[part 3 of 10: package /E40_Platform_System_SystemPackage/Components]
AUTOSAR XML (schema 4-2-1)
package /E40_Platform_System_SystemPackage/Components  (continued)
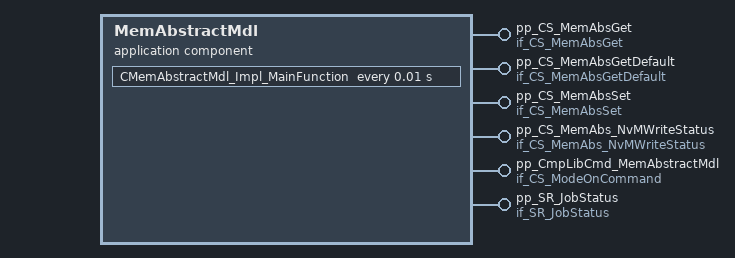
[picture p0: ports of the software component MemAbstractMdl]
  application sw component type MemAbstractMdl
    6 x provide port:
      pp_CS_MemAbsGet: provided-interface=if_CS_MemAbsGet
        provided-com-specs:
          operation=Get_BsConst_Audio_Element, queue-length=1
          operation=Get_BsConst_BsConst_Illumination_ReservedByte, queue-length=1
          operation=Get_BsConst_BsConst_Illumination_ReservedByte_SafeCopy1, queue-length=1
          operation=Get_BsConst_BsConst_Illumination_ReservedByte_SafeCopy2, queue-length=1
          operation=Get_BsConst_Communication_Element, queue-length=1
          operation=Get_BsConst_Compensation_Line_Shift_b, queue-length=1
          operation=Get_BsConst_Compensation_Line_Shift_b_SafeCopy1, queue-length=1
          operation=Get_BsConst_Compensation_Line_Shift_b_SafeCopy2, queue-length=1
          operation=Get_BsConst_Compensation_Line_Slope_m, queue-length=1
          operation=Get_BsConst_Compensation_Line_Slope_m_SafeCopy1, queue-length=1
          operation=Get_BsConst_Compensation_Line_Slope_m_SafeCopy2, queue-length=1
          operation=Get_BsConst_Derating_Backlight_Disable, queue-length=1
          operation=Get_BsConst_Derating_Backlight_Disable_SafeCopy1, queue-length=1
          operation=Get_BsConst_Derating_Backlight_Disable_SafeCopy2, queue-length=1
          operation=Get_BsConst_Display_Illum_Max_Level, queue-length=1
          operation=Get_BsConst_Display_Illum_Max_Level_SafeCopy1, queue-length=1
          operation=Get_BsConst_Display_Illum_Max_Level_SafeCopy2, queue-length=1
          operation=Get_BsConst_EngOffTimer_Element, queue-length=1
          operation=Get_BsConst_FuelGauge_Element, queue-length=1
          operation=Get_BsConst_Lookup_Curve_HotSpot_Coef_X, queue-length=1
          operation=Get_BsConst_Lookup_Curve_HotSpot_Coef_X_SafeCopy1, queue-length=1
          operation=Get_BsConst_Lookup_Curve_HotSpot_Coef_X_SafeCopy2, queue-length=1
          operation=Get_BsConst_Lookup_Curve_HotSpot_Coef_Y, queue-length=1
          operation=Get_BsConst_Lookup_Curve_HotSpot_Coef_Y_SafeCopy1, queue-length=1
          operation=Get_BsConst_Lookup_Curve_HotSpot_Coef_Y_SafeCopy2, queue-length=1
          operation=Get_BsConst_OilGauge_Element, queue-length=1
          operation=Get_BsConst_PCB_Temperature_Sensor_Conv, queue-length=1
          operation=Get_BsConst_PCB_Temperature_Sensor_Conv_SafeCopy1, queue-length=1
          operation=Get_BsConst_PCB_Temperature_Sensor_Conv_SafeCopy2, queue-length=1
          operation=Get_BsConst_PWM_boost_bypass_duty, queue-length=1
          operation=Get_BsConst_PWM_boost_bypass_duty_SafeCopy1, queue-length=1
          operation=Get_BsConst_PWM_boost_bypass_duty_SafeCopy2, queue-length=1
          operation=Get_BsConst_PowerGauge_Element, queue-length=1
          operation=Get_BsConst_Power_Element, queue-length=1
          operation=Get_BsConst_RealTimeClock_Element, queue-length=1
          operation=Get_BsConst_ServiceReminder_Element, queue-length=1
          operation=Get_BsConst_SpeedoGauge_Element, queue-length=1
          operation=Get_BsConst_TachoGauge_Element, queue-length=1
          operation=Get_BsConst_TempGauge_Element, queue-length=1
          operation=Get_BsConst_Temp_Threshold_Hysteresis_Derating, queue-length=1
          operation=Get_BsConst_Temp_Threshold_Hysteresis_Derating_SafeCopy1, queue-length=1
          operation=Get_BsConst_Temp_Threshold_Hysteresis_Derating_SafeCopy2, queue-length=1
          operation=Get_BsConst_Temperature_Sensor_Conv, queue-length=1
          operation=Get_BsConst_Temperature_Sensor_Conv_SafeCopy1, queue-length=1
          operation=Get_BsConst_Temperature_Sensor_Conv_SafeCopy2, queue-length=1
          operation=Get_BsConst_TripComputer_Element, queue-length=1
          operation=Get_BsConst_Warning_Element, queue-length=1
          operation=Get_BsCys_Certicificate_Element, queue-length=1
          operation=Get_BsDiag_Dtc_Element, queue-length=1
          operation=Get_BsDiag_ErrorRecord_Element, queue-length=1
          operation=Get_BsReten_Audio_Element, queue-length=1
          operation=Get_BsReten_Communication_Element, queue-length=1
          operation=Get_BsReten_Display_Element, queue-length=1
          operation=Get_BsReten_Gauges_Element, queue-length=1
          operation=Get_BsReten_Illumination_Element, queue-length=1
          operation=Get_BsReten_Odometer_Element, queue-length=1
          operation=Get_BsReten_Personalization_Element, queue-length=1
          operation=Get_BsReten_Power_Element, queue-length=1
          operation=Get_BsReten_RealTimeClock_Element, queue-length=1
          operation=Get_BsReten_Tripcomputer_Element, queue-length=1
          operation=Get_BsReten_VisDlt_Element, queue-length=1
          operation=Get_BsReten_Warning_Element, queue-length=1
          operation=Get_BsRt_CusDlt_Element, queue-length=1
          operation=Get_BsRt_FuelGauge_Element, queue-length=1
          operation=Get_BsRt_Illumination_Element, queue-length=1
          operation=Get_BsRt_Odometer_Element, queue-length=1
          operation=Get_BsRt_OilGauge_Element, queue-length=1
          operation=Get_BsRt_Personalization_Element, queue-length=1
          operation=Get_BsRt_PowerGauge_Element, queue-length=1
          operation=Get_BsRt_RealTimeClock_Element, queue-length=1
          operation=Get_BsRt_SpeedoGauge_Element, queue-length=1
          operation=Get_BsRt_TachoGauge_Element, queue-length=1
          operation=Get_BsRt_TempGauge_Element, queue-length=1
          operation=Get_BsRt_TripComputer_Element, queue-length=1
          operation=Get_BsRt_Warning_Element, queue-length=1
          operation=Get_BsShare_AssemblyManufacturingDate, queue-length=1
          operation=Get_BsShare_AssemblyPlantNumber, queue-length=1
          operation=Get_BsShare_EcuPartNumber_Element, queue-length=1
          operation=Get_BsShare_HWModification, queue-length=1
          operation=Get_BsShare_PCBSerialNumber, queue-length=1
          operation=Get_BsShare_ProductSerialNumber, queue-length=1
          operation=Get_BsShare_SMTManufacturingDate, queue-length=1
          operation=Get_BsShare_SMTPlantNumber, queue-length=1
          operation=Get_BsShare_SwUpdFotaFinPrint_Element, queue-length=1
          operation=Get_BsShare_SwUpdFotaMode_Element, queue-length=1
          operation=Get_BsShare_SwUpdFotaStatus_Element, queue-length=1
          operation=Get_BsShare_SwUpdFotadecrypt_Element, queue-length=1
          operation=Get_BsShare_SwUpdReflash_Element, queue-length=1
          operation=Get_BsShare_VehicleConfig_Element, queue-length=1
          operation=Get_BsShare_VisMeet_EOLEntry_Element, queue-length=1
          operation=Get_BsShare_VisMeet_Element, queue-length=1
          operation=Get_BsShare_VisteonPCBPartNumber, queue-length=1
          operation=Get_BsShare_VisteonPartNumber, queue-length=1
          operation=Get_RefCys_Certicificate1_Element, queue-length=1
          operation=Get_RefCys_Certicificate_Element, queue-length=1
      pp_CS_MemAbsGetDefault: provided-interface=if_CS_MemAbsGetDefault
        provided-com-specs:
          operation=Get_Default_BsConst_Audio_Element, queue-length=1
          operation=Get_Default_BsConst_BsConst_Illumination_ReservedByte, queue-length=1
          operation=Get_Default_BsConst_BsConst_Illumination_ReservedByte_SafeCopy1, queue-length=1
          operation=Get_Default_BsConst_BsConst_Illumination_ReservedByte_SafeCopy2, queue-length=1
          operation=Get_Default_BsConst_Communication_Element, queue-length=1
          operation=Get_Default_BsConst_Compensation_Line_Shift_b, queue-length=1
          operation=Get_Default_BsConst_Compensation_Line_Shift_b_SafeCopy1, queue-length=1
          operation=Get_Default_BsConst_Compensation_Line_Shift_b_SafeCopy2, queue-length=1
          operation=Get_Default_BsConst_Compensation_Line_Slope_m, queue-length=1
          operation=Get_Default_BsConst_Compensation_Line_Slope_m_SafeCopy1, queue-length=1
          operation=Get_Default_BsConst_Compensation_Line_Slope_m_SafeCopy2, queue-length=1
          operation=Get_Default_BsConst_Derating_Backlight_Disable, queue-length=1
          operation=Get_Default_BsConst_Derating_Backlight_Disable_SafeCopy1, queue-length=1
          operation=Get_Default_BsConst_Derating_Backlight_Disable_SafeCopy2, queue-length=1
          operation=Get_Default_BsConst_Display_Illum_Max_Level, queue-length=1
          operation=Get_Default_BsConst_Display_Illum_Max_Level_SafeCopy1, queue-length=1
          operation=Get_Default_BsConst_Display_Illum_Max_Level_SafeCopy2, queue-length=1
          operation=Get_Default_BsConst_EngOffTimer_Element, queue-length=1
          operation=Get_Default_BsConst_FuelGauge_Element, queue-length=1
          operation=Get_Default_BsConst_Lookup_Curve_HotSpot_Coef_X, queue-length=1
          operation=Get_Default_BsConst_Lookup_Curve_HotSpot_Coef_X_SafeCopy1, queue-length=1
          operation=Get_Default_BsConst_Lookup_Curve_HotSpot_Coef_X_SafeCopy2, queue-length=1
          operation=Get_Default_BsConst_Lookup_Curve_HotSpot_Coef_Y, queue-length=1
          operation=Get_Default_BsConst_Lookup_Curve_HotSpot_Coef_Y_SafeCopy1, queue-length=1
          operation=Get_Default_BsConst_Lookup_Curve_HotSpot_Coef_Y_SafeCopy2, queue-length=1
          operation=Get_Default_BsConst_OilGauge_Element, queue-length=1
          operation=Get_Default_BsConst_PCB_Temperature_Sensor_Conv, queue-length=1
          operation=Get_Default_BsConst_PCB_Temperature_Sensor_Conv_SafeCopy1, queue-length=1
          operation=Get_Default_BsConst_PCB_Temperature_Sensor_Conv_SafeCopy2, queue-length=1
          operation=Get_Default_BsConst_PWM_boost_bypass_duty, queue-length=1
          operation=Get_Default_BsConst_PWM_boost_bypass_duty_SafeCopy1, queue-length=1
          operation=Get_Default_BsConst_PWM_boost_bypass_duty_SafeCopy2, queue-length=1
          operation=Get_Default_BsConst_PowerGauge_Element, queue-length=1
          operation=Get_Default_BsConst_Power_Element, queue-length=1
          operation=Get_Default_BsConst_RealTimeClock_Element, queue-length=1
          operation=Get_Default_BsConst_ServiceReminder_Element, queue-length=1
          operation=Get_Default_BsConst_SpeedoGauge_Element, queue-length=1
          operation=Get_Default_BsConst_TachoGauge_Element, queue-length=1
          operation=Get_Default_BsConst_TempGauge_Element, queue-length=1
          operation=Get_Default_BsConst_Temp_Threshold_Hysteresis_Derating, queue-length=1
          operation=Get_Default_BsConst_Temp_Threshold_Hysteresis_Derating_SafeCopy1, queue-length=1
          operation=Get_Default_BsConst_Temp_Threshold_Hysteresis_Derating_SafeCopy2, queue-length=1
          operation=Get_Default_BsConst_Temperature_Sensor_Conv, queue-length=1
          operation=Get_Default_BsConst_Temperature_Sensor_Conv_SafeCopy1, queue-length=1
          operation=Get_Default_BsConst_Temperature_Sensor_Conv_SafeCopy2, queue-length=1
          operation=Get_Default_BsConst_TripComputer_Element, queue-length=1
          operation=Get_Default_BsConst_Warning_Element, queue-length=1
          operation=Get_Default_BsCys_Certicificate_Element, queue-length=1
          operation=Get_Default_BsDiag_Dtc_Element, queue-length=1
          operation=Get_Default_BsDiag_ErrorRecord_Element, queue-length=1
          operation=Get_Default_BsReten_Audio_Element, queue-length=1
          operation=Get_Default_BsReten_Communication_Element, queue-length=1
          operation=Get_Default_BsReten_Display_Element, queue-length=1
          operation=Get_Default_BsReten_Gauges_Element, queue-length=1
          operation=Get_Default_BsReten_Illumination_Element, queue-length=1
          operation=Get_Default_BsReten_Odometer_Element, queue-length=1
          operation=Get_Default_BsReten_Personalization_Element, queue-length=1
          operation=Get_Default_BsReten_Power_Element, queue-length=1
          operation=Get_Default_BsReten_RealTimeClock_Element, queue-length=1
          operation=Get_Default_BsReten_Tripcomputer_Element, queue-length=1
          operation=Get_Default_BsReten_VisDlt_Element, queue-length=1
          operation=Get_Default_BsReten_Warning_Element, queue-length=1
          operation=Get_Default_BsRt_CusDlt_Element, queue-length=1
          operation=Get_Default_BsRt_FuelGauge_Element, queue-length=1
          operation=Get_Default_BsRt_Illumination_Element, queue-length=1
          operation=Get_Default_BsRt_Odometer_Element, queue-length=1
          operation=Get_Default_BsRt_OilGauge_Element, queue-length=1
          operation=Get_Default_BsRt_Personalization_Element, queue-length=1
          operation=Get_Default_BsRt_PowerGauge_Element, queue-length=1
          operation=Get_Default_BsRt_RealTimeClock_Element, queue-length=1
          operation=Get_Default_BsRt_SpeedoGauge_Element, queue-length=1
          operation=Get_Default_BsRt_TachoGauge_Element, queue-length=1
          operation=Get_Default_BsRt_TempGauge_Element, queue-length=1
          operation=Get_Default_BsRt_TripComputer_Element, queue-length=1
          operation=Get_Default_BsRt_Warning_Element, queue-length=1
          operation=Get_Default_BsShare_AssemblyManufacturingDate, queue-length=1
          operation=Get_Default_BsShare_AssemblyPlantNumber, queue-length=1
          operation=Get_Default_BsShare_EcuPartNumber_Element, queue-length=1
          operation=Get_Default_BsShare_HWModification, queue-length=1
          operation=Get_Default_BsShare_PCBSerialNumber, queue-length=1
          operation=Get_Default_BsShare_ProductSerialNumber, queue-length=1
          operation=Get_Default_BsShare_SMTManufacturingDate, queue-length=1
          operation=Get_Default_BsShare_SMTPlantNumber, queue-length=1
          operation=Get_Default_BsShare_SwUpdFotaFinPrint_Element, queue-length=1
          operation=Get_Default_BsShare_SwUpdFotaMode_Element, queue-length=1
          operation=Get_Default_BsShare_SwUpdFotaStatus_Element, queue-length=1
          operation=Get_Default_BsShare_SwUpdFotadecrypt_Element, queue-length=1
          operation=Get_Default_BsShare_SwUpdReflash_Element, queue-length=1
          operation=Get_Default_BsShare_VehicleConfig_Element, queue-length=1
          operation=Get_Default_BsShare_VisMeet_EOLEntry_Element, queue-length=1
          operation=Get_Default_BsShare_VisMeet_Element, queue-length=1
          operation=Get_Default_BsShare_VisteonPCBPartNumber, queue-length=1
          operation=Get_Default_BsShare_VisteonPartNumber, queue-length=1
          operation=Get_Default_RefCys_Certicificate1_Element, queue-length=1
          operation=Get_Default_RefCys_Certicificate_Element, queue-length=1
      pp_CS_MemAbsSet: provided-interface=if_CS_MemAbsSet
        provided-com-specs:
          operation=Set_BsConst_Audio_Element, queue-length=1
          operation=Set_BsConst_BsConst_Illumination_ReservedByte, queue-length=1
          operation=Set_BsConst_BsConst_Illumination_ReservedByte_SafeCopy1, queue-length=1
          operation=Set_BsConst_BsConst_Illumination_ReservedByte_SafeCopy2, queue-length=1
          operation=Set_BsConst_Communication_Element, queue-length=1
          operation=Set_BsConst_Compensation_Line_Shift_b, queue-length=1
          operation=Set_BsConst_Compensation_Line_Shift_b_SafeCopy1, queue-length=1
          operation=Set_BsConst_Compensation_Line_Shift_b_SafeCopy2, queue-length=1
          operation=Set_BsConst_Compensation_Line_Slope_m, queue-length=1
          operation=Set_BsConst_Compensation_Line_Slope_m_SafeCopy1, queue-length=1
          operation=Set_BsConst_Compensation_Line_Slope_m_SafeCopy2, queue-length=1
          operation=Set_BsConst_Derating_Backlight_Disable, queue-length=1
          operation=Set_BsConst_Derating_Backlight_Disable_SafeCopy1, queue-length=1
          operation=Set_BsConst_Derating_Backlight_Disable_SafeCopy2, queue-length=1
          operation=Set_BsConst_Display_Illum_Max_Level, queue-length=1
          operation=Set_BsConst_Display_Illum_Max_Level_SafeCopy1, queue-length=1
          operation=Set_BsConst_Display_Illum_Max_Level_SafeCopy2, queue-length=1
          operation=Set_BsConst_EngOffTimer_Element, queue-length=1
          operation=Set_BsConst_FuelGauge_Element, queue-length=1
          operation=Set_BsConst_Lookup_Curve_HotSpot_Coef_X, queue-length=1
          operation=Set_BsConst_Lookup_Curve_HotSpot_Coef_X_SafeCopy1, queue-length=1
          operation=Set_BsConst_Lookup_Curve_HotSpot_Coef_X_SafeCopy2, queue-length=1
          operation=Set_BsConst_Lookup_Curve_HotSpot_Coef_Y, queue-length=1
          operation=Set_BsConst_Lookup_Curve_HotSpot_Coef_Y_SafeCopy1, queue-length=1
          operation=Set_BsConst_Lookup_Curve_HotSpot_Coef_Y_SafeCopy2, queue-length=1
          operation=Set_BsConst_OilGauge_Element, queue-length=1
          operation=Set_BsConst_PCB_Temperature_Sensor_Conv, queue-length=1
          operation=Set_BsConst_PCB_Temperature_Sensor_Conv_SafeCopy1, queue-length=1
          operation=Set_BsConst_PCB_Temperature_Sensor_Conv_SafeCopy2, queue-length=1
          operation=Set_BsConst_PWM_boost_bypass_duty, queue-length=1
          operation=Set_BsConst_PWM_boost_bypass_duty_SafeCopy1, queue-length=1
          operation=Set_BsConst_PWM_boost_bypass_duty_SafeCopy2, queue-length=1
          operation=Set_BsConst_PowerGauge_Element, queue-length=1
          operation=Set_BsConst_Power_Element, queue-length=1
          operation=Set_BsConst_RealTimeClock_Element, queue-length=1
          operation=Set_BsConst_ServiceReminder_Element, queue-length=1
          operation=Set_BsConst_SpeedoGauge_Element, queue-length=1
          operation=Set_BsConst_TachoGauge_Element, queue-length=1
          operation=Set_BsConst_TempGauge_Element, queue-length=1
          operation=Set_BsConst_Temp_Threshold_Hysteresis_Derating, queue-length=1
          operation=Set_BsConst_Temp_Threshold_Hysteresis_Derating_SafeCopy1, queue-length=1
          operation=Set_BsConst_Temp_Threshold_Hysteresis_Derating_SafeCopy2, queue-length=1
          operation=Set_BsConst_Temperature_Sensor_Conv, queue-length=1
          operation=Set_BsConst_Temperature_Sensor_Conv_SafeCopy1, queue-length=1
          operation=Set_BsConst_Temperature_Sensor_Conv_SafeCopy2, queue-length=1
          operation=Set_BsConst_TripComputer_Element, queue-length=1
          operation=Set_BsConst_Warning_Element, queue-length=1
          operation=Set_BsCys_Certicificate_Element, queue-length=1
          operation=Set_BsDiag_Dtc_Element, queue-length=1
          operation=Set_BsDiag_ErrorRecord_Element, queue-length=1
          operation=Set_BsReten_Audio_Element, queue-length=1
          operation=Set_BsReten_Communication_Element, queue-length=1
          operation=Set_BsReten_Display_Element, queue-length=1
          operation=Set_BsReten_Gauges_Element, queue-length=1
          operation=Set_BsReten_Illumination_Element, queue-length=1
          operation=Set_BsReten_Odometer_Element, queue-length=1
          operation=Set_BsReten_Personalization_Element, queue-length=1
          operation=Set_BsReten_Power_Element, queue-length=1
          operation=Set_BsReten_RealTimeClock_Element, queue-length=1
          operation=Set_BsReten_Tripcomputer_Element, queue-length=1
          operation=Set_BsReten_VisDlt_Element, queue-length=1
          operation=Set_BsReten_Warning_Element, queue-length=1
          operation=Set_BsRt_CusDlt_Element, queue-length=1
          operation=Set_BsRt_FuelGauge_Element, queue-length=1
          operation=Set_BsRt_Illumination_Element, queue-length=1
          operation=Set_BsRt_Odometer_Element, queue-length=1
          operation=Set_BsRt_OilGauge_Element, queue-length=1
          operation=Set_BsRt_Personalization_Element, queue-length=1
          operation=Set_BsRt_PowerGauge_Element, queue-length=1
          operation=Set_BsRt_RealTimeClock_Element, queue-length=1
          operation=Set_BsRt_SpeedoGauge_Element, queue-length=1
          operation=Set_BsRt_TachoGauge_Element, queue-length=1
          operation=Set_BsRt_TempGauge_Element, queue-length=1
          operation=Set_BsRt_TripComputer_Element, queue-length=1
          operation=Set_BsRt_Warning_Element, queue-length=1
          operation=Set_BsShare_AssemblyManufacturingDate, queue-length=1
          operation=Set_BsShare_AssemblyPlantNumber, queue-length=1
          operation=Set_BsShare_EcuPartNumber_Element, queue-length=1
          operation=Set_BsShare_HWModification, queue-length=1
          operation=Set_BsShare_PCBSerialNumber, queue-length=1
          operation=Set_BsShare_ProductSerialNumber, queue-length=1
          operation=Set_BsShare_SMTManufacturingDate, queue-length=1
          operation=Set_BsShare_SMTPlantNumber, queue-length=1
          operation=Set_BsShare_SwUpdFotaFinPrint_Element, queue-length=1
          operation=Set_BsShare_SwUpdFotaMode_Element, queue-length=1
          operation=Set_BsShare_SwUpdFotaStatus_Element, queue-length=1
          operation=Set_BsShare_SwUpdFotadecrypt_Element, queue-length=1
          operation=Set_BsShare_SwUpdReflash_Element, queue-length=1
          operation=Set_BsShare_VehicleConfig_Element, queue-length=1
          operation=Set_BsShare_VisMeet_EOLEntry_Element, queue-length=1
          operation=Set_BsShare_VisMeet_Element, queue-length=1
          operation=Set_BsShare_VisteonPCBPartNumber, queue-length=1
          operation=Set_BsShare_VisteonPartNumber, queue-length=1
          operation=Set_RefCys_Certicificate1_Element, queue-length=1
          operation=Set_RefCys_Certicificate_Element, queue-length=1
      pp_CS_MemAbs_NvMWriteStatus: server-com-spec{operation=NvmWriteStatus, queue-length=1}, provided-interface=if_CS_MemAbs_NvMWriteStatus
      pp_CmpLibCmd_MemAbstractMdl: server-com-spec{operation=Impl_OnCommand, queue-length=1}, provided-interface=if_CS_ModeOnCommand
      pp_SR_JobStatus: provided-interface=if_SR_JobStatus
        provided-com-specs:
          data-element=JobStatus_BsConst_Audio_Element, init-value=constant-reference=MemAbstractMdlJobStatus_BsConst_Audio_ElementValue0
          data-element=JobStatus_BsConst_BsConst_Illumination_ReservedByte, init-value=constant-reference=MemAbstractMdlJobStatus_BsConst_BsConst_Illumination_ReservedByteValue0
          data-element=JobStatus_BsConst_BsConst_Illumination_ReservedByte_SafeCopy1, init-value=constant-reference=MemAbstractMdlJobStatus_BsConst_BsConst_Illumination_ReservedByte_SafeCopy1Value0
          data-element=JobStatus_BsConst_BsConst_Illumination_ReservedByte_SafeCopy2, init-value=constant-reference=MemAbstractMdlJobStatus_BsConst_BsConst_Illumination_ReservedByte_SafeCopy2Value0
          data-element=JobStatus_BsConst_Communication_Element, init-value=constant-reference=MemAbstractMdlJobStatus_BsConst_Communication_ElementValue0
          data-element=JobStatus_BsConst_Compensation_Line_Shift_b, init-value=constant-reference=MemAbstractMdlJobStatus_BsConst_Compensation_Line_Shift_bValue0
          data-element=JobStatus_BsConst_Compensation_Line_Shift_b_SafeCopy1, init-value=constant-reference=MemAbstractMdlJobStatus_BsConst_Compensation_Line_Shift_b_SafeCopy1Value0
          data-element=JobStatus_BsConst_Compensation_Line_Shift_b_SafeCopy2, init-value=constant-reference=MemAbstractMdlJobStatus_BsConst_Compensation_Line_Shift_b_SafeCopy2Value0
          data-element=JobStatus_BsConst_Compensation_Line_Slope_m, init-value=constant-reference=MemAbstractMdlJobStatus_BsConst_Compensation_Line_Slope_mValue0
          data-element=JobStatus_BsConst_Compensation_Line_Slope_m_SafeCopy1, init-value=constant-reference=MemAbstractMdlJobStatus_BsConst_Compensation_Line_Slope_m_SafeCopy1Value0
          data-element=JobStatus_BsConst_Compensation_Line_Slope_m_SafeCopy2, init-value=constant-reference=MemAbstractMdlJobStatus_BsConst_Compensation_Line_Slope_m_SafeCopy2Value0
          data-element=JobStatus_BsConst_Derating_Backlight_Disable, init-value=constant-reference=MemAbstractMdlJobStatus_BsConst_Derating_Backlight_DisableValue0
          data-element=JobStatus_BsConst_Derating_Backlight_Disable_SafeCopy1, init-value=constant-reference=MemAbstractMdlJobStatus_BsConst_Derating_Backlight_Disable_SafeCopy1Value0
          data-element=JobStatus_BsConst_Derating_Backlight_Disable_SafeCopy2, init-value=constant-reference=MemAbstractMdlJobStatus_BsConst_Derating_Backlight_Disable_SafeCopy2Value0
          data-element=JobStatus_BsConst_Display_Illum_Max_Level, init-value=constant-reference=MemAbstractMdlJobStatus_BsConst_Display_Illum_Max_LevelValue0
          data-element=JobStatus_BsConst_Display_Illum_Max_Level_SafeCopy1, init-value=constant-reference=MemAbstractMdlJobStatus_BsConst_Display_Illum_Max_Level_SafeCopy1Value0
          data-element=JobStatus_BsConst_Display_Illum_Max_Level_SafeCopy2, init-value=constant-reference=MemAbstractMdlJobStatus_BsConst_Display_Illum_Max_Level_SafeCopy2Value0
          data-element=JobStatus_BsConst_EngOffTimer_Element, init-value=constant-reference=MemAbstractMdlJobStatus_BsConst_EngOffTimer_ElementValue0
          data-element=JobStatus_BsConst_FuelGauge_Element, init-value=constant-reference=MemAbstractMdlJobStatus_BsConst_FuelGauge_ElementValue0
          data-element=JobStatus_BsConst_Lookup_Curve_HotSpot_Coef_X, init-value=constant-reference=MemAbstractMdlJobStatus_BsConst_Lookup_Curve_HotSpot_Coef_XValue0
          data-element=JobStatus_BsConst_Lookup_Curve_HotSpot_Coef_X_SafeCopy1, init-value=constant-reference=MemAbstractMdlJobStatus_BsConst_Lookup_Curve_HotSpot_Coef_X_SafeCopy1Value0
          data-element=JobStatus_BsConst_Lookup_Curve_HotSpot_Coef_X_SafeCopy2, init-value=constant-reference=MemAbstractMdlJobStatus_BsConst_Lookup_Curve_HotSpot_Coef_X_SafeCopy2Value0
          data-element=JobStatus_BsConst_Lookup_Curve_HotSpot_Coef_Y, init-value=constant-reference=MemAbstractMdlJobStatus_BsConst_Lookup_Curve_HotSpot_Coef_YValue0
          data-element=JobStatus_BsConst_Lookup_Curve_HotSpot_Coef_Y_SafeCopy1, init-value=constant-reference=MemAbstractMdlJobStatus_BsConst_Lookup_Curve_HotSpot_Coef_Y_SafeCopy1Value0
          data-element=JobStatus_BsConst_Lookup_Curve_HotSpot_Coef_Y_SafeCopy2, init-value=constant-reference=MemAbstractMdlJobStatus_BsConst_Lookup_Curve_HotSpot_Coef_Y_SafeCopy2Value0
          data-element=JobStatus_BsConst_OilGauge_Element, init-value=constant-reference=MemAbstractMdlJobStatus_BsConst_OilGauge_ElementValue0
          data-element=JobStatus_BsConst_PCB_Temperature_Sensor_Conv, init-value=constant-reference=MemAbstractMdlJobStatus_BsConst_PCB_Temperature_Sensor_ConvValue0
          data-element=JobStatus_BsConst_PCB_Temperature_Sensor_Conv_SafeCopy1, init-value=constant-reference=MemAbstractMdlJobStatus_BsConst_PCB_Temperature_Sensor_Conv_SafeCopy1Value0
          data-element=JobStatus_BsConst_PCB_Temperature_Sensor_Conv_SafeCopy2, init-value=constant-reference=MemAbstractMdlJobStatus_BsConst_PCB_Temperature_Sensor_Conv_SafeCopy2Value0
          data-element=JobStatus_BsConst_PWM_boost_bypass_duty, init-value=constant-reference=MemAbstractMdlJobStatus_BsConst_PWM_boost_bypass_dutyValue0
          data-element=JobStatus_BsConst_PWM_boost_bypass_duty_SafeCopy1, init-value=constant-reference=MemAbstractMdlJobStatus_BsConst_PWM_boost_bypass_duty_SafeCopy1Value0
          data-element=JobStatus_BsConst_PWM_boost_bypass_duty_SafeCopy2, init-value=constant-reference=MemAbstractMdlJobStatus_BsConst_PWM_boost_bypass_duty_SafeCopy2Value0
          data-element=JobStatus_BsConst_PowerGauge_Element, init-value=constant-reference=MemAbstractMdlJobStatus_BsConst_PowerGauge_ElementValue0
          data-element=JobStatus_BsConst_Power_Element, init-value=constant-reference=MemAbstractMdlJobStatus_BsConst_Power_ElementValue0
          data-element=JobStatus_BsConst_RealTimeClock_Element, init-value=constant-reference=MemAbstractMdlJobStatus_BsConst_RealTimeClock_ElementValue0
          data-element=JobStatus_BsConst_ServiceReminder_Element, init-value=constant-reference=MemAbstractMdlJobStatus_BsConst_ServiceReminder_ElementValue0
          data-element=JobStatus_BsConst_SpeedoGauge_Element, init-value=constant-reference=MemAbstractMdlJobStatus_BsConst_SpeedoGauge_ElementValue0
          data-element=JobStatus_BsConst_TachoGauge_Element, init-value=constant-reference=MemAbstractMdlJobStatus_BsConst_TachoGauge_ElementValue0
          data-element=JobStatus_BsConst_TempGauge_Element, init-value=constant-reference=MemAbstractMdlJobStatus_BsConst_TempGauge_ElementValue0
          data-element=JobStatus_BsConst_Temp_Threshold_Hysteresis_Derating, init-value=constant-reference=MemAbstractMdlJobStatus_BsConst_Temp_Threshold_Hysteresis_DeratingValue0
          data-element=JobStatus_BsConst_Temp_Threshold_Hysteresis_Derating_SafeCopy1, init-value=constant-reference=MemAbstractMdlJobStatus_BsConst_Temp_Threshold_Hysteresis_Derating_SafeCopy1Value0
          data-element=JobStatus_BsConst_Temp_Threshold_Hysteresis_Derating_SafeCopy2, init-value=constant-reference=MemAbstractMdlJobStatus_BsConst_Temp_Threshold_Hysteresis_Derating_SafeCopy2Value0
          data-element=JobStatus_BsConst_Temperature_Sensor_Conv, init-value=constant-reference=MemAbstractMdlJobStatus_BsConst_Temperature_Sensor_ConvValue0
          data-element=JobStatus_BsConst_Temperature_Sensor_Conv_SafeCopy1, init-value=constant-reference=MemAbstractMdlJobStatus_BsConst_Temperature_Sensor_Conv_SafeCopy1Value0
          data-element=JobStatus_BsConst_Temperature_Sensor_Conv_SafeCopy2, init-value=constant-reference=MemAbstractMdlJobStatus_BsConst_Temperature_Sensor_Conv_SafeCopy2Value0
          data-element=JobStatus_BsConst_TripComputer_Element, init-value=constant-reference=MemAbstractMdlJobStatus_BsConst_TripComputer_ElementValue0
          data-element=JobStatus_BsConst_Warning_Element, init-value=constant-reference=MemAbstractMdlJobStatus_BsConst_Warning_ElementValue0
          data-element=JobStatus_BsCys_Certicificate_Element, init-value=constant-reference=MemAbstractMdlJobStatus_BsCys_Certicificate_ElementValue0
          data-element=JobStatus_BsDiag_Dtc_Element, init-value=constant-reference=MemAbstractMdlJobStatus_BsDiag_Dtc_ElementValue0
          data-element=JobStatus_BsDiag_ErrorRecord_Element, init-value=constant-reference=MemAbstractMdlJobStatus_BsDiag_ErrorRecord_ElementValue0
          data-element=JobStatus_BsReten_Audio_Element, init-value=constant-reference=MemAbstractMdlJobStatus_BsReten_Audio_ElementValue0
          data-element=JobStatus_BsReten_Communication_Element, init-value=constant-reference=MemAbstractMdlJobStatus_BsReten_Communication_ElementValue0
          data-element=JobStatus_BsReten_Display_Element, init-value=constant-reference=MemAbstractMdlJobStatus_BsReten_Display_ElementValue0
          data-element=JobStatus_BsReten_Gauges_Element, init-value=constant-reference=MemAbstractMdlJobStatus_BsReten_Gauges_ElementValue0
          data-element=JobStatus_BsReten_Illumination_Element, init-value=constant-reference=MemAbstractMdlJobStatus_BsReten_Illumination_ElementValue0
          data-element=JobStatus_BsReten_Odometer_Element, init-value=constant-reference=MemAbstractMdlJobStatus_BsReten_Odometer_ElementValue0
          data-element=JobStatus_BsReten_Personalization_Element, init-value=constant-reference=MemAbstractMdlJobStatus_BsReten_Personalization_ElementValue0
          data-element=JobStatus_BsReten_Power_Element, init-value=constant-reference=MemAbstractMdlJobStatus_BsReten_Power_ElementValue0
          data-element=JobStatus_BsReten_RealTimeClock_Element, init-value=constant-reference=MemAbstractMdlJobStatus_BsReten_RealTimeClock_ElementValue0
          data-element=JobStatus_BsReten_Tripcomputer_Element, init-value=constant-reference=MemAbstractMdlJobStatus_BsReten_Tripcomputer_ElementValue0
          data-element=JobStatus_BsReten_VisDlt_Element, init-value=constant-reference=MemAbstractMdlJobStatus_BsReten_VisDlt_ElementValue0
          data-element=JobStatus_BsReten_Warning_Element, init-value=constant-reference=MemAbstractMdlJobStatus_BsReten_Warning_ElementValue0
          data-element=JobStatus_BsRt_CusDlt_Element, init-value=constant-reference=MemAbstractMdlJobStatus_BsRt_CusDlt_ElementValue0
          data-element=JobStatus_BsRt_FuelGauge_Element, init-value=constant-reference=MemAbstractMdlJobStatus_BsRt_FuelGauge_ElementValue0
          data-element=JobStatus_BsRt_Illumination_Element, init-value=constant-reference=MemAbstractMdlJobStatus_BsRt_Illumination_ElementValue0
          data-element=JobStatus_BsRt_Odometer_Element, init-value=constant-reference=MemAbstractMdlJobStatus_BsRt_Odometer_ElementValue0
          data-element=JobStatus_BsRt_OilGauge_Element, init-value=constant-reference=MemAbstractMdlJobStatus_BsRt_OilGauge_ElementValue0
          data-element=JobStatus_BsRt_Personalization_Element, init-value=constant-reference=MemAbstractMdlJobStatus_BsRt_Personalization_ElementValue0
          data-element=JobStatus_BsRt_PowerGauge_Element, init-value=constant-reference=MemAbstractMdlJobStatus_BsRt_PowerGauge_ElementValue0
          data-element=JobStatus_BsRt_RealTimeClock_Element, init-value=constant-reference=MemAbstractMdlJobStatus_BsRt_RealTimeClock_ElementValue0
          data-element=JobStatus_BsRt_SpeedoGauge_Element, init-value=constant-reference=MemAbstractMdlJobStatus_BsRt_SpeedoGauge_ElementValue0
          data-element=JobStatus_BsRt_TachoGauge_Element, init-value=constant-reference=MemAbstractMdlJobStatus_BsRt_TachoGauge_ElementValue0
          data-element=JobStatus_BsRt_TempGauge_Element, init-value=constant-reference=MemAbstractMdlJobStatus_BsRt_TempGauge_ElementValue0
          data-element=JobStatus_BsRt_TripComputer_Element, init-value=constant-reference=MemAbstractMdlJobStatus_BsRt_TripComputer_ElementValue0
          data-element=JobStatus_BsRt_Warning_Element, init-value=constant-reference=MemAbstractMdlJobStatus_BsRt_Warning_ElementValue0
          data-element=JobStatus_BsShare_AssemblyManufacturingDate, init-value=constant-reference=MemAbstractMdlJobStatus_BsShare_AssemblyManufacturingDateValue0
          data-element=JobStatus_BsShare_AssemblyPlantNumber, init-value=constant-reference=MemAbstractMdlJobStatus_BsShare_AssemblyPlantNumberValue0
          data-element=JobStatus_BsShare_EcuPartNumber_Element, init-value=constant-reference=MemAbstractMdlJobStatus_BsShare_EcuPartNumber_ElementValue0
          data-element=JobStatus_BsShare_HWModification, init-value=constant-reference=MemAbstractMdlJobStatus_BsShare_HWModificationValue0
          data-element=JobStatus_BsShare_PCBSerialNumber, init-value=constant-reference=MemAbstractMdlJobStatus_BsShare_PCBSerialNumberValue0
          data-element=JobStatus_BsShare_ProductSerialNumber, init-value=constant-reference=MemAbstractMdlJobStatus_BsShare_ProductSerialNumberValue0
          data-element=JobStatus_BsShare_SMTManufacturingDate, init-value=constant-reference=MemAbstractMdlJobStatus_BsShare_SMTManufacturingDateValue0
          data-element=JobStatus_BsShare_SMTPlantNumber, init-value=constant-reference=MemAbstractMdlJobStatus_BsShare_SMTPlantNumberValue0
          data-element=JobStatus_BsShare_SwUpdFotaFinPrint_Element, init-value=constant-reference=MemAbstractMdlJobStatus_BsShare_SwUpdFotaFinPrint_ElementValue0
          data-element=JobStatus_BsShare_SwUpdFotaMode_Element, init-value=constant-reference=MemAbstractMdlJobStatus_BsShare_SwUpdFotaMode_ElementValue0
          data-element=JobStatus_BsShare_SwUpdFotaStatus_Element, init-value=constant-reference=MemAbstractMdlJobStatus_BsShare_SwUpdFotaStatus_ElementValue0
          data-element=JobStatus_BsShare_SwUpdFotadecrypt_Element, init-value=constant-reference=MemAbstractMdlJobStatus_BsShare_SwUpdFotadecrypt_ElementValue0
          data-element=JobStatus_BsShare_SwUpdReflash_Element, init-value=constant-reference=MemAbstractMdlJobStatus_BsShare_SwUpdReflash_ElementValue0
          data-element=JobStatus_BsShare_VehicleConfig_Element, init-value=constant-reference=MemAbstractMdlJobStatus_BsShare_VehicleConfig_ElementValue0
          data-element=JobStatus_BsShare_VisMeet_EOLEntry_Element, init-value=constant-reference=MemAbstractMdlJobStatus_BsShare_VisMeet_EOLEntry_ElementValue0
          data-element=JobStatus_BsShare_VisMeet_Element, init-value=constant-reference=MemAbstractMdlJobStatus_BsShare_VisMeet_ElementValue0
          data-element=JobStatus_BsShare_VisteonPCBPartNumber, init-value=constant-reference=MemAbstractMdlJobStatus_BsShare_VisteonPCBPartNumberValue0
          data-element=JobStatus_BsShare_VisteonPartNumber, init-value=constant-reference=MemAbstractMdlJobStatus_BsShare_VisteonPartNumberValue0
          data-element=JobStatus_RefCys_Certicificate1_Element, init-value=constant-reference=MemAbstractMdlJobStatus_RefCys_Certicificate1_ElementValue0
          data-element=JobStatus_RefCys_Certicificate_Element, init-value=constant-reference=MemAbstractMdlJobStatus_RefCys_Certicificate_ElementValue0
    behavior IB_MemAbstractMdl
      timing event TECMemAbstractMdl_Impl_MainFunction: start-on-event=CMemAbstractMdl_Impl_MainFunction, period=0.01
      287 x operation invoked event:
        OIE_pp_CmpLibCmd_MemAbstractMdl_CMemAbstractMdl_Impl_OnCommandTrigByImpl_OnCommand: start-on-event=CMemAbstractMdl_Impl_OnCommand, operation=pp_CmpLibCmd_MemAbstractMdl.Impl_OnCommand
        OIE_pp_CS_MemAbsGet_MemAbstractMdl_Get_BsConst_Audio_ElementTrigByGet_BsConst_Audio_Element: start-on-event=MemAbstractMdl_Get_BsConst_Audio_Element, operation=pp_CS_MemAbsGet.Get_BsConst_Audio_Element
        OperationInvokeEvent_1: start-on-event=MemAbstractMdl_Get_BsConst_BsConst_Illumination_ReservedByte, operation=pp_CS_MemAbsGet.Get_BsConst_BsConst_Illumination_ReservedByte
        OperationInvokeEvent_2: start-on-event=MemAbstractMdl_Get_BsConst_BsConst_Illumination_ReservedByte_SafeCopy1, operation=pp_CS_MemAbsGet.Get_BsConst_BsConst_Illumination_ReservedByte_SafeCopy1
        OperationInvokeEvent_3: start-on-event=MemAbstractMdl_Get_BsConst_BsConst_Illumination_ReservedByte_SafeCopy2, operation=pp_CS_MemAbsGet.Get_BsConst_BsConst_Illumination_ReservedByte_SafeCopy2
        OIE_pp_CS_MemAbsGet_MemAbstractMdl_Get_BsConst_Communication_ElementTrigByGet_BsConst_Communication_Element: start-on-event=MemAbstractMdl_Get_BsConst_Communication_Element, operation=pp_CS_MemAbsGet.Get_BsConst_Communication_Element
        OIE_pp_CS_MemAbsGet_MemAbstractMdl_Get_BsConst_Compensation_Line_Shift_bTrigByGet_BsConst_Compensation_Line_Shift_b: start-on-event=MemAbstractMdl_Get_BsConst_Compensation_Line_Shift_b, operation=pp_CS_MemAbsGet.Get_BsConst_Compensation_Line_Shift_b
        OperationInvokeEvent_4: start-on-event=MemAbstractMdl_Get_BsConst_Compensation_Line_Shift_b_SafeCopy1, operation=pp_CS_MemAbsGet.Get_BsConst_Compensation_Line_Shift_b_SafeCopy1
        OperationInvokeEvent_5: start-on-event=MemAbstractMdl_Get_BsConst_Compensation_Line_Shift_b_SafeCopy2, operation=pp_CS_MemAbsGet.Get_BsConst_Compensation_Line_Shift_b_SafeCopy2
        OIE_pp_CS_MemAbsGet_MemAbstractMdl_Get_BsConst_Compensation_Line_Slope_mTrigByGet_BsConst_Compensation_Line_Slope_m: start-on-event=MemAbstractMdl_Get_BsConst_Compensation_Line_Slope_m, operation=pp_CS_MemAbsGet.Get_BsConst_Compensation_Line_Slope_m
        OperationInvokeEvent_6: start-on-event=MemAbstractMdl_Get_BsConst_Compensation_Line_Slope_m_SafeCopy1, operation=pp_CS_MemAbsGet.Get_BsConst_Compensation_Line_Slope_m_SafeCopy1
        OperationInvokeEvent_7: start-on-event=MemAbstractMdl_Get_BsConst_Compensation_Line_Slope_m_SafeCopy2, operation=pp_CS_MemAbsGet.Get_BsConst_Compensation_Line_Slope_m_SafeCopy2
        OIE_pp_CS_MemAbsGet_MemAbstractMdl_Get_BsConst_Derating_Backlight_DisableTrigByGet_BsConst_Derating_Backlight_Disable: start-on-event=MemAbstractMdl_Get_BsConst_Derating_Backlight_Disable, operation=pp_CS_MemAbsGet.Get_BsConst_Derating_Backlight_Disable
        OperationInvokeEvent_8: start-on-event=MemAbstractMdl_Get_BsConst_Derating_Backlight_Disable_SafeCopy1, operation=pp_CS_MemAbsGet.Get_BsConst_Derating_Backlight_Disable_SafeCopy1
        OperationInvokeEvent_9: start-on-event=MemAbstractMdl_Get_BsConst_Derating_Backlight_Disable_SafeCopy2, operation=pp_CS_MemAbsGet.Get_BsConst_Derating_Backlight_Disable_SafeCopy2
        OIE_pp_CS_MemAbsGet_MemAbstractMdl_Get_BsConst_Display_Illum_Max_LevelTrigByGet_BsConst_Display_Illum_Max_Level: start-on-event=MemAbstractMdl_Get_BsConst_Display_Illum_Max_Level, operation=pp_CS_MemAbsGet.Get_BsConst_Display_Illum_Max_Level
        OperationInvokeEvent_10: start-on-event=MemAbstractMdl_Get_BsConst_Display_Illum_Max_Level_SafeCopy1, operation=pp_CS_MemAbsGet.Get_BsConst_Display_Illum_Max_Level_SafeCopy1
        OperationInvokeEvent_11: start-on-event=MemAbstractMdl_Get_BsConst_Display_Illum_Max_Level_SafeCopy2, operation=pp_CS_MemAbsGet.Get_BsConst_Display_Illum_Max_Level_SafeCopy2
        OIE_pp_CS_MemAbsGet_MemAbstractMdl_Get_BsConst_EngOffTimer_ElementTrigByGet_BsConst_EngOffTimer_Element: start-on-event=MemAbstractMdl_Get_BsConst_EngOffTimer_Element, operation=pp_CS_MemAbsGet.Get_BsConst_EngOffTimer_Element
        OIE_pp_CS_MemAbsGet_MemAbstractMdl_Get_BsConst_FuelGauge_ElementTrigByGet_BsConst_FuelGauge_Element: start-on-event=MemAbstractMdl_Get_BsConst_FuelGauge_Element, operation=pp_CS_MemAbsGet.Get_BsConst_FuelGauge_Element
        OIE_pp_CS_MemAbsGet_MemAbstractMdl_Get_BsConst_Lookup_Curve_HotSpot_Coef_XTrigByGet_BsConst_Lookup_Curve_HotSpot_Coef_X: start-on-event=MemAbstractMdl_Get_BsConst_Lookup_Curve_HotSpot_Coef_X, operation=pp_CS_MemAbsGet.Get_BsConst_Lookup_Curve_HotSpot_Coef_X
        OperationInvokeEvent_12: start-on-event=MemAbstractMdl_Get_BsConst_Lookup_Curve_HotSpot_Coef_X_SafeCopy1, operation=pp_CS_MemAbsGet.Get_BsConst_Lookup_Curve_HotSpot_Coef_X_SafeCopy1
        OperationInvokeEvent_13: start-on-event=MemAbstractMdl_Get_BsConst_Lookup_Curve_HotSpot_Coef_X_SafeCopy2, operation=pp_CS_MemAbsGet.Get_BsConst_Lookup_Curve_HotSpot_Coef_X_SafeCopy2
        OIE_pp_CS_MemAbsGet_MemAbstractMdl_Get_BsConst_Lookup_Curve_HotSpot_Coef_YTrigByGet_BsConst_Lookup_Curve_HotSpot_Coef_Y: start-on-event=MemAbstractMdl_Get_BsConst_Lookup_Curve_HotSpot_Coef_Y, operation=pp_CS_MemAbsGet.Get_BsConst_Lookup_Curve_HotSpot_Coef_Y
        OperationInvokeEvent_14: start-on-event=MemAbstractMdl_Get_BsConst_Lookup_Curve_HotSpot_Coef_Y_SafeCopy1, operation=pp_CS_MemAbsGet.Get_BsConst_Lookup_Curve_HotSpot_Coef_Y_SafeCopy1
        OperationInvokeEvent_15: start-on-event=MemAbstractMdl_Get_BsConst_Lookup_Curve_HotSpot_Coef_Y_SafeCopy2, operation=pp_CS_MemAbsGet.Get_BsConst_Lookup_Curve_HotSpot_Coef_Y_SafeCopy2
        OIE_pp_CS_MemAbsGet_MemAbstractMdl_Get_BsConst_OilGauge_ElementTrigByGet_BsConst_OilGauge_Element: start-on-event=MemAbstractMdl_Get_BsConst_OilGauge_Element, operation=pp_CS_MemAbsGet.Get_BsConst_OilGauge_Element
        OIE_pp_CS_MemAbsGet_MemAbstractMdl_Get_BsConst_PCB_Temperature_Sensor_ConvTrigByGet_BsConst_PCB_Temperature_Sensor_Conv: start-on-event=MemAbstractMdl_Get_BsConst_PCB_Temperature_Sensor_Conv, operation=pp_CS_MemAbsGet.Get_BsConst_PCB_Temperature_Sensor_Conv
        OperationInvokeEvent_16: start-on-event=MemAbstractMdl_Get_BsConst_PCB_Temperature_Sensor_Conv_SafeCopy1, operation=pp_CS_MemAbsGet.Get_BsConst_PCB_Temperature_Sensor_Conv_SafeCopy1
        OperationInvokeEvent_17: start-on-event=MemAbstractMdl_Get_BsConst_PCB_Temperature_Sensor_Conv_SafeCopy2, operation=pp_CS_MemAbsGet.Get_BsConst_PCB_Temperature_Sensor_Conv_SafeCopy2
        OIE_pp_CS_MemAbsGet_MemAbstractMdl_Get_BsConst_PWM_boost_bypass_dutyTrigByGet_BsConst_PWM_boost_bypass_duty: start-on-event=MemAbstractMdl_Get_BsConst_PWM_boost_bypass_duty, operation=pp_CS_MemAbsGet.Get_BsConst_PWM_boost_bypass_duty
        OperationInvokeEvent_18: start-on-event=MemAbstractMdl_Get_BsConst_PWM_boost_bypass_duty_SafeCopy1, operation=pp_CS_MemAbsGet.Get_BsConst_PWM_boost_bypass_duty_SafeCopy1
        OperationInvokeEvent_19: start-on-event=MemAbstractMdl_Get_BsConst_PWM_boost_bypass_duty_SafeCopy2, operation=pp_CS_MemAbsGet.Get_BsConst_PWM_boost_bypass_duty_SafeCopy2
        OIE_pp_CS_MemAbsGet_MemAbstractMdl_Get_BsConst_PowerGauge_ElementTrigByGet_BsConst_PowerGauge_Element: start-on-event=MemAbstractMdl_Get_BsConst_PowerGauge_Element, operation=pp_CS_MemAbsGet.Get_BsConst_PowerGauge_Element
        OIE_pp_CS_MemAbsGet_MemAbstractMdl_Get_BsConst_Power_ElementTrigByGet_BsConst_Power_Element: start-on-event=MemAbstractMdl_Get_BsConst_Power_Element, operation=pp_CS_MemAbsGet.Get_BsConst_Power_Element
        OIE_pp_CS_MemAbsGet_MemAbstractMdl_Get_BsConst_RealTimeClock_ElementTrigByGet_BsConst_RealTimeClock_Element: start-on-event=MemAbstractMdl_Get_BsConst_RealTimeClock_Element, operation=pp_CS_MemAbsGet.Get_BsConst_RealTimeClock_Element
        OIE_pp_CS_MemAbsGet_MemAbstractMdl_Get_BsConst_ServiceReminder_ElementTrigByGet_BsConst_ServiceReminder_Element: start-on-event=MemAbstractMdl_Get_BsConst_ServiceReminder_Element, operation=pp_CS_MemAbsGet.Get_BsConst_ServiceReminder_Element
        OIE_pp_CS_MemAbsGet_MemAbstractMdl_Get_BsConst_SpeedoGauge_ElementTrigByGet_BsConst_SpeedoGauge_Element: start-on-event=MemAbstractMdl_Get_BsConst_SpeedoGauge_Element, operation=pp_CS_MemAbsGet.Get_BsConst_SpeedoGauge_Element
        OIE_pp_CS_MemAbsGet_MemAbstractMdl_Get_BsConst_TachoGauge_ElementTrigByGet_BsConst_TachoGauge_Element: start-on-event=MemAbstractMdl_Get_BsConst_TachoGauge_Element, operation=pp_CS_MemAbsGet.Get_BsConst_TachoGauge_Element
        OIE_pp_CS_MemAbsGet_MemAbstractMdl_Get_BsConst_TempGauge_ElementTrigByGet_BsConst_TempGauge_Element: start-on-event=MemAbstractMdl_Get_BsConst_TempGauge_Element, operation=pp_CS_MemAbsGet.Get_BsConst_TempGauge_Element
        OperationInvokeEvent_20: start-on-event=MemAbstractMdl_Get_BsConst_Temp_Threshold_Hysteresis_Derating, operation=pp_CS_MemAbsGet.Get_BsConst_Temp_Threshold_Hysteresis_Derating
        OperationInvokeEvent_21: start-on-event=MemAbstractMdl_Get_BsConst_Temp_Threshold_Hysteresis_Derating_SafeCopy1, operation=pp_CS_MemAbsGet.Get_BsConst_Temp_Threshold_Hysteresis_Derating_SafeCopy1
        OperationInvokeEvent_22: start-on-event=MemAbstractMdl_Get_BsConst_Temp_Threshold_Hysteresis_Derating_SafeCopy2, operation=pp_CS_MemAbsGet.Get_BsConst_Temp_Threshold_Hysteresis_Derating_SafeCopy2
        OIE_pp_CS_MemAbsGet_MemAbstractMdl_Get_BsConst_Temperature_Sensor_ConvTrigByGet_BsConst_Temperature_Sensor_Conv: start-on-event=MemAbstractMdl_Get_BsConst_Temperature_Sensor_Conv, operation=pp_CS_MemAbsGet.Get_BsConst_Temperature_Sensor_Conv
        OperationInvokeEvent_23: start-on-event=MemAbstractMdl_Get_BsConst_Temperature_Sensor_Conv_SafeCopy1, operation=pp_CS_MemAbsGet.Get_BsConst_Temperature_Sensor_Conv_SafeCopy1
        OperationInvokeEvent_24: start-on-event=MemAbstractMdl_Get_BsConst_Temperature_Sensor_Conv_SafeCopy2, operation=pp_CS_MemAbsGet.Get_BsConst_Temperature_Sensor_Conv_SafeCopy2
        OIE_pp_CS_MemAbsGet_MemAbstractMdl_Get_BsConst_TripComputer_ElementTrigByGet_BsConst_TripComputer_Element: start-on-event=MemAbstractMdl_Get_BsConst_TripComputer_Element, operation=pp_CS_MemAbsGet.Get_BsConst_TripComputer_Element
        OIE_pp_CS_MemAbsGet_MemAbstractMdl_Get_BsConst_Warning_ElementTrigByGet_BsConst_Warning_Element: start-on-event=MemAbstractMdl_Get_BsConst_Warning_Element, operation=pp_CS_MemAbsGet.Get_BsConst_Warning_Element
        OIE_pp_CS_MemAbsGet_MemAbstractMdl_Get_BsCys_Certicificate_ElementTrigByGet_BsCys_Certicificate_Element: start-on-event=MemAbstractMdl_Get_BsCys_Certicificate_Element, operation=pp_CS_MemAbsGet.Get_BsCys_Certicificate_Element
        OIE_pp_CS_MemAbsGet_MemAbstractMdl_Get_BsDiag_Dtc_ElementTrigByGet_BsDiag_Dtc_Element: start-on-event=MemAbstractMdl_Get_BsDiag_Dtc_Element, operation=pp_CS_MemAbsGet.Get_BsDiag_Dtc_Element
        OIE_pp_CS_MemAbsGet_MemAbstractMdl_Get_BsDiag_ErrorRecord_ElementTrigByGet_BsDiag_ErrorRecord_Element: start-on-event=MemAbstractMdl_Get_BsDiag_ErrorRecord_Element, operation=pp_CS_MemAbsGet.Get_BsDiag_ErrorRecord_Element
        OIE_pp_CS_MemAbsGet_MemAbstractMdl_Get_BsReten_Audio_ElementTrigByGet_BsReten_Audio_Element: start-on-event=MemAbstractMdl_Get_BsReten_Audio_Element, operation=pp_CS_MemAbsGet.Get_BsReten_Audio_Element
        OIE_pp_CS_MemAbsGet_MemAbstractMdl_Get_BsReten_Communication_ElementTrigByGet_BsReten_Communication_Element: start-on-event=MemAbstractMdl_Get_BsReten_Communication_Element, operation=pp_CS_MemAbsGet.Get_BsReten_Communication_Element
        OIE_pp_CS_MemAbsGet_MemAbstractMdl_Get_BsReten_Display_ElementTrigByGet_BsReten_Display_Element: start-on-event=MemAbstractMdl_Get_BsReten_Display_Element, operation=pp_CS_MemAbsGet.Get_BsReten_Display_Element
        OIE_pp_CS_MemAbsGet_MemAbstractMdl_Get_BsReten_Gauges_ElementTrigByGet_BsReten_Gauges_Element: start-on-event=MemAbstractMdl_Get_BsReten_Gauges_Element, operation=pp_CS_MemAbsGet.Get_BsReten_Gauges_Element
        OIE_pp_CS_MemAbsGet_MemAbstractMdl_Get_BsReten_Illumination_ElementTrigByGet_BsReten_Illumination_Element: start-on-event=MemAbstractMdl_Get_BsReten_Illumination_Element, operation=pp_CS_MemAbsGet.Get_BsReten_Illumination_Element
        OIE_pp_CS_MemAbsGet_MemAbstractMdl_Get_BsReten_Odometer_ElementTrigByGet_BsReten_Odometer_Element: start-on-event=MemAbstractMdl_Get_BsReten_Odometer_Element, operation=pp_CS_MemAbsGet.Get_BsReten_Odometer_Element
        OIE_pp_CS_MemAbsGet_MemAbstractMdl_Get_BsReten_Personalization_ElementTrigByGet_BsReten_Personalization_Element: start-on-event=MemAbstractMdl_Get_BsReten_Personalization_Element, operation=pp_CS_MemAbsGet.Get_BsReten_Personalization_Element
        OIE_pp_CS_MemAbsGet_MemAbstractMdl_Get_BsReten_Power_ElementTrigByGet_BsReten_Power_Element: start-on-event=MemAbstractMdl_Get_BsReten_Power_Element, operation=pp_CS_MemAbsGet.Get_BsReten_Power_Element
        OIE_pp_CS_MemAbsGet_MemAbstractMdl_Get_BsReten_RealTimeClock_ElementTrigByGet_BsReten_RealTimeClock_Element: start-on-event=MemAbstractMdl_Get_BsReten_RealTimeClock_Element, operation=pp_CS_MemAbsGet.Get_BsReten_RealTimeClock_Element
        OIE_pp_CS_MemAbsGet_MemAbstractMdl_Get_BsReten_Tripcomputer_ElementTrigByGet_BsReten_Tripcomputer_Element: start-on-event=MemAbstractMdl_Get_BsReten_Tripcomputer_Element, operation=pp_CS_MemAbsGet.Get_BsReten_Tripcomputer_Element
        OIE_pp_CS_MemAbsGet_MemAbstractMdl_Get_BsReten_VisDlt_ElementTrigByGet_BsReten_VisDlt_Element: start-on-event=MemAbstractMdl_Get_BsReten_VisDlt_Element, operation=pp_CS_MemAbsGet.Get_BsReten_VisDlt_Element
        OIE_pp_CS_MemAbsGet_MemAbstractMdl_Get_BsReten_Warning_ElementTrigByGet_BsReten_Warning_Element: start-on-event=MemAbstractMdl_Get_BsReten_Warning_Element, operation=pp_CS_MemAbsGet.Get_BsReten_Warning_Element
        OIE_pp_CS_MemAbsGet_MemAbstractMdl_Get_BsRt_CusDlt_ElementTrigByGet_BsRt_CusDlt_Element: start-on-event=MemAbstractMdl_Get_BsRt_CusDlt_Element, operation=pp_CS_MemAbsGet.Get_BsRt_CusDlt_Element
        OIE_pp_CS_MemAbsGet_MemAbstractMdl_Get_BsRt_FuelGauge_ElementTrigByGet_BsRt_FuelGauge_Element: start-on-event=MemAbstractMdl_Get_BsRt_FuelGauge_Element, operation=pp_CS_MemAbsGet.Get_BsRt_FuelGauge_Element
        OIE_pp_CS_MemAbsGet_MemAbstractMdl_Get_BsRt_Illumination_ElementTrigByGet_BsRt_Illumination_Element: start-on-event=MemAbstractMdl_Get_BsRt_Illumination_Element, operation=pp_CS_MemAbsGet.Get_BsRt_Illumination_Element
        OIE_pp_CS_MemAbsGet_MemAbstractMdl_Get_BsRt_Odometer_ElementTrigByGet_BsRt_Odometer_Element: start-on-event=MemAbstractMdl_Get_BsRt_Odometer_Element, operation=pp_CS_MemAbsGet.Get_BsRt_Odometer_Element
        OIE_pp_CS_MemAbsGet_MemAbstractMdl_Get_BsRt_OilGauge_ElementTrigByGet_BsRt_OilGauge_Element: start-on-event=MemAbstractMdl_Get_BsRt_OilGauge_Element, operation=pp_CS_MemAbsGet.Get_BsRt_OilGauge_Element
        OIE_pp_CS_MemAbsGet_MemAbstractMdl_Get_BsRt_Personalization_ElementTrigByGet_BsRt_Personalization_Element: start-on-event=MemAbstractMdl_Get_BsRt_Personalization_Element, operation=pp_CS_MemAbsGet.Get_BsRt_Personalization_Element
        OIE_pp_CS_MemAbsGet_MemAbstractMdl_Get_BsRt_PowerGauge_ElementTrigByGet_BsRt_PowerGauge_Element: start-on-event=MemAbstractMdl_Get_BsRt_PowerGauge_Element, operation=pp_CS_MemAbsGet.Get_BsRt_PowerGauge_Element
        OIE_pp_CS_MemAbsGet_MemAbstractMdl_Get_BsRt_RealTimeClock_ElementTrigByGet_BsRt_RealTimeClock_Element: start-on-event=MemAbstractMdl_Get_BsRt_RealTimeClock_Element, operation=pp_CS_MemAbsGet.Get_BsRt_RealTimeClock_Element
        OIE_pp_CS_MemAbsGet_MemAbstractMdl_Get_BsRt_SpeedoGauge_ElementTrigByGet_BsRt_SpeedoGauge_Element: start-on-event=MemAbstractMdl_Get_BsRt_SpeedoGauge_Element, operation=pp_CS_MemAbsGet.Get_BsRt_SpeedoGauge_Element
        OIE_pp_CS_MemAbsGet_MemAbstractMdl_Get_BsRt_TachoGauge_ElementTrigByGet_BsRt_TachoGauge_Element: start-on-event=MemAbstractMdl_Get_BsRt_TachoGauge_Element, operation=pp_CS_MemAbsGet.Get_BsRt_TachoGauge_Element
        OIE_pp_CS_MemAbsGet_MemAbstractMdl_Get_BsRt_TempGauge_ElementTrigByGet_BsRt_TempGauge_Element: start-on-event=MemAbstractMdl_Get_BsRt_TempGauge_Element, operation=pp_CS_MemAbsGet.Get_BsRt_TempGauge_Element
        OIE_pp_CS_MemAbsGet_MemAbstractMdl_Get_BsRt_TripComputer_ElementTrigByGet_BsRt_TripComputer_Element: start-on-event=MemAbstractMdl_Get_BsRt_TripComputer_Element, operation=pp_CS_MemAbsGet.Get_BsRt_TripComputer_Element
        OIE_pp_CS_MemAbsGet_MemAbstractMdl_Get_BsRt_Warning_ElementTrigByGet_BsRt_Warning_Element: start-on-event=MemAbstractMdl_Get_BsRt_Warning_Element, operation=pp_CS_MemAbsGet.Get_BsRt_Warning_Element
        OIE_pp_CS_MemAbsGet_MemAbstractMdl_Get_BsShare_AssemblyManufacturingDateTrigByGet_BsShare_AssemblyManufacturingDate: start-on-event=MemAbstractMdl_Get_BsShare_AssemblyManufacturingDate, operation=pp_CS_MemAbsGet.Get_BsShare_AssemblyManufacturingDate
        OIE_pp_CS_MemAbsGet_MemAbstractMdl_Get_BsShare_AssemblyPlantNumberTrigByGet_BsShare_AssemblyPlantNumber: start-on-event=MemAbstractMdl_Get_BsShare_AssemblyPlantNumber, operation=pp_CS_MemAbsGet.Get_BsShare_AssemblyPlantNumber
        OIE_pp_CS_MemAbsGet_MemAbstractMdl_Get_BsShare_EcuPartNumber_ElementTrigByGet_BsShare_EcuPartNumber_Element: start-on-event=MemAbstractMdl_Get_BsShare_EcuPartNumber_Element, operation=pp_CS_MemAbsGet.Get_BsShare_EcuPartNumber_Element
        OIE_pp_CS_MemAbsGet_MemAbstractMdl_Get_BsShare_HWModificationTrigByGet_BsShare_HWModification: start-on-event=MemAbstractMdl_Get_BsShare_HWModification, operation=pp_CS_MemAbsGet.Get_BsShare_HWModification
        OIE_pp_CS_MemAbsGet_MemAbstractMdl_Get_BsShare_PCBSerialNumberTrigByGet_BsShare_PCBSerialNumber: start-on-event=MemAbstractMdl_Get_BsShare_PCBSerialNumber, operation=pp_CS_MemAbsGet.Get_BsShare_PCBSerialNumber
        OIE_pp_CS_MemAbsGet_MemAbstractMdl_Get_BsShare_ProductSerialNumberTrigByGet_BsShare_ProductSerialNumber: start-on-event=MemAbstractMdl_Get_BsShare_ProductSerialNumber, operation=pp_CS_MemAbsGet.Get_BsShare_ProductSerialNumber
        OIE_pp_CS_MemAbsGet_MemAbstractMdl_Get_BsShare_SMTManufacturingDateTrigByGet_BsShare_SMTManufacturingDate: start-on-event=MemAbstractMdl_Get_BsShare_SMTManufacturingDate, operation=pp_CS_MemAbsGet.Get_BsShare_SMTManufacturingDate
        OIE_pp_CS_MemAbsGet_MemAbstractMdl_Get_BsShare_SMTPlantNumberTrigByGet_BsShare_SMTPlantNumber: start-on-event=MemAbstractMdl_Get_BsShare_SMTPlantNumber, operation=pp_CS_MemAbsGet.Get_BsShare_SMTPlantNumber
        OIE_pp_CS_MemAbsGet_MemAbstractMdl_Get_BsShare_SwUpdFotaFinPrint_ElementTrigByGet_BsShare_SwUpdFotaFinPrint_Element: start-on-event=MemAbstractMdl_Get_BsShare_SwUpdFotaFinPrint_Element, operation=pp_CS_MemAbsGet.Get_BsShare_SwUpdFotaFinPrint_Element
        OIE_pp_CS_MemAbsGet_MemAbstractMdl_Get_BsShare_SwUpdFotaMode_ElementTrigByGet_BsShare_SwUpdFotaMode_Element: start-on-event=MemAbstractMdl_Get_BsShare_SwUpdFotaMode_Element, operation=pp_CS_MemAbsGet.Get_BsShare_SwUpdFotaMode_Element
        OIE_pp_CS_MemAbsGet_MemAbstractMdl_Get_BsShare_SwUpdFotaStatus_ElementTrigByGet_BsShare_SwUpdFotaStatus_Element: start-on-event=MemAbstractMdl_Get_BsShare_SwUpdFotaStatus_Element, operation=pp_CS_MemAbsGet.Get_BsShare_SwUpdFotaStatus_Element
        OIE_pp_CS_MemAbsGet_MemAbstractMdl_Get_BsShare_SwUpdFotadecrypt_ElementTrigByGet_BsShare_SwUpdFotadecrypt_Element: start-on-event=MemAbstractMdl_Get_BsShare_SwUpdFotadecrypt_Element, operation=pp_CS_MemAbsGet.Get_BsShare_SwUpdFotadecrypt_Element
        OIE_pp_CS_MemAbsGet_MemAbstractMdl_Get_BsShare_SwUpdReflash_ElementTrigByGet_BsShare_SwUpdReflash_Element: start-on-event=MemAbstractMdl_Get_BsShare_SwUpdReflash_Element, operation=pp_CS_MemAbsGet.Get_BsShare_SwUpdReflash_Element
        OIE_pp_CS_MemAbsGet_MemAbstractMdl_Get_BsShare_VehicleConfig_ElementTrigByGet_BsShare_VehicleConfig_Element: start-on-event=MemAbstractMdl_Get_BsShare_VehicleConfig_Element, operation=pp_CS_MemAbsGet.Get_BsShare_VehicleConfig_Element
        OIE_pp_CS_MemAbsGet_MemAbstractMdl_Get_BsShare_VisMeet_EOLEntry_ElementTrigByGet_BsShare_VisMeet_EOLEntry_Element: start-on-event=MemAbstractMdl_Get_BsShare_VisMeet_EOLEntry_Element, operation=pp_CS_MemAbsGet.Get_BsShare_VisMeet_EOLEntry_Element
        OIE_pp_CS_MemAbsGet_MemAbstractMdl_Get_BsShare_VisMeet_ElementTrigByGet_BsShare_VisMeet_Element: start-on-event=MemAbstractMdl_Get_BsShare_VisMeet_Element, operation=pp_CS_MemAbsGet.Get_BsShare_VisMeet_Element
        OIE_pp_CS_MemAbsGet_MemAbstractMdl_Get_BsShare_VisteonPCBPartNumberTrigByGet_BsShare_VisteonPCBPartNumber: start-on-event=MemAbstractMdl_Get_BsShare_VisteonPCBPartNumber, operation=pp_CS_MemAbsGet.Get_BsShare_VisteonPCBPartNumber
        OIE_pp_CS_MemAbsGet_MemAbstractMdl_Get_BsShare_VisteonPartNumberTrigByGet_BsShare_VisteonPartNumber: start-on-event=MemAbstractMdl_Get_BsShare_VisteonPartNumber, operation=pp_CS_MemAbsGet.Get_BsShare_VisteonPartNumber
        OIE_pp_CS_MemAbsGetDefault_MemAbstractMdl_Get_Default_BsConst_Audio_ElementTrigByGet_Default_BsConst_Audio_Element: start-on-event=MemAbstractMdl_Get_Default_BsConst_Audio_Element, operation=pp_CS_MemAbsGetDefault.Get_Default_BsConst_Audio_Element
        OperationInvokeEvent_25: start-on-event=MemAbstractMdl_Get_Default_BsConst_BsConst_Illumination_ReservedByte, operation=pp_CS_MemAbsGetDefault.Get_Default_BsConst_BsConst_Illumination_ReservedByte
        OperationInvokeEvent_26: start-on-event=MemAbstractMdl_Get_Default_BsConst_BsConst_Illumination_ReservedByte_SafeCopy1, operation=pp_CS_MemAbsGetDefault.Get_Default_BsConst_BsConst_Illumination_ReservedByte_SafeCopy1
        OperationInvokeEvent_27: start-on-event=MemAbstractMdl_Get_Default_BsConst_BsConst_Illumination_ReservedByte_SafeCopy2, operation=pp_CS_MemAbsGetDefault.Get_Default_BsConst_BsConst_Illumination_ReservedByte_SafeCopy2
        OperationInvokeEvent_28: start-on-event=MemAbstractMdl_Get_Default_BsConst_Communication_Element, operation=pp_CS_MemAbsGetDefault.Get_Default_BsConst_Communication_Element
        OperationInvokeEvent_29: start-on-event=MemAbstractMdl_Get_Default_BsConst_Compensation_Line_Shift_b, operation=pp_CS_MemAbsGetDefault.Get_Default_BsConst_Compensation_Line_Shift_b
        OperationInvokeEvent_30: start-on-event=MemAbstractMdl_Get_Default_BsConst_Compensation_Line_Shift_b_SafeCopy1, operation=pp_CS_MemAbsGetDefault.Get_Default_BsConst_Compensation_Line_Shift_b_SafeCopy1
        OperationInvokeEvent_31: start-on-event=MemAbstractMdl_Get_Default_BsConst_Compensation_Line_Shift_b_SafeCopy2, operation=pp_CS_MemAbsGetDefault.Get_Default_BsConst_Compensation_Line_Shift_b_SafeCopy2
        OperationInvokeEvent_32: start-on-event=MemAbstractMdl_Get_Default_BsConst_Compensation_Line_Slope_m, operation=pp_CS_MemAbsGetDefault.Get_Default_BsConst_Compensation_Line_Slope_m
        OperationInvokeEvent_33: start-on-event=MemAbstractMdl_Get_Default_BsConst_Compensation_Line_Slope_m_SafeCopy1, operation=pp_CS_MemAbsGetDefault.Get_Default_BsConst_Compensation_Line_Slope_m_SafeCopy1
        OperationInvokeEvent_34: start-on-event=MemAbstractMdl_Get_Default_BsConst_Compensation_Line_Slope_m_SafeCopy2, operation=pp_CS_MemAbsGetDefault.Get_Default_BsConst_Compensation_Line_Slope_m_SafeCopy2
        OperationInvokeEvent_35: start-on-event=MemAbstractMdl_Get_Default_BsConst_Derating_Backlight_Disable, operation=pp_CS_MemAbsGetDefault.Get_Default_BsConst_Derating_Backlight_Disable
        OperationInvokeEvent_36: start-on-event=MemAbstractMdl_Get_Default_BsConst_Derating_Backlight_Disable_SafeCopy1, operation=pp_CS_MemAbsGetDefault.Get_Default_BsConst_Derating_Backlight_Disable_SafeCopy1
        OperationInvokeEvent_37: start-on-event=MemAbstractMdl_Get_Default_BsConst_Derating_Backlight_Disable_SafeCopy2, operation=pp_CS_MemAbsGetDefault.Get_Default_BsConst_Derating_Backlight_Disable_SafeCopy2
        OperationInvokeEvent_38: start-on-event=MemAbstractMdl_Get_Default_BsConst_Display_Illum_Max_Level, operation=pp_CS_MemAbsGetDefault.Get_Default_BsConst_Display_Illum_Max_Level
        OperationInvokeEvent_39: start-on-event=MemAbstractMdl_Get_Default_BsConst_Display_Illum_Max_Level_SafeCopy1, operation=pp_CS_MemAbsGetDefault.Get_Default_BsConst_Display_Illum_Max_Level_SafeCopy1
        OperationInvokeEvent_40: start-on-event=MemAbstractMdl_Get_Default_BsConst_Display_Illum_Max_Level_SafeCopy2, operation=pp_CS_MemAbsGetDefault.Get_Default_BsConst_Display_Illum_Max_Level_SafeCopy2
        OIE_pp_CS_MemAbsGetDefault_MemAbstractMdl_Get_Default_BsConst_EngOffTimer_ElementTrigByGet_Default_BsConst_EngOffTimer_Element: start-on-event=MemAbstractMdl_Get_Default_BsConst_EngOffTimer_Element, operation=pp_CS_MemAbsGetDefault.Get_Default_BsConst_EngOffTimer_Element
        OIE_pp_CS_MemAbsGetDefault_MemAbstractMdl_Get_Default_BsConst_FuelGauge_ElementTrigByGet_Default_BsConst_FuelGauge_Element: start-on-event=MemAbstractMdl_Get_Default_BsConst_FuelGauge_Element, operation=pp_CS_MemAbsGetDefault.Get_Default_BsConst_FuelGauge_Element
        OperationInvokeEvent_41: start-on-event=MemAbstractMdl_Get_Default_BsConst_Lookup_Curve_HotSpot_Coef_X, operation=pp_CS_MemAbsGetDefault.Get_Default_BsConst_Lookup_Curve_HotSpot_Coef_X
        OperationInvokeEvent_42: start-on-event=MemAbstractMdl_Get_Default_BsConst_Lookup_Curve_HotSpot_Coef_X_SafeCopy1, operation=pp_CS_MemAbsGetDefault.Get_Default_BsConst_Lookup_Curve_HotSpot_Coef_X_SafeCopy1
        OperationInvokeEvent_43: start-on-event=MemAbstractMdl_Get_Default_BsConst_Lookup_Curve_HotSpot_Coef_X_SafeCopy2, operation=pp_CS_MemAbsGetDefault.Get_Default_BsConst_Lookup_Curve_HotSpot_Coef_X_SafeCopy2
        OperationInvokeEvent_44: start-on-event=MemAbstractMdl_Get_Default_BsConst_Lookup_Curve_HotSpot_Coef_Y, operation=pp_CS_MemAbsGetDefault.Get_Default_BsConst_Lookup_Curve_HotSpot_Coef_Y
        OperationInvokeEvent_45: start-on-event=MemAbstractMdl_Get_Default_BsConst_Lookup_Curve_HotSpot_Coef_Y_SafeCopy1, operation=pp_CS_MemAbsGetDefault.Get_Default_BsConst_Lookup_Curve_HotSpot_Coef_Y_SafeCopy1
        OperationInvokeEvent_46: start-on-event=MemAbstractMdl_Get_Default_BsConst_Lookup_Curve_HotSpot_Coef_Y_SafeCopy2, operation=pp_CS_MemAbsGetDefault.Get_Default_BsConst_Lookup_Curve_HotSpot_Coef_Y_SafeCopy2
        OIE_pp_CS_MemAbsGetDefault_MemAbstractMdl_Get_Default_BsConst_OilGauge_ElementTrigByGet_Default_BsConst_OilGauge_Element: start-on-event=MemAbstractMdl_Get_Default_BsConst_OilGauge_Element, operation=pp_CS_MemAbsGetDefault.Get_Default_BsConst_OilGauge_Element
        OperationInvokeEvent_47: start-on-event=MemAbstractMdl_Get_Default_BsConst_PCB_Temperature_Sensor_Conv, operation=pp_CS_MemAbsGetDefault.Get_Default_BsConst_PCB_Temperature_Sensor_Conv
        OperationInvokeEvent_48: start-on-event=MemAbstractMdl_Get_Default_BsConst_PCB_Temperature_Sensor_Conv_SafeCopy1, operation=pp_CS_MemAbsGetDefault.Get_Default_BsConst_PCB_Temperature_Sensor_Conv_SafeCopy1
        OperationInvokeEvent_49: start-on-event=MemAbstractMdl_Get_Default_BsConst_PCB_Temperature_Sensor_Conv_SafeCopy2, operation=pp_CS_MemAbsGetDefault.Get_Default_BsConst_PCB_Temperature_Sensor_Conv_SafeCopy2
        OperationInvokeEvent_50: start-on-event=MemAbstractMdl_Get_Default_BsConst_PWM_boost_bypass_duty, operation=pp_CS_MemAbsGetDefault.Get_Default_BsConst_PWM_boost_bypass_duty
        OperationInvokeEvent_51: start-on-event=MemAbstractMdl_Get_Default_BsConst_PWM_boost_bypass_duty_SafeCopy1, operation=pp_CS_MemAbsGetDefault.Get_Default_BsConst_PWM_boost_bypass_duty_SafeCopy1
        OperationInvokeEvent_52: start-on-event=MemAbstractMdl_Get_Default_BsConst_PWM_boost_bypass_duty_SafeCopy2, operation=pp_CS_MemAbsGetDefault.Get_Default_BsConst_PWM_boost_bypass_duty_SafeCopy2
        OIE_pp_CS_MemAbsGetDefault_MemAbstractMdl_Get_Default_BsConst_PowerGauge_ElementTrigByGet_Default_BsConst_PowerGauge_Element: start-on-event=MemAbstractMdl_Get_Default_BsConst_PowerGauge_Element, operation=pp_CS_MemAbsGetDefault.Get_Default_BsConst_PowerGauge_Element
        OIE_pp_CS_MemAbsGetDefault_MemAbstractMdl_Get_Default_BsConst_Power_ElementTrigByGet_Default_BsConst_Power_Element: start-on-event=MemAbstractMdl_Get_Default_BsConst_Power_Element, operation=pp_CS_MemAbsGetDefault.Get_Default_BsConst_Power_Element
        OperationInvokeEvent_53: start-on-event=MemAbstractMdl_Get_Default_BsConst_RealTimeClock_Element, operation=pp_CS_MemAbsGetDefault.Get_Default_BsConst_RealTimeClock_Element
        OperationInvokeEvent_54: start-on-event=MemAbstractMdl_Get_Default_BsConst_ServiceReminder_Element, operation=pp_CS_MemAbsGetDefault.Get_Default_BsConst_ServiceReminder_Element
        OIE_pp_CS_MemAbsGetDefault_MemAbstractMdl_Get_Default_BsConst_SpeedoGauge_ElementTrigByGet_Default_BsConst_SpeedoGauge_Element: start-on-event=MemAbstractMdl_Get_Default_BsConst_SpeedoGauge_Element, operation=pp_CS_MemAbsGetDefault.Get_Default_BsConst_SpeedoGauge_Element
        OIE_pp_CS_MemAbsGetDefault_MemAbstractMdl_Get_Default_BsConst_TachoGauge_ElementTrigByGet_Default_BsConst_TachoGauge_Element: start-on-event=MemAbstractMdl_Get_Default_BsConst_TachoGauge_Element, operation=pp_CS_MemAbsGetDefault.Get_Default_BsConst_TachoGauge_Element
        OIE_pp_CS_MemAbsGetDefault_MemAbstractMdl_Get_Default_BsConst_TempGauge_ElementTrigByGet_Default_BsConst_TempGauge_Element: start-on-event=MemAbstractMdl_Get_Default_BsConst_TempGauge_Element, operation=pp_CS_MemAbsGetDefault.Get_Default_BsConst_TempGauge_Element
        OperationInvokeEvent_55: start-on-event=MemAbstractMdl_Get_Default_BsConst_Temp_Threshold_Hysteresis_Derating, operation=pp_CS_MemAbsGetDefault.Get_Default_BsConst_Temp_Threshold_Hysteresis_Derating
        OperationInvokeEvent_56: start-on-event=MemAbstractMdl_Get_Default_BsConst_Temp_Threshold_Hysteresis_Derating_SafeCopy1, operation=pp_CS_MemAbsGetDefault.Get_Default_BsConst_Temp_Threshold_Hysteresis_Derating_SafeCopy1
        OperationInvokeEvent_57: start-on-event=MemAbstractMdl_Get_Default_BsConst_Temp_Threshold_Hysteresis_Derating_SafeCopy2, operation=pp_CS_MemAbsGetDefault.Get_Default_BsConst_Temp_Threshold_Hysteresis_Derating_SafeCopy2
        OperationInvokeEvent_58: start-on-event=MemAbstractMdl_Get_Default_BsConst_Temperature_Sensor_Conv, operation=pp_CS_MemAbsGetDefault.Get_Default_BsConst_Temperature_Sensor_Conv
        OperationInvokeEvent_59: start-on-event=MemAbstractMdl_Get_Default_BsConst_Temperature_Sensor_Conv_SafeCopy1, operation=pp_CS_MemAbsGetDefault.Get_Default_BsConst_Temperature_Sensor_Conv_SafeCopy1
        OperationInvokeEvent_60: start-on-event=MemAbstractMdl_Get_Default_BsConst_Temperature_Sensor_Conv_SafeCopy2, operation=pp_CS_MemAbsGetDefault.Get_Default_BsConst_Temperature_Sensor_Conv_SafeCopy2
        OperationInvokeEvent_61: start-on-event=MemAbstractMdl_Get_Default_BsConst_TripComputer_Element, operation=pp_CS_MemAbsGetDefault.Get_Default_BsConst_TripComputer_Element
        OIE_pp_CS_MemAbsGetDefault_MemAbstractMdl_Get_Default_BsConst_Warning_ElementTrigByGet_Default_BsConst_Warning_Element: start-on-event=MemAbstractMdl_Get_Default_BsConst_Warning_Element, operation=pp_CS_MemAbsGetDefault.Get_Default_BsConst_Warning_Element
        OIE_pp_CS_MemAbsGetDefault_MemAbstractMdl_Get_Default_BsCys_Certicificate_ElementTrigByGet_Default_BsCys_Certicificate_Element: start-on-event=MemAbstractMdl_Get_Default_BsCys_Certicificate_Element, operation=pp_CS_MemAbsGetDefault.Get_Default_BsCys_Certicificate_Element
        OIE_pp_CS_MemAbsGetDefault_MemAbstractMdl_Get_Default_BsDiag_Dtc_ElementTrigByGet_Default_BsDiag_Dtc_Element: start-on-event=MemAbstractMdl_Get_Default_BsDiag_Dtc_Element, operation=pp_CS_MemAbsGetDefault.Get_Default_BsDiag_Dtc_Element
        OIE_pp_CS_MemAbsGetDefault_MemAbstractMdl_Get_Default_BsDiag_ErrorRecord_ElementTrigByGet_Default_BsDiag_ErrorRecord_Element: start-on-event=MemAbstractMdl_Get_Default_BsDiag_ErrorRecord_Element, operation=pp_CS_MemAbsGetDefault.Get_Default_BsDiag_ErrorRecord_Element
        OIE_pp_CS_MemAbsGetDefault_MemAbstractMdl_Get_Default_BsReten_Audio_ElementTrigByGet_Default_BsReten_Audio_Element: start-on-event=MemAbstractMdl_Get_Default_BsReten_Audio_Element, operation=pp_CS_MemAbsGetDefault.Get_Default_BsReten_Audio_Element
        OperationInvokeEvent_62: start-on-event=MemAbstractMdl_Get_Default_BsReten_Communication_Element, operation=pp_CS_MemAbsGetDefault.Get_Default_BsReten_Communication_Element
        OIE_pp_CS_MemAbsGetDefault_MemAbstractMdl_Get_Default_BsReten_Display_ElementTrigByGet_Default_BsReten_Display_Element: start-on-event=MemAbstractMdl_Get_Default_BsReten_Display_Element, operation=pp_CS_MemAbsGetDefault.Get_Default_BsReten_Display_Element
        OIE_pp_CS_MemAbsGetDefault_MemAbstractMdl_Get_Default_BsReten_Gauges_ElementTrigByGet_Default_BsReten_Gauges_Element: start-on-event=MemAbstractMdl_Get_Default_BsReten_Gauges_Element, operation=pp_CS_MemAbsGetDefault.Get_Default_BsReten_Gauges_Element
        OperationInvokeEvent_63: start-on-event=MemAbstractMdl_Get_Default_BsReten_Illumination_Element, operation=pp_CS_MemAbsGetDefault.Get_Default_BsReten_Illumination_Element
        OIE_pp_CS_MemAbsGetDefault_MemAbstractMdl_Get_Default_BsReten_Odometer_ElementTrigByGet_Default_BsReten_Odometer_Element: start-on-event=MemAbstractMdl_Get_Default_BsReten_Odometer_Element, operation=pp_CS_MemAbsGetDefault.Get_Default_BsReten_Odometer_Element
        OperationInvokeEvent_64: start-on-event=MemAbstractMdl_Get_Default_BsReten_Personalization_Element, operation=pp_CS_MemAbsGetDefault.Get_Default_BsReten_Personalization_Element
        OIE_pp_CS_MemAbsGetDefault_MemAbstractMdl_Get_Default_BsReten_Power_ElementTrigByGet_Default_BsReten_Power_Element: start-on-event=MemAbstractMdl_Get_Default_BsReten_Power_Element, operation=pp_CS_MemAbsGetDefault.Get_Default_BsReten_Power_Element
        OperationInvokeEvent_65: start-on-event=MemAbstractMdl_Get_Default_BsReten_RealTimeClock_Element, operation=pp_CS_MemAbsGetDefault.Get_Default_BsReten_RealTimeClock_Element
        OperationInvokeEvent_66: start-on-event=MemAbstractMdl_Get_Default_BsReten_Tripcomputer_Element, operation=pp_CS_MemAbsGetDefault.Get_Default_BsReten_Tripcomputer_Element
        OIE_pp_CS_MemAbsGetDefault_MemAbstractMdl_Get_Default_BsReten_VisDlt_ElementTrigByGet_Default_BsReten_VisDlt_Element: start-on-event=MemAbstractMdl_Get_Default_BsReten_VisDlt_Element, operation=pp_CS_MemAbsGetDefault.Get_Default_BsReten_VisDlt_Element
        OIE_pp_CS_MemAbsGetDefault_MemAbstractMdl_Get_Default_BsReten_Warning_ElementTrigByGet_Default_BsReten_Warning_Element: start-on-event=MemAbstractMdl_Get_Default_BsReten_Warning_Element, operation=pp_CS_MemAbsGetDefault.Get_Default_BsReten_Warning_Element
        OIE_pp_CS_MemAbsGetDefault_MemAbstractMdl_Get_Default_BsRt_CusDlt_ElementTrigByGet_Default_BsRt_CusDlt_Element: start-on-event=MemAbstractMdl_Get_Default_BsRt_CusDlt_Element, operation=pp_CS_MemAbsGetDefault.Get_Default_BsRt_CusDlt_Element
        OIE_pp_CS_MemAbsGetDefault_MemAbstractMdl_Get_Default_BsRt_FuelGauge_ElementTrigByGet_Default_BsRt_FuelGauge_Element: start-on-event=MemAbstractMdl_Get_Default_BsRt_FuelGauge_Element, operation=pp_CS_MemAbsGetDefault.Get_Default_BsRt_FuelGauge_Element
        OIE_pp_CS_MemAbsGetDefault_MemAbstractMdl_Get_Default_BsRt_Illumination_ElementTrigByGet_Default_BsRt_Illumination_Element: start-on-event=MemAbstractMdl_Get_Default_BsRt_Illumination_Element, operation=pp_CS_MemAbsGetDefault.Get_Default_BsRt_Illumination_Element
        OIE_pp_CS_MemAbsGetDefault_MemAbstractMdl_Get_Default_BsRt_Odometer_ElementTrigByGet_Default_BsRt_Odometer_Element: start-on-event=MemAbstractMdl_Get_Default_BsRt_Odometer_Element, operation=pp_CS_MemAbsGetDefault.Get_Default_BsRt_Odometer_Element
        OIE_pp_CS_MemAbsGetDefault_MemAbstractMdl_Get_Default_BsRt_OilGauge_ElementTrigByGet_Default_BsRt_OilGauge_Element: start-on-event=MemAbstractMdl_Get_Default_BsRt_OilGauge_Element, operation=pp_CS_MemAbsGetDefault.Get_Default_BsRt_OilGauge_Element
        OperationInvokeEvent_67: start-on-event=MemAbstractMdl_Get_Default_BsRt_Personalization_Element, operation=pp_CS_MemAbsGetDefault.Get_Default_BsRt_Personalization_Element
        OIE_pp_CS_MemAbsGetDefault_MemAbstractMdl_Get_Default_BsRt_PowerGauge_ElementTrigByGet_Default_BsRt_PowerGauge_Element: start-on-event=MemAbstractMdl_Get_Default_BsRt_PowerGauge_Element, operation=pp_CS_MemAbsGetDefault.Get_Default_BsRt_PowerGauge_Element
        OIE_pp_CS_MemAbsGetDefault_MemAbstractMdl_Get_Default_BsRt_RealTimeClock_ElementTrigByGet_Default_BsRt_RealTimeClock_Element: start-on-event=MemAbstractMdl_Get_Default_BsRt_RealTimeClock_Element, operation=pp_CS_MemAbsGetDefault.Get_Default_BsRt_RealTimeClock_Element
        OIE_pp_CS_MemAbsGetDefault_MemAbstractMdl_Get_Default_BsRt_SpeedoGauge_ElementTrigByGet_Default_BsRt_SpeedoGauge_Element: start-on-event=MemAbstractMdl_Get_Default_BsRt_SpeedoGauge_Element, operation=pp_CS_MemAbsGetDefault.Get_Default_BsRt_SpeedoGauge_Element
        OIE_pp_CS_MemAbsGetDefault_MemAbstractMdl_Get_Default_BsRt_TachoGauge_ElementTrigByGet_Default_BsRt_TachoGauge_Element: start-on-event=MemAbstractMdl_Get_Default_BsRt_TachoGauge_Element, operation=pp_CS_MemAbsGetDefault.Get_Default_BsRt_TachoGauge_Element
        OIE_pp_CS_MemAbsGetDefault_MemAbstractMdl_Get_Default_BsRt_TempGauge_ElementTrigByGet_Default_BsRt_TempGauge_Element: start-on-event=MemAbstractMdl_Get_Default_BsRt_TempGauge_Element, operation=pp_CS_MemAbsGetDefault.Get_Default_BsRt_TempGauge_Element
        OIE_pp_CS_MemAbsGetDefault_MemAbstractMdl_Get_Default_BsRt_TripComputer_ElementTrigByGet_Default_BsRt_TripComputer_Element: start-on-event=MemAbstractMdl_Get_Default_BsRt_TripComputer_Element, operation=pp_CS_MemAbsGetDefault.Get_Default_BsRt_TripComputer_Element
        OIE_pp_CS_MemAbsGetDefault_MemAbstractMdl_Get_Default_BsRt_Warning_ElementTrigByGet_Default_BsRt_Warning_Element: start-on-event=MemAbstractMdl_Get_Default_BsRt_Warning_Element, operation=pp_CS_MemAbsGetDefault.Get_Default_BsRt_Warning_Element
        OperationInvokeEvent_68: start-on-event=MemAbstractMdl_Get_Default_BsShare_AssemblyManufacturingDate, operation=pp_CS_MemAbsGetDefault.Get_Default_BsShare_AssemblyManufacturingDate
        OIE_pp_CS_MemAbsGetDefault_MemAbstractMdl_Get_Default_BsShare_AssemblyPlantNumberTrigByGet_Default_BsShare_AssemblyPlantNumber: start-on-event=MemAbstractMdl_Get_Default_BsShare_AssemblyPlantNumber, operation=pp_CS_MemAbsGetDefault.Get_Default_BsShare_AssemblyPlantNumber
        OperationInvokeEvent_69: start-on-event=MemAbstractMdl_Get_Default_BsShare_EcuPartNumber_Element, operation=pp_CS_MemAbsGetDefault.Get_Default_BsShare_EcuPartNumber_Element
        OIE_pp_CS_MemAbsGetDefault_MemAbstractMdl_Get_Default_BsShare_HWModificationTrigByGet_Default_BsShare_HWModification: start-on-event=MemAbstractMdl_Get_Default_BsShare_HWModification, operation=pp_CS_MemAbsGetDefault.Get_Default_BsShare_HWModification
        OIE_pp_CS_MemAbsGetDefault_MemAbstractMdl_Get_Default_BsShare_PCBSerialNumberTrigByGet_Default_BsShare_PCBSerialNumber: start-on-event=MemAbstractMdl_Get_Default_BsShare_PCBSerialNumber, operation=pp_CS_MemAbsGetDefault.Get_Default_BsShare_PCBSerialNumber
        OIE_pp_CS_MemAbsGetDefault_MemAbstractMdl_Get_Default_BsShare_ProductSerialNumberTrigByGet_Default_BsShare_ProductSerialNumber: start-on-event=MemAbstractMdl_Get_Default_BsShare_ProductSerialNumber, operation=pp_CS_MemAbsGetDefault.Get_Default_BsShare_ProductSerialNumber
        OperationInvokeEvent_70: start-on-event=MemAbstractMdl_Get_Default_BsShare_SMTManufacturingDate, operation=pp_CS_MemAbsGetDefault.Get_Default_BsShare_SMTManufacturingDate
        OIE_pp_CS_MemAbsGetDefault_MemAbstractMdl_Get_Default_BsShare_SMTPlantNumberTrigByGet_Default_BsShare_SMTPlantNumber: start-on-event=MemAbstractMdl_Get_Default_BsShare_SMTPlantNumber, operation=pp_CS_MemAbsGetDefault.Get_Default_BsShare_SMTPlantNumber
        OperationInvokeEvent_71: start-on-event=MemAbstractMdl_Get_Default_BsShare_SwUpdFotaFinPrint_Element, operation=pp_CS_MemAbsGetDefault.Get_Default_BsShare_SwUpdFotaFinPrint_Element
        OperationInvokeEvent_72: start-on-event=MemAbstractMdl_Get_Default_BsShare_SwUpdFotaMode_Element, operation=pp_CS_MemAbsGetDefault.Get_Default_BsShare_SwUpdFotaMode_Element
        OperationInvokeEvent_73: start-on-event=MemAbstractMdl_Get_Default_BsShare_SwUpdFotaStatus_Element, operation=pp_CS_MemAbsGetDefault.Get_Default_BsShare_SwUpdFotaStatus_Element
        OperationInvokeEvent_74: start-on-event=MemAbstractMdl_Get_Default_BsShare_SwUpdFotadecrypt_Element, operation=pp_CS_MemAbsGetDefault.Get_Default_BsShare_SwUpdFotadecrypt_Element
        OperationInvokeEvent_75: start-on-event=MemAbstractMdl_Get_Default_BsShare_SwUpdReflash_Element, operation=pp_CS_MemAbsGetDefault.Get_Default_BsShare_SwUpdReflash_Element
        OperationInvokeEvent_76: start-on-event=MemAbstractMdl_Get_Default_BsShare_VehicleConfig_Element, operation=pp_CS_MemAbsGetDefault.Get_Default_BsShare_VehicleConfig_Element
        OperationInvokeEvent_77: start-on-event=MemAbstractMdl_Get_Default_BsShare_VisMeet_EOLEntry_Element, operation=pp_CS_MemAbsGetDefault.Get_Default_BsShare_VisMeet_EOLEntry_Element
        OIE_pp_CS_MemAbsGetDefault_MemAbstractMdl_Get_Default_BsShare_VisMeet_ElementTrigByGet_Default_BsShare_VisMeet_Element: start-on-event=MemAbstractMdl_Get_Default_BsShare_VisMeet_Element, operation=pp_CS_MemAbsGetDefault.Get_Default_BsShare_VisMeet_Element
        OperationInvokeEvent_78: start-on-event=MemAbstractMdl_Get_Default_BsShare_VisteonPCBPartNumber, operation=pp_CS_MemAbsGetDefault.Get_Default_BsShare_VisteonPCBPartNumber
        OIE_pp_CS_MemAbsGetDefault_MemAbstractMdl_Get_Default_BsShare_VisteonPartNumberTrigByGet_Default_BsShare_VisteonPartNumber: start-on-event=MemAbstractMdl_Get_Default_BsShare_VisteonPartNumber, operation=pp_CS_MemAbsGetDefault.Get_Default_BsShare_VisteonPartNumber
        OperationInvokeEvent_79: start-on-event=MemAbstractMdl_Get_Default_RefCys_Certicificate1_Element, operation=pp_CS_MemAbsGetDefault.Get_Default_RefCys_Certicificate1_Element
        OperationInvokeEvent_80: start-on-event=MemAbstractMdl_Get_Default_RefCys_Certicificate_Element, operation=pp_CS_MemAbsGetDefault.Get_Default_RefCys_Certicificate_Element
        OIE_pp_CS_MemAbsGet_MemAbstractMdl_Get_RefCys_Certicificate1_ElementTrigByGet_RefCys_Certicificate1_Element: start-on-event=MemAbstractMdl_Get_RefCys_Certicificate1_Element, operation=pp_CS_MemAbsGet.Get_RefCys_Certicificate1_Element
        OIE_pp_CS_MemAbsGet_MemAbstractMdl_Get_RefCys_Certicificate_ElementTrigByGet_RefCys_Certicificate_Element: start-on-event=MemAbstractMdl_Get_RefCys_Certicificate_Element, operation=pp_CS_MemAbsGet.Get_RefCys_Certicificate_Element
        OIE_pp_CS_MemAbs_NvMWriteStatus_MemAbstractMdl_NvmWriteStatusTrigByNvmWriteStatus: start-on-event=MemAbstractMdl_NvmWriteStatus, operation=pp_CS_MemAbs_NvMWriteStatus.NvmWriteStatus
        OIE_pp_CS_MemAbsSet_MemAbstractMdl_Set_BsConst_Audio_ElementTrigBySet_BsConst_Audio_Element: start-on-event=MemAbstractMdl_Set_BsConst_Audio_Element, operation=pp_CS_MemAbsSet.Set_BsConst_Audio_Element
        OperationInvokeEvent_81: start-on-event=MemAbstractMdl_Set_BsConst_BsConst_Illumination_ReservedByte, operation=pp_CS_MemAbsSet.Set_BsConst_BsConst_Illumination_ReservedByte
        OperationInvokeEvent_82: start-on-event=MemAbstractMdl_Set_BsConst_BsConst_Illumination_ReservedByte_SafeCopy1, operation=pp_CS_MemAbsSet.Set_BsConst_BsConst_Illumination_ReservedByte_SafeCopy1
        OperationInvokeEvent_83: start-on-event=MemAbstractMdl_Set_BsConst_BsConst_Illumination_ReservedByte_SafeCopy2, operation=pp_CS_MemAbsSet.Set_BsConst_BsConst_Illumination_ReservedByte_SafeCopy2
        OIE_pp_CS_MemAbsSet_MemAbstractMdl_Set_BsConst_Communication_ElementTrigBySet_BsConst_Communication_Element: start-on-event=MemAbstractMdl_Set_BsConst_Communication_Element, operation=pp_CS_MemAbsSet.Set_BsConst_Communication_Element
        OIE_pp_CS_MemAbsSet_MemAbstractMdl_Set_BsConst_Compensation_Line_Shift_bTrigBySet_BsConst_Compensation_Line_Shift_b: start-on-event=MemAbstractMdl_Set_BsConst_Compensation_Line_Shift_b, operation=pp_CS_MemAbsSet.Set_BsConst_Compensation_Line_Shift_b
        OperationInvokeEvent_84: start-on-event=MemAbstractMdl_Set_BsConst_Compensation_Line_Shift_b_SafeCopy1, operation=pp_CS_MemAbsSet.Set_BsConst_Compensation_Line_Shift_b_SafeCopy1
        OperationInvokeEvent_85: start-on-event=MemAbstractMdl_Set_BsConst_Compensation_Line_Shift_b_SafeCopy2, operation=pp_CS_MemAbsSet.Set_BsConst_Compensation_Line_Shift_b_SafeCopy2
        OIE_pp_CS_MemAbsSet_MemAbstractMdl_Set_BsConst_Compensation_Line_Slope_mTrigBySet_BsConst_Compensation_Line_Slope_m: start-on-event=MemAbstractMdl_Set_BsConst_Compensation_Line_Slope_m, operation=pp_CS_MemAbsSet.Set_BsConst_Compensation_Line_Slope_m
        OperationInvokeEvent_86: start-on-event=MemAbstractMdl_Set_BsConst_Compensation_Line_Slope_m_SafeCopy1, operation=pp_CS_MemAbsSet.Set_BsConst_Compensation_Line_Slope_m_SafeCopy1
        OperationInvokeEvent_87: start-on-event=MemAbstractMdl_Set_BsConst_Compensation_Line_Slope_m_SafeCopy2, operation=pp_CS_MemAbsSet.Set_BsConst_Compensation_Line_Slope_m_SafeCopy2
        OIE_pp_CS_MemAbsSet_MemAbstractMdl_Set_BsConst_Derating_Backlight_DisableTrigBySet_BsConst_Derating_Backlight_Disable: start-on-event=MemAbstractMdl_Set_BsConst_Derating_Backlight_Disable, operation=pp_CS_MemAbsSet.Set_BsConst_Derating_Backlight_Disable
        OperationInvokeEvent_88: start-on-event=MemAbstractMdl_Set_BsConst_Derating_Backlight_Disable_SafeCopy1, operation=pp_CS_MemAbsSet.Set_BsConst_Derating_Backlight_Disable_SafeCopy1
        OperationInvokeEvent_89: start-on-event=MemAbstractMdl_Set_BsConst_Derating_Backlight_Disable_SafeCopy2, operation=pp_CS_MemAbsSet.Set_BsConst_Derating_Backlight_Disable_SafeCopy2
        OIE_pp_CS_MemAbsSet_MemAbstractMdl_Set_BsConst_Display_Illum_Max_LevelTrigBySet_BsConst_Display_Illum_Max_Level: start-on-event=MemAbstractMdl_Set_BsConst_Display_Illum_Max_Level, operation=pp_CS_MemAbsSet.Set_BsConst_Display_Illum_Max_Level
        OperationInvokeEvent_90: start-on-event=MemAbstractMdl_Set_BsConst_Display_Illum_Max_Level_SafeCopy1, operation=pp_CS_MemAbsSet.Set_BsConst_Display_Illum_Max_Level_SafeCopy1
        OperationInvokeEvent_91: start-on-event=MemAbstractMdl_Set_BsConst_Display_Illum_Max_Level_SafeCopy2, operation=pp_CS_MemAbsSet.Set_BsConst_Display_Illum_Max_Level_SafeCopy2
        OIE_pp_CS_MemAbsSet_MemAbstractMdl_Set_BsConst_EngOffTimer_ElementTrigBySet_BsConst_EngOffTimer_Element: start-on-event=MemAbstractMdl_Set_BsConst_EngOffTimer_Element, operation=pp_CS_MemAbsSet.Set_BsConst_EngOffTimer_Element
        OIE_pp_CS_MemAbsSet_MemAbstractMdl_Set_BsConst_FuelGauge_ElementTrigBySet_BsConst_FuelGauge_Element: start-on-event=MemAbstractMdl_Set_BsConst_FuelGauge_Element, operation=pp_CS_MemAbsSet.Set_BsConst_FuelGauge_Element
        OIE_pp_CS_MemAbsSet_MemAbstractMdl_Set_BsConst_Lookup_Curve_HotSpot_Coef_XTrigBySet_BsConst_Lookup_Curve_HotSpot_Coef_X: start-on-event=MemAbstractMdl_Set_BsConst_Lookup_Curve_HotSpot_Coef_X, operation=pp_CS_MemAbsSet.Set_BsConst_Lookup_Curve_HotSpot_Coef_X
        OperationInvokeEvent_92: start-on-event=MemAbstractMdl_Set_BsConst_Lookup_Curve_HotSpot_Coef_X_SafeCopy1, operation=pp_CS_MemAbsSet.Set_BsConst_Lookup_Curve_HotSpot_Coef_X_SafeCopy1
        OperationInvokeEvent_93: start-on-event=MemAbstractMdl_Set_BsConst_Lookup_Curve_HotSpot_Coef_X_SafeCopy2, operation=pp_CS_MemAbsSet.Set_BsConst_Lookup_Curve_HotSpot_Coef_X_SafeCopy2
        OIE_pp_CS_MemAbsSet_MemAbstractMdl_Set_BsConst_Lookup_Curve_HotSpot_Coef_YTrigBySet_BsConst_Lookup_Curve_HotSpot_Coef_Y: start-on-event=MemAbstractMdl_Set_BsConst_Lookup_Curve_HotSpot_Coef_Y, operation=pp_CS_MemAbsSet.Set_BsConst_Lookup_Curve_HotSpot_Coef_Y
        OperationInvokeEvent_94: start-on-event=MemAbstractMdl_Set_BsConst_Lookup_Curve_HotSpot_Coef_Y_SafeCopy1, operation=pp_CS_MemAbsSet.Set_BsConst_Lookup_Curve_HotSpot_Coef_Y_SafeCopy1
        OperationInvokeEvent_95: start-on-event=MemAbstractMdl_Set_BsConst_Lookup_Curve_HotSpot_Coef_Y_SafeCopy2, operation=pp_CS_MemAbsSet.Set_BsConst_Lookup_Curve_HotSpot_Coef_Y_SafeCopy2
        OIE_pp_CS_MemAbsSet_MemAbstractMdl_Set_BsConst_OilGauge_ElementTrigBySet_BsConst_OilGauge_Element: start-on-event=MemAbstractMdl_Set_BsConst_OilGauge_Element, operation=pp_CS_MemAbsSet.Set_BsConst_OilGauge_Element
        OIE_pp_CS_MemAbsSet_MemAbstractMdl_Set_BsConst_PCB_Temperature_Sensor_ConvTrigBySet_BsConst_PCB_Temperature_Sensor_Conv: start-on-event=MemAbstractMdl_Set_BsConst_PCB_Temperature_Sensor_Conv, operation=pp_CS_MemAbsSet.Set_BsConst_PCB_Temperature_Sensor_Conv
        OperationInvokeEvent_96: start-on-event=MemAbstractMdl_Set_BsConst_PCB_Temperature_Sensor_Conv_SafeCopy1, operation=pp_CS_MemAbsSet.Set_BsConst_PCB_Temperature_Sensor_Conv_SafeCopy1
        OperationInvokeEvent_97: start-on-event=MemAbstractMdl_Set_BsConst_PCB_Temperature_Sensor_Conv_SafeCopy2, operation=pp_CS_MemAbsSet.Set_BsConst_PCB_Temperature_Sensor_Conv_SafeCopy2
        OIE_pp_CS_MemAbsSet_MemAbstractMdl_Set_BsConst_PWM_boost_bypass_dutyTrigBySet_BsConst_PWM_boost_bypass_duty: start-on-event=MemAbstractMdl_Set_BsConst_PWM_boost_bypass_duty, operation=pp_CS_MemAbsSet.Set_BsConst_PWM_boost_bypass_duty
        OperationInvokeEvent_98: start-on-event=MemAbstractMdl_Set_BsConst_PWM_boost_bypass_duty_SafeCopy1, operation=pp_CS_MemAbsSet.Set_BsConst_PWM_boost_bypass_duty_SafeCopy1
        OperationInvokeEvent_99: start-on-event=MemAbstractMdl_Set_BsConst_PWM_boost_bypass_duty_SafeCopy2, operation=pp_CS_MemAbsSet.Set_BsConst_PWM_boost_bypass_duty_SafeCopy2
        OIE_pp_CS_MemAbsSet_MemAbstractMdl_Set_BsConst_PowerGauge_ElementTrigBySet_BsConst_PowerGauge_Element: start-on-event=MemAbstractMdl_Set_BsConst_PowerGauge_Element, operation=pp_CS_MemAbsSet.Set_BsConst_PowerGauge_Element
        OIE_pp_CS_MemAbsSet_MemAbstractMdl_Set_BsConst_Power_ElementTrigBySet_BsConst_Power_Element: start-on-event=MemAbstractMdl_Set_BsConst_Power_Element, operation=pp_CS_MemAbsSet.Set_BsConst_Power_Element
        OIE_pp_CS_MemAbsSet_MemAbstractMdl_Set_BsConst_RealTimeClock_ElementTrigBySet_BsConst_RealTimeClock_Element: start-on-event=MemAbstractMdl_Set_BsConst_RealTimeClock_Element, operation=pp_CS_MemAbsSet.Set_BsConst_RealTimeClock_Element
        OIE_pp_CS_MemAbsSet_MemAbstractMdl_Set_BsConst_ServiceReminder_ElementTrigBySet_BsConst_ServiceReminder_Element: start-on-event=MemAbstractMdl_Set_BsConst_ServiceReminder_Element, operation=pp_CS_MemAbsSet.Set_BsConst_ServiceReminder_Element
        OIE_pp_CS_MemAbsSet_MemAbstractMdl_Set_BsConst_SpeedoGauge_ElementTrigBySet_BsConst_SpeedoGauge_Element: start-on-event=MemAbstractMdl_Set_BsConst_SpeedoGauge_Element, operation=pp_CS_MemAbsSet.Set_BsConst_SpeedoGauge_Element
        OIE_pp_CS_MemAbsSet_MemAbstractMdl_Set_BsConst_TachoGauge_ElementTrigBySet_BsConst_TachoGauge_Element: start-on-event=MemAbstractMdl_Set_BsConst_TachoGauge_Element, operation=pp_CS_MemAbsSet.Set_BsConst_TachoGauge_Element
        OIE_pp_CS_MemAbsSet_MemAbstractMdl_Set_BsConst_TempGauge_ElementTrigBySet_BsConst_TempGauge_Element: start-on-event=MemAbstractMdl_Set_BsConst_TempGauge_Element, operation=pp_CS_MemAbsSet.Set_BsConst_TempGauge_Element
        OperationInvokeEvent_100: start-on-event=MemAbstractMdl_Set_BsConst_Temp_Threshold_Hysteresis_Derating, operation=pp_CS_MemAbsSet.Set_BsConst_Temp_Threshold_Hysteresis_Derating
        OperationInvokeEvent_101: start-on-event=MemAbstractMdl_Set_BsConst_Temp_Threshold_Hysteresis_Derating_SafeCopy1, operation=pp_CS_MemAbsSet.Set_BsConst_Temp_Threshold_Hysteresis_Derating_SafeCopy1
        OperationInvokeEvent_102: start-on-event=MemAbstractMdl_Set_BsConst_Temp_Threshold_Hysteresis_Derating_SafeCopy2, operation=pp_CS_MemAbsSet.Set_BsConst_Temp_Threshold_Hysteresis_Derating_SafeCopy2
        OIE_pp_CS_MemAbsSet_MemAbstractMdl_Set_BsConst_Temperature_Sensor_ConvTrigBySet_BsConst_Temperature_Sensor_Conv: start-on-event=MemAbstractMdl_Set_BsConst_Temperature_Sensor_Conv, operation=pp_CS_MemAbsSet.Set_BsConst_Temperature_Sensor_Conv
        OperationInvokeEvent_103: start-on-event=MemAbstractMdl_Set_BsConst_Temperature_Sensor_Conv_SafeCopy1, operation=pp_CS_MemAbsSet.Set_BsConst_Temperature_Sensor_Conv_SafeCopy1
        OperationInvokeEvent_104: start-on-event=MemAbstractMdl_Set_BsConst_Temperature_Sensor_Conv_SafeCopy2, operation=pp_CS_MemAbsSet.Set_BsConst_Temperature_Sensor_Conv_SafeCopy2
        OIE_pp_CS_MemAbsSet_MemAbstractMdl_Set_BsConst_TripComputer_ElementTrigBySet_BsConst_TripComputer_Element: start-on-event=MemAbstractMdl_Set_BsConst_TripComputer_Element, operation=pp_CS_MemAbsSet.Set_BsConst_TripComputer_Element
        OIE_pp_CS_MemAbsSet_MemAbstractMdl_Set_BsConst_Warning_ElementTrigBySet_BsConst_Warning_Element: start-on-event=MemAbstractMdl_Set_BsConst_Warning_Element, operation=pp_CS_MemAbsSet.Set_BsConst_Warning_Element
        OIE_pp_CS_MemAbsSet_MemAbstractMdl_Set_BsCys_Certicificate_ElementTrigBySet_BsCys_Certicificate_Element: start-on-event=MemAbstractMdl_Set_BsCys_Certicificate_Element, operation=pp_CS_MemAbsSet.Set_BsCys_Certicificate_Element
        OIE_pp_CS_MemAbsSet_MemAbstractMdl_Set_BsDiag_Dtc_ElementTrigBySet_BsDiag_Dtc_Element: start-on-event=MemAbstractMdl_Set_BsDiag_Dtc_Element, operation=pp_CS_MemAbsSet.Set_BsDiag_Dtc_Element
        OIE_pp_CS_MemAbsSet_MemAbstractMdl_Set_BsDiag_ErrorRecord_ElementTrigBySet_BsDiag_ErrorRecord_Element: start-on-event=MemAbstractMdl_Set_BsDiag_ErrorRecord_Element, operation=pp_CS_MemAbsSet.Set_BsDiag_ErrorRecord_Element
        OIE_pp_CS_MemAbsSet_MemAbstractMdl_Set_BsReten_Audio_ElementTrigBySet_BsReten_Audio_Element: start-on-event=MemAbstractMdl_Set_BsReten_Audio_Element, operation=pp_CS_MemAbsSet.Set_BsReten_Audio_Element
        OIE_pp_CS_MemAbsSet_MemAbstractMdl_Set_BsReten_Communication_ElementTrigBySet_BsReten_Communication_Element: start-on-event=MemAbstractMdl_Set_BsReten_Communication_Element, operation=pp_CS_MemAbsSet.Set_BsReten_Communication_Element
        OIE_pp_CS_MemAbsSet_MemAbstractMdl_Set_BsReten_Display_ElementTrigBySet_BsReten_Display_Element: start-on-event=MemAbstractMdl_Set_BsReten_Display_Element, operation=pp_CS_MemAbsSet.Set_BsReten_Display_Element
        OIE_pp_CS_MemAbsSet_MemAbstractMdl_Set_BsReten_Gauges_ElementTrigBySet_BsReten_Gauges_Element: start-on-event=MemAbstractMdl_Set_BsReten_Gauges_Element, operation=pp_CS_MemAbsSet.Set_BsReten_Gauges_Element
        OIE_pp_CS_MemAbsSet_MemAbstractMdl_Set_BsReten_Illumination_ElementTrigBySet_BsReten_Illumination_Element: start-on-event=MemAbstractMdl_Set_BsReten_Illumination_Element, operation=pp_CS_MemAbsSet.Set_BsReten_Illumination_Element
        OIE_pp_CS_MemAbsSet_MemAbstractMdl_Set_BsReten_Odometer_ElementTrigBySet_BsReten_Odometer_Element: start-on-event=MemAbstractMdl_Set_BsReten_Odometer_Element, operation=pp_CS_MemAbsSet.Set_BsReten_Odometer_Element
        OIE_pp_CS_MemAbsSet_MemAbstractMdl_Set_BsReten_Personalization_ElementTrigBySet_BsReten_Personalization_Element: start-on-event=MemAbstractMdl_Set_BsReten_Personalization_Element, operation=pp_CS_MemAbsSet.Set_BsReten_Personalization_Element
        OIE_pp_CS_MemAbsSet_MemAbstractMdl_Set_BsReten_Power_ElementTrigBySet_BsReten_Power_Element: start-on-event=MemAbstractMdl_Set_BsReten_Power_Element, operation=pp_CS_MemAbsSet.Set_BsReten_Power_Element
        OIE_pp_CS_MemAbsSet_MemAbstractMdl_Set_BsReten_RealTimeClock_ElementTrigBySet_BsReten_RealTimeClock_Element: start-on-event=MemAbstractMdl_Set_BsReten_RealTimeClock_Element, operation=pp_CS_MemAbsSet.Set_BsReten_RealTimeClock_Element
        OIE_pp_CS_MemAbsSet_MemAbstractMdl_Set_BsReten_Tripcomputer_ElementTrigBySet_BsReten_Tripcomputer_Element: start-on-event=MemAbstractMdl_Set_BsReten_Tripcomputer_Element, operation=pp_CS_MemAbsSet.Set_BsReten_Tripcomputer_Element
        OIE_pp_CS_MemAbsSet_MemAbstractMdl_Set_BsReten_VisDlt_ElementTrigBySet_BsReten_VisDlt_Element: start-on-event=MemAbstractMdl_Set_BsReten_VisDlt_Element, operation=pp_CS_MemAbsSet.Set_BsReten_VisDlt_Element
        OIE_pp_CS_MemAbsSet_MemAbstractMdl_Set_BsReten_Warning_ElementTrigBySet_BsReten_Warning_Element: start-on-event=MemAbstractMdl_Set_BsReten_Warning_Element, operation=pp_CS_MemAbsSet.Set_BsReten_Warning_Element
        OIE_pp_CS_MemAbsSet_MemAbstractMdl_Set_BsRt_CusDlt_ElementTrigBySet_BsRt_CusDlt_Element: start-on-event=MemAbstractMdl_Set_BsRt_CusDlt_Element, operation=pp_CS_MemAbsSet.Set_BsRt_CusDlt_Element
        OIE_pp_CS_MemAbsSet_MemAbstractMdl_Set_BsRt_FuelGauge_ElementTrigBySet_BsRt_FuelGauge_Element: start-on-event=MemAbstractMdl_Set_BsRt_FuelGauge_Element, operation=pp_CS_MemAbsSet.Set_BsRt_FuelGauge_Element
        OIE_pp_CS_MemAbsSet_MemAbstractMdl_Set_BsRt_Illumination_ElementTrigBySet_BsRt_Illumination_Element: start-on-event=MemAbstractMdl_Set_BsRt_Illumination_Element, operation=pp_CS_MemAbsSet.Set_BsRt_Illumination_Element
        OIE_pp_CS_MemAbsSet_MemAbstractMdl_Set_BsRt_Odometer_ElementTrigBySet_BsRt_Odometer_Element: start-on-event=MemAbstractMdl_Set_BsRt_Odometer_Element, operation=pp_CS_MemAbsSet.Set_BsRt_Odometer_Element
        OIE_pp_CS_MemAbsSet_MemAbstractMdl_Set_BsRt_OilGauge_ElementTrigBySet_BsRt_OilGauge_Element: start-on-event=MemAbstractMdl_Set_BsRt_OilGauge_Element, operation=pp_CS_MemAbsSet.Set_BsRt_OilGauge_Element
        OIE_pp_CS_MemAbsSet_MemAbstractMdl_Set_BsRt_Personalization_ElementTrigBySet_BsRt_Personalization_Element: start-on-event=MemAbstractMdl_Set_BsRt_Personalization_Element, operation=pp_CS_MemAbsSet.Set_BsRt_Personalization_Element
        OIE_pp_CS_MemAbsSet_MemAbstractMdl_Set_BsRt_PowerGauge_ElementTrigBySet_BsRt_PowerGauge_Element: start-on-event=MemAbstractMdl_Set_BsRt_PowerGauge_Element, operation=pp_CS_MemAbsSet.Set_BsRt_PowerGauge_Element
        OIE_pp_CS_MemAbsSet_MemAbstractMdl_Set_BsRt_RealTimeClock_ElementTrigBySet_BsRt_RealTimeClock_Element: start-on-event=MemAbstractMdl_Set_BsRt_RealTimeClock_Element, operation=pp_CS_MemAbsSet.Set_BsRt_RealTimeClock_Element
        OIE_pp_CS_MemAbsSet_MemAbstractMdl_Set_BsRt_SpeedoGauge_ElementTrigBySet_BsRt_SpeedoGauge_Element: start-on-event=MemAbstractMdl_Set_BsRt_SpeedoGauge_Element, operation=pp_CS_MemAbsSet.Set_BsRt_SpeedoGauge_Element
        OIE_pp_CS_MemAbsSet_MemAbstractMdl_Set_BsRt_TachoGauge_ElementTrigBySet_BsRt_TachoGauge_Element: start-on-event=MemAbstractMdl_Set_BsRt_TachoGauge_Element, operation=pp_CS_MemAbsSet.Set_BsRt_TachoGauge_Element
        OIE_pp_CS_MemAbsSet_MemAbstractMdl_Set_BsRt_TempGauge_ElementTrigBySet_BsRt_TempGauge_Element: start-on-event=MemAbstractMdl_Set_BsRt_TempGauge_Element, operation=pp_CS_MemAbsSet.Set_BsRt_TempGauge_Element
        OIE_pp_CS_MemAbsSet_MemAbstractMdl_Set_BsRt_TripComputer_ElementTrigBySet_BsRt_TripComputer_Element: start-on-event=MemAbstractMdl_Set_BsRt_TripComputer_Element, operation=pp_CS_MemAbsSet.Set_BsRt_TripComputer_Element
        OIE_pp_CS_MemAbsSet_MemAbstractMdl_Set_BsRt_Warning_ElementTrigBySet_BsRt_Warning_Element: start-on-event=MemAbstractMdl_Set_BsRt_Warning_Element, operation=pp_CS_MemAbsSet.Set_BsRt_Warning_Element
        OIE_pp_CS_MemAbsSet_MemAbstractMdl_Set_BsShare_AssemblyManufacturingDateTrigBySet_BsShare_AssemblyManufacturingDate: start-on-event=MemAbstractMdl_Set_BsShare_AssemblyManufacturingDate, operation=pp_CS_MemAbsSet.Set_BsShare_AssemblyManufacturingDate
        OIE_pp_CS_MemAbsSet_MemAbstractMdl_Set_BsShare_AssemblyPlantNumberTrigBySet_BsShare_AssemblyPlantNumber: start-on-event=MemAbstractMdl_Set_BsShare_AssemblyPlantNumber, operation=pp_CS_MemAbsSet.Set_BsShare_AssemblyPlantNumber
        OIE_pp_CS_MemAbsSet_MemAbstractMdl_Set_BsShare_EcuPartNumber_ElementTrigBySet_BsShare_EcuPartNumber_Element: start-on-event=MemAbstractMdl_Set_BsShare_EcuPartNumber_Element, operation=pp_CS_MemAbsSet.Set_BsShare_EcuPartNumber_Element
        OIE_pp_CS_MemAbsSet_MemAbstractMdl_Set_BsShare_HWModificationTrigBySet_BsShare_HWModification: start-on-event=MemAbstractMdl_Set_BsShare_HWModification, operation=pp_CS_MemAbsSet.Set_BsShare_HWModification
        OIE_pp_CS_MemAbsSet_MemAbstractMdl_Set_BsShare_PCBSerialNumberTrigBySet_BsShare_PCBSerialNumber: start-on-event=MemAbstractMdl_Set_BsShare_PCBSerialNumber, operation=pp_CS_MemAbsSet.Set_BsShare_PCBSerialNumber
        OIE_pp_CS_MemAbsSet_MemAbstractMdl_Set_BsShare_ProductSerialNumberTrigBySet_BsShare_ProductSerialNumber: start-on-event=MemAbstractMdl_Set_BsShare_ProductSerialNumber, operation=pp_CS_MemAbsSet.Set_BsShare_ProductSerialNumber
        OIE_pp_CS_MemAbsSet_MemAbstractMdl_Set_BsShare_SMTManufacturingDateTrigBySet_BsShare_SMTManufacturingDate: start-on-event=MemAbstractMdl_Set_BsShare_SMTManufacturingDate, operation=pp_CS_MemAbsSet.Set_BsShare_SMTManufacturingDate
        OIE_pp_CS_MemAbsSet_MemAbstractMdl_Set_BsShare_SMTPlantNumberTrigBySet_BsShare_SMTPlantNumber: start-on-event=MemAbstractMdl_Set_BsShare_SMTPlantNumber, operation=pp_CS_MemAbsSet.Set_BsShare_SMTPlantNumber
        OIE_pp_CS_MemAbsSet_MemAbstractMdl_Set_BsShare_SwUpdFotaFinPrint_ElementTrigBySet_BsShare_SwUpdFotaFinPrint_Element: start-on-event=MemAbstractMdl_Set_BsShare_SwUpdFotaFinPrint_Element, operation=pp_CS_MemAbsSet.Set_BsShare_SwUpdFotaFinPrint_Element
        OIE_pp_CS_MemAbsSet_MemAbstractMdl_Set_BsShare_SwUpdFotaMode_ElementTrigBySet_BsShare_SwUpdFotaMode_Element: start-on-event=MemAbstractMdl_Set_BsShare_SwUpdFotaMode_Element, operation=pp_CS_MemAbsSet.Set_BsShare_SwUpdFotaMode_Element
        OIE_pp_CS_MemAbsSet_MemAbstractMdl_Set_BsShare_SwUpdFotaStatus_ElementTrigBySet_BsShare_SwUpdFotaStatus_Element: start-on-event=MemAbstractMdl_Set_BsShare_SwUpdFotaStatus_Element, operation=pp_CS_MemAbsSet.Set_BsShare_SwUpdFotaStatus_Element
        OIE_pp_CS_MemAbsSet_MemAbstractMdl_Set_BsShare_SwUpdFotadecrypt_ElementTrigBySet_BsShare_SwUpdFotadecrypt_Element: start-on-event=MemAbstractMdl_Set_BsShare_SwUpdFotadecrypt_Element, operation=pp_CS_MemAbsSet.Set_BsShare_SwUpdFotadecrypt_Element
        OIE_pp_CS_MemAbsSet_MemAbstractMdl_Set_BsShare_SwUpdReflash_ElementTrigBySet_BsShare_SwUpdReflash_Element: start-on-event=MemAbstractMdl_Set_BsShare_SwUpdReflash_Element, operation=pp_CS_MemAbsSet.Set_BsShare_SwUpdReflash_Element
        OIE_pp_CS_MemAbsSet_MemAbstractMdl_Set_BsShare_VehicleConfig_ElementTrigBySet_BsShare_VehicleConfig_Element: start-on-event=MemAbstractMdl_Set_BsShare_VehicleConfig_Element, operation=pp_CS_MemAbsSet.Set_BsShare_VehicleConfig_Element
        OIE_pp_CS_MemAbsSet_MemAbstractMdl_Set_BsShare_VisMeet_EOLEntry_ElementTrigBySet_BsShare_VisMeet_EOLEntry_Element: start-on-event=MemAbstractMdl_Set_BsShare_VisMeet_EOLEntry_Element, operation=pp_CS_MemAbsSet.Set_BsShare_VisMeet_EOLEntry_Element
        OIE_pp_CS_MemAbsSet_MemAbstractMdl_Set_BsShare_VisMeet_ElementTrigBySet_BsShare_VisMeet_Element: start-on-event=MemAbstractMdl_Set_BsShare_VisMeet_Element, operation=pp_CS_MemAbsSet.Set_BsShare_VisMeet_Element
        OIE_pp_CS_MemAbsSet_MemAbstractMdl_Set_BsShare_VisteonPCBPartNumberTrigBySet_BsShare_VisteonPCBPartNumber: start-on-event=MemAbstractMdl_Set_BsShare_VisteonPCBPartNumber, operation=pp_CS_MemAbsSet.Set_BsShare_VisteonPCBPartNumber
        OIE_pp_CS_MemAbsSet_MemAbstractMdl_Set_BsShare_VisteonPartNumberTrigBySet_BsShare_VisteonPartNumber: start-on-event=MemAbstractMdl_Set_BsShare_VisteonPartNumber, operation=pp_CS_MemAbsSet.Set_BsShare_VisteonPartNumber
        OIE_pp_CS_MemAbsSet_MemAbstractMdl_Set_RefCys_Certicificate1_ElementTrigBySet_RefCys_Certicificate1_Element: start-on-event=MemAbstractMdl_Set_RefCys_Certicificate1_Element, operation=pp_CS_MemAbsSet.Set_RefCys_Certicificate1_Element
        OIE_pp_CS_MemAbsSet_MemAbstractMdl_Set_RefCys_Certicificate_ElementTrigBySet_RefCys_Certicificate_Element: start-on-event=MemAbstractMdl_Set_RefCys_Certicificate_Element, operation=pp_CS_MemAbsSet.Set_RefCys_Certicificate_Element
      port-api-options:
        enable-take-address=false, indirect-api=false, port=pp_CS_MemAbsGet
        enable-take-address=false, indirect-api=false, port=pp_CS_MemAbsGetDefault
        enable-take-address=false, indirect-api=false, port=pp_CS_MemAbsSet
        enable-take-address=false, indirect-api=false, port=pp_CS_MemAbs_NvMWriteStatus
        enable-take-address=false, indirect-api=false, port=pp_CmpLibCmd_MemAbstractMdl
        enable-take-address=false, indirect-api=false, port=pp_SR_JobStatus
      288 x runnable, all with can-be-invoked-concurrently=true:
        CMemAbstractMdl_Impl_MainFunction
          data-send-points:
            95 x access:
              DWA_pp_SR_JobStatus_JobStatus_BsConst_Audio_Element: accessed-variable=pp_SR_JobStatus.JobStatus_BsConst_Audio_Element
              DWA_pp_SR_JobStatus_JobStatus_BsConst_BsConst_Illumination_ReservedByte: accessed-variable=pp_SR_JobStatus.JobStatus_BsConst_BsConst_Illumination_ReservedByte
              DWA_pp_SR_JobStatus_JobStatus_BsConst_BsConst_Illumination_ReservedByte_SafeCopy1: accessed-variable=pp_SR_JobStatus.JobStatus_BsConst_BsConst_Illumination_ReservedByte_SafeCopy1
              DWA_pp_SR_JobStatus_JobStatus_BsConst_BsConst_Illumination_ReservedByte_SafeCopy2: accessed-variable=pp_SR_JobStatus.JobStatus_BsConst_BsConst_Illumination_ReservedByte_SafeCopy2
              DWA_pp_SR_JobStatus_JobStatus_BsConst_Communication_Element: accessed-variable=pp_SR_JobStatus.JobStatus_BsConst_Communication_Element
              DWA_pp_SR_JobStatus_JobStatus_BsConst_Compensation_Line_Shift_b: accessed-variable=pp_SR_JobStatus.JobStatus_BsConst_Compensation_Line_Shift_b
              DWA_pp_SR_JobStatus_JobStatus_BsConst_Compensation_Line_Shift_b_SafeCopy1: accessed-variable=pp_SR_JobStatus.JobStatus_BsConst_Compensation_Line_Shift_b_SafeCopy1
              DWA_pp_SR_JobStatus_JobStatus_BsConst_Compensation_Line_Shift_b_SafeCopy2: accessed-variable=pp_SR_JobStatus.JobStatus_BsConst_Compensation_Line_Shift_b_SafeCopy2
              DWA_pp_SR_JobStatus_JobStatus_BsConst_Compensation_Line_Slope_m: accessed-variable=pp_SR_JobStatus.JobStatus_BsConst_Compensation_Line_Slope_m
              DWA_pp_SR_JobStatus_JobStatus_BsConst_Compensation_Line_Slope_m_SafeCopy1: accessed-variable=pp_SR_JobStatus.JobStatus_BsConst_Compensation_Line_Slope_m_SafeCopy1
              DWA_pp_SR_JobStatus_JobStatus_BsConst_Compensation_Line_Slope_m_SafeCopy2: accessed-variable=pp_SR_JobStatus.JobStatus_BsConst_Compensation_Line_Slope_m_SafeCopy2
              DWA_pp_SR_JobStatus_JobStatus_BsConst_Derating_Backlight_Disable: accessed-variable=pp_SR_JobStatus.JobStatus_BsConst_Derating_Backlight_Disable
              DWA_pp_SR_JobStatus_JobStatus_BsConst_Derating_Backlight_Disable_SafeCopy1: accessed-variable=pp_SR_JobStatus.JobStatus_BsConst_Derating_Backlight_Disable_SafeCopy1
              DWA_pp_SR_JobStatus_JobStatus_BsConst_Derating_Backlight_Disable_SafeCopy2: accessed-variable=pp_SR_JobStatus.JobStatus_BsConst_Derating_Backlight_Disable_SafeCopy2
              DWA_pp_SR_JobStatus_JobStatus_BsConst_Display_Illum_Max_Level: accessed-variable=pp_SR_JobStatus.JobStatus_BsConst_Display_Illum_Max_Level
              DWA_pp_SR_JobStatus_JobStatus_BsConst_Display_Illum_Max_Level_SafeCopy1: accessed-variable=pp_SR_JobStatus.JobStatus_BsConst_Display_Illum_Max_Level_SafeCopy1
              DWA_pp_SR_JobStatus_JobStatus_BsConst_Display_Illum_Max_Level_SafeCopy2: accessed-variable=pp_SR_JobStatus.JobStatus_BsConst_Display_Illum_Max_Level_SafeCopy2
              DWA_pp_SR_JobStatus_JobStatus_BsConst_EngOffTimer_Element: accessed-variable=pp_SR_JobStatus.JobStatus_BsConst_EngOffTimer_Element
              DWA_pp_SR_JobStatus_JobStatus_BsConst_FuelGauge_Element: accessed-variable=pp_SR_JobStatus.JobStatus_BsConst_FuelGauge_Element
              DWA_pp_SR_JobStatus_JobStatus_BsConst_Lookup_Curve_HotSpot_Coef_X: accessed-variable=pp_SR_JobStatus.JobStatus_BsConst_Lookup_Curve_HotSpot_Coef_X
              DWA_pp_SR_JobStatus_JobStatus_BsConst_Lookup_Curve_HotSpot_Coef_X_SafeCopy1: accessed-variable=pp_SR_JobStatus.JobStatus_BsConst_Lookup_Curve_HotSpot_Coef_X_SafeCopy1
              DWA_pp_SR_JobStatus_JobStatus_BsConst_Lookup_Curve_HotSpot_Coef_X_SafeCopy2: accessed-variable=pp_SR_JobStatus.JobStatus_BsConst_Lookup_Curve_HotSpot_Coef_X_SafeCopy2
              DWA_pp_SR_JobStatus_JobStatus_BsConst_Lookup_Curve_HotSpot_Coef_Y: accessed-variable=pp_SR_JobStatus.JobStatus_BsConst_Lookup_Curve_HotSpot_Coef_Y
              DWA_pp_SR_JobStatus_JobStatus_BsConst_Lookup_Curve_HotSpot_Coef_Y_SafeCopy1: accessed-variable=pp_SR_JobStatus.JobStatus_BsConst_Lookup_Curve_HotSpot_Coef_Y_SafeCopy1
              DWA_pp_SR_JobStatus_JobStatus_BsConst_Lookup_Curve_HotSpot_Coef_Y_SafeCopy2: accessed-variable=pp_SR_JobStatus.JobStatus_BsConst_Lookup_Curve_HotSpot_Coef_Y_SafeCopy2
              DWA_pp_SR_JobStatus_JobStatus_BsConst_OilGauge_Element: accessed-variable=pp_SR_JobStatus.JobStatus_BsConst_OilGauge_Element
              DWA_pp_SR_JobStatus_JobStatus_BsConst_PCB_Temperature_Sensor_Conv: accessed-variable=pp_SR_JobStatus.JobStatus_BsConst_PCB_Temperature_Sensor_Conv
              DWA_pp_SR_JobStatus_JobStatus_BsConst_PCB_Temperature_Sensor_Conv_SafeCopy1: accessed-variable=pp_SR_JobStatus.JobStatus_BsConst_PCB_Temperature_Sensor_Conv_SafeCopy1
              DWA_pp_SR_JobStatus_JobStatus_BsConst_PCB_Temperature_Sensor_Conv_SafeCopy2: accessed-variable=pp_SR_JobStatus.JobStatus_BsConst_PCB_Temperature_Sensor_Conv_SafeCopy2
              DWA_pp_SR_JobStatus_JobStatus_BsConst_PWM_boost_bypass_duty: accessed-variable=pp_SR_JobStatus.JobStatus_BsConst_PWM_boost_bypass_duty
              DWA_pp_SR_JobStatus_JobStatus_BsConst_PWM_boost_bypass_duty_SafeCopy1: accessed-variable=pp_SR_JobStatus.JobStatus_BsConst_PWM_boost_bypass_duty_SafeCopy1
              DWA_pp_SR_JobStatus_JobStatus_BsConst_PWM_boost_bypass_duty_SafeCopy2: accessed-variable=pp_SR_JobStatus.JobStatus_BsConst_PWM_boost_bypass_duty_SafeCopy2
              DWA_pp_SR_JobStatus_JobStatus_BsConst_PowerGauge_Element: accessed-variable=pp_SR_JobStatus.JobStatus_BsConst_PowerGauge_Element
              DWA_pp_SR_JobStatus_JobStatus_BsConst_Power_Element: accessed-variable=pp_SR_JobStatus.JobStatus_BsConst_Power_Element
              DWA_pp_SR_JobStatus_JobStatus_BsConst_RealTimeClock_Element: accessed-variable=pp_SR_JobStatus.JobStatus_BsConst_RealTimeClock_Element
              DWA_pp_SR_JobStatus_JobStatus_BsConst_ServiceReminder_Element: accessed-variable=pp_SR_JobStatus.JobStatus_BsConst_ServiceReminder_Element
              DWA_pp_SR_JobStatus_JobStatus_BsConst_SpeedoGauge_Element: accessed-variable=pp_SR_JobStatus.JobStatus_BsConst_SpeedoGauge_Element
              DWA_pp_SR_JobStatus_JobStatus_BsConst_TachoGauge_Element: accessed-variable=pp_SR_JobStatus.JobStatus_BsConst_TachoGauge_Element
              DWA_pp_SR_JobStatus_JobStatus_BsConst_TempGauge_Element: accessed-variable=pp_SR_JobStatus.JobStatus_BsConst_TempGauge_Element
              DWA_pp_SR_JobStatus_JobStatus_BsConst_Temp_Threshold_Hysteresis_Derating: accessed-variable=pp_SR_JobStatus.JobStatus_BsConst_Temp_Threshold_Hysteresis_Derating
              DWA_pp_SR_JobStatus_JobStatus_BsConst_Temp_Threshold_Hysteresis_Derating_SafeCopy1: accessed-variable=pp_SR_JobStatus.JobStatus_BsConst_Temp_Threshold_Hysteresis_Derating_SafeCopy1
              DWA_pp_SR_JobStatus_JobStatus_BsConst_Temp_Threshold_Hysteresis_Derating_SafeCopy2: accessed-variable=pp_SR_JobStatus.JobStatus_BsConst_Temp_Threshold_Hysteresis_Derating_SafeCopy2
              DWA_pp_SR_JobStatus_JobStatus_BsConst_Temperature_Sensor_Conv: accessed-variable=pp_SR_JobStatus.JobStatus_BsConst_Temperature_Sensor_Conv
              DWA_pp_SR_JobStatus_JobStatus_BsConst_Temperature_Sensor_Conv_SafeCopy1: accessed-variable=pp_SR_JobStatus.JobStatus_BsConst_Temperature_Sensor_Conv_SafeCopy1
              DWA_pp_SR_JobStatus_JobStatus_BsConst_Temperature_Sensor_Conv_SafeCopy2: accessed-variable=pp_SR_JobStatus.JobStatus_BsConst_Temperature_Sensor_Conv_SafeCopy2
              DWA_pp_SR_JobStatus_JobStatus_BsConst_TripComputer_Element: accessed-variable=pp_SR_JobStatus.JobStatus_BsConst_TripComputer_Element
              DWA_pp_SR_JobStatus_JobStatus_BsConst_Warning_Element: accessed-variable=pp_SR_JobStatus.JobStatus_BsConst_Warning_Element
              DWA_pp_SR_JobStatus_JobStatus_BsCys_Certicificate_Element: accessed-variable=pp_SR_JobStatus.JobStatus_BsCys_Certicificate_Element
              DWA_pp_SR_JobStatus_JobStatus_BsDiag_Dtc_Element: accessed-variable=pp_SR_JobStatus.JobStatus_BsDiag_Dtc_Element
              DWA_pp_SR_JobStatus_JobStatus_BsDiag_ErrorRecord_Element: accessed-variable=pp_SR_JobStatus.JobStatus_BsDiag_ErrorRecord_Element
              DWA_pp_SR_JobStatus_JobStatus_BsReten_Audio_Element: accessed-variable=pp_SR_JobStatus.JobStatus_BsReten_Audio_Element
              DWA_pp_SR_JobStatus_JobStatus_BsReten_Communication_Element: accessed-variable=pp_SR_JobStatus.JobStatus_BsReten_Communication_Element
              DWA_pp_SR_JobStatus_JobStatus_BsReten_Display_Element: accessed-variable=pp_SR_JobStatus.JobStatus_BsReten_Display_Element
              DWA_pp_SR_JobStatus_JobStatus_BsReten_Gauges_Element: accessed-variable=pp_SR_JobStatus.JobStatus_BsReten_Gauges_Element
              DWA_pp_SR_JobStatus_JobStatus_BsReten_Illumination_Element: accessed-variable=pp_SR_JobStatus.JobStatus_BsReten_Illumination_Element
              DWA_pp_SR_JobStatus_JobStatus_BsReten_Odometer_Element: accessed-variable=pp_SR_JobStatus.JobStatus_BsReten_Odometer_Element
              DWA_pp_SR_JobStatus_JobStatus_BsReten_Personalization_Element: accessed-variable=pp_SR_JobStatus.JobStatus_BsReten_Personalization_Element
              DWA_pp_SR_JobStatus_JobStatus_BsReten_Power_Element: accessed-variable=pp_SR_JobStatus.JobStatus_BsReten_Power_Element
              DWA_pp_SR_JobStatus_JobStatus_BsReten_RealTimeClock_Element: accessed-variable=pp_SR_JobStatus.JobStatus_BsReten_RealTimeClock_Element
              DWA_pp_SR_JobStatus_JobStatus_BsReten_Tripcomputer_Element: accessed-variable=pp_SR_JobStatus.JobStatus_BsReten_Tripcomputer_Element
              DWA_pp_SR_JobStatus_JobStatus_BsReten_VisDlt_Element: accessed-variable=pp_SR_JobStatus.JobStatus_BsReten_VisDlt_Element
              DWA_pp_SR_JobStatus_JobStatus_BsReten_Warning_Element: accessed-variable=pp_SR_JobStatus.JobStatus_BsReten_Warning_Element
              DWA_pp_SR_JobStatus_JobStatus_BsRt_CusDlt_Element: accessed-variable=pp_SR_JobStatus.JobStatus_BsRt_CusDlt_Element
              DWA_pp_SR_JobStatus_JobStatus_BsRt_FuelGauge_Element: accessed-variable=pp_SR_JobStatus.JobStatus_BsRt_FuelGauge_Element
              DWA_pp_SR_JobStatus_JobStatus_BsRt_Illumination_Element: accessed-variable=pp_SR_JobStatus.JobStatus_BsRt_Illumination_Element
              DWA_pp_SR_JobStatus_JobStatus_BsRt_Odometer_Element: accessed-variable=pp_SR_JobStatus.JobStatus_BsRt_Odometer_Element
              DWA_pp_SR_JobStatus_JobStatus_BsRt_OilGauge_Element: accessed-variable=pp_SR_JobStatus.JobStatus_BsRt_OilGauge_Element
              DWA_pp_SR_JobStatus_JobStatus_BsRt_Personalization_Element: accessed-variable=pp_SR_JobStatus.JobStatus_BsRt_Personalization_Element
              DWA_pp_SR_JobStatus_JobStatus_BsRt_PowerGauge_Element: accessed-variable=pp_SR_JobStatus.JobStatus_BsRt_PowerGauge_Element
              DWA_pp_SR_JobStatus_JobStatus_BsRt_RealTimeClock_Element: accessed-variable=pp_SR_JobStatus.JobStatus_BsRt_RealTimeClock_Element
              DWA_pp_SR_JobStatus_JobStatus_BsRt_SpeedoGauge_Element: accessed-variable=pp_SR_JobStatus.JobStatus_BsRt_SpeedoGauge_Element
              DWA_pp_SR_JobStatus_JobStatus_BsRt_TachoGauge_Element: accessed-variable=pp_SR_JobStatus.JobStatus_BsRt_TachoGauge_Element
              DWA_pp_SR_JobStatus_JobStatus_BsRt_TempGauge_Element: accessed-variable=pp_SR_JobStatus.JobStatus_BsRt_TempGauge_Element
              DWA_pp_SR_JobStatus_JobStatus_BsRt_TripComputer_Element: accessed-variable=pp_SR_JobStatus.JobStatus_BsRt_TripComputer_Element
              DWA_pp_SR_JobStatus_JobStatus_BsRt_Warning_Element: accessed-variable=pp_SR_JobStatus.JobStatus_BsRt_Warning_Element
              DWA_pp_SR_JobStatus_JobStatus_BsShare_AssemblyManufacturingDate: accessed-variable=pp_SR_JobStatus.JobStatus_BsShare_AssemblyManufacturingDate
              DWA_pp_SR_JobStatus_JobStatus_BsShare_AssemblyPlantNumber: accessed-variable=pp_SR_JobStatus.JobStatus_BsShare_AssemblyPlantNumber
              DWA_pp_SR_JobStatus_JobStatus_BsShare_EcuPartNumber_Element: accessed-variable=pp_SR_JobStatus.JobStatus_BsShare_EcuPartNumber_Element
              DWA_pp_SR_JobStatus_JobStatus_BsShare_HWModification: accessed-variable=pp_SR_JobStatus.JobStatus_BsShare_HWModification
              DWA_pp_SR_JobStatus_JobStatus_BsShare_PCBSerialNumber: accessed-variable=pp_SR_JobStatus.JobStatus_BsShare_PCBSerialNumber
              DWA_pp_SR_JobStatus_JobStatus_BsShare_ProductSerialNumber: accessed-variable=pp_SR_JobStatus.JobStatus_BsShare_ProductSerialNumber
              DWA_pp_SR_JobStatus_JobStatus_BsShare_SMTManufacturingDate: accessed-variable=pp_SR_JobStatus.JobStatus_BsShare_SMTManufacturingDate
              DWA_pp_SR_JobStatus_JobStatus_BsShare_SMTPlantNumber: accessed-variable=pp_SR_JobStatus.JobStatus_BsShare_SMTPlantNumber
              DWA_pp_SR_JobStatus_JobStatus_BsShare_SwUpdFotaFinPrint_Element: accessed-variable=pp_SR_JobStatus.JobStatus_BsShare_SwUpdFotaFinPrint_Element
              DWA_pp_SR_JobStatus_JobStatus_BsShare_SwUpdFotaMode_Element: accessed-variable=pp_SR_JobStatus.JobStatus_BsShare_SwUpdFotaMode_Element
              DWA_pp_SR_JobStatus_JobStatus_BsShare_SwUpdFotaStatus_Element: accessed-variable=pp_SR_JobStatus.JobStatus_BsShare_SwUpdFotaStatus_Element
              DWA_pp_SR_JobStatus_JobStatus_BsShare_SwUpdFotadecrypt_Element: accessed-variable=pp_SR_JobStatus.JobStatus_BsShare_SwUpdFotadecrypt_Element
              DWA_pp_SR_JobStatus_JobStatus_BsShare_SwUpdReflash_Element: accessed-variable=pp_SR_JobStatus.JobStatus_BsShare_SwUpdReflash_Element
              DWA_pp_SR_JobStatus_JobStatus_BsShare_VehicleConfig_Element: accessed-variable=pp_SR_JobStatus.JobStatus_BsShare_VehicleConfig_Element
              DWA_pp_SR_JobStatus_JobStatus_BsShare_VisMeet_EOLEntry_Element: accessed-variable=pp_SR_JobStatus.JobStatus_BsShare_VisMeet_EOLEntry_Element
              DWA_pp_SR_JobStatus_JobStatus_BsShare_VisMeet_Element: accessed-variable=pp_SR_JobStatus.JobStatus_BsShare_VisMeet_Element
              DWA_pp_SR_JobStatus_JobStatus_BsShare_VisteonPCBPartNumber: accessed-variable=pp_SR_JobStatus.JobStatus_BsShare_VisteonPCBPartNumber
              DWA_pp_SR_JobStatus_JobStatus_BsShare_VisteonPartNumber: accessed-variable=pp_SR_JobStatus.JobStatus_BsShare_VisteonPartNumber
              DWA_pp_SR_JobStatus_JobStatus_RefCys_Certicificate1_Element: accessed-variable=pp_SR_JobStatus.JobStatus_RefCys_Certicificate1_Element
              DWA_pp_SR_JobStatus_JobStatus_RefCys_Certicificate_Element: accessed-variable=pp_SR_JobStatus.JobStatus_RefCys_Certicificate_Element
        CMemAbstractMdl_Impl_OnCommand
        MemAbstractMdl_Get_BsConst_Audio_Element
        MemAbstractMdl_Get_BsConst_BsConst_Illumination_ReservedByte
        MemAbstractMdl_Get_BsConst_BsConst_Illumination_ReservedByte_SafeCopy1
        MemAbstractMdl_Get_BsConst_BsConst_Illumination_ReservedByte_SafeCopy2
        MemAbstractMdl_Get_BsConst_Communication_Element
        MemAbstractMdl_Get_BsConst_Compensation_Line_Shift_b
        MemAbstractMdl_Get_BsConst_Compensation_Line_Shift_b_SafeCopy1
        MemAbstractMdl_Get_BsConst_Compensation_Line_Shift_b_SafeCopy2
        MemAbstractMdl_Get_BsConst_Compensation_Line_Slope_m
        MemAbstractMdl_Get_BsConst_Compensation_Line_Slope_m_SafeCopy1
        MemAbstractMdl_Get_BsConst_Compensation_Line_Slope_m_SafeCopy2
        MemAbstractMdl_Get_BsConst_Derating_Backlight_Disable
        MemAbstractMdl_Get_BsConst_Derating_Backlight_Disable_SafeCopy1
        MemAbstractMdl_Get_BsConst_Derating_Backlight_Disable_SafeCopy2
        MemAbstractMdl_Get_BsConst_Display_Illum_Max_Level
        MemAbstractMdl_Get_BsConst_Display_Illum_Max_Level_SafeCopy1
        MemAbstractMdl_Get_BsConst_Display_Illum_Max_Level_SafeCopy2
        MemAbstractMdl_Get_BsConst_EngOffTimer_Element
        MemAbstractMdl_Get_BsConst_FuelGauge_Element
        MemAbstractMdl_Get_BsConst_Lookup_Curve_HotSpot_Coef_X
        MemAbstractMdl_Get_BsConst_Lookup_Curve_HotSpot_Coef_X_SafeCopy1
        MemAbstractMdl_Get_BsConst_Lookup_Curve_HotSpot_Coef_X_SafeCopy2
        MemAbstractMdl_Get_BsConst_Lookup_Curve_HotSpot_Coef_Y
        MemAbstractMdl_Get_BsConst_Lookup_Curve_HotSpot_Coef_Y_SafeCopy1
        MemAbstractMdl_Get_BsConst_Lookup_Curve_HotSpot_Coef_Y_SafeCopy2
        MemAbstractMdl_Get_BsConst_OilGauge_Element
        MemAbstractMdl_Get_BsConst_PCB_Temperature_Sensor_Conv
        MemAbstractMdl_Get_BsConst_PCB_Temperature_Sensor_Conv_SafeCopy1
        MemAbstractMdl_Get_BsConst_PCB_Temperature_Sensor_Conv_SafeCopy2
        MemAbstractMdl_Get_BsConst_PWM_boost_bypass_duty
        MemAbstractMdl_Get_BsConst_PWM_boost_bypass_duty_SafeCopy1
        MemAbstractMdl_Get_BsConst_PWM_boost_bypass_duty_SafeCopy2
        MemAbstractMdl_Get_BsConst_PowerGauge_Element
        MemAbstractMdl_Get_BsConst_Power_Element
        MemAbstractMdl_Get_BsConst_RealTimeClock_Element
        MemAbstractMdl_Get_BsConst_ServiceReminder_Element
        MemAbstractMdl_Get_BsConst_SpeedoGauge_Element
        MemAbstractMdl_Get_BsConst_TachoGauge_Element
        MemAbstractMdl_Get_BsConst_TempGauge_Element
        MemAbstractMdl_Get_BsConst_Temp_Threshold_Hysteresis_Derating
        MemAbstractMdl_Get_BsConst_Temp_Threshold_Hysteresis_Derating_SafeCopy1
        MemAbstractMdl_Get_BsConst_Temp_Threshold_Hysteresis_Derating_SafeCopy2
        MemAbstractMdl_Get_BsConst_Temperature_Sensor_Conv
        MemAbstractMdl_Get_BsConst_Temperature_Sensor_Conv_SafeCopy1
        MemAbstractMdl_Get_BsConst_Temperature_Sensor_Conv_SafeCopy2
        MemAbstractMdl_Get_BsConst_TripComputer_Element
        MemAbstractMdl_Get_BsConst_Warning_Element
        MemAbstractMdl_Get_BsCys_Certicificate_Element
        MemAbstractMdl_Get_BsDiag_Dtc_Element
        MemAbstractMdl_Get_BsDiag_ErrorRecord_Element
        MemAbstractMdl_Get_BsReten_Audio_Element
        MemAbstractMdl_Get_BsReten_Communication_Element
        MemAbstractMdl_Get_BsReten_Display_Element
        MemAbstractMdl_Get_BsReten_Gauges_Element
        MemAbstractMdl_Get_BsReten_Illumination_Element
        MemAbstractMdl_Get_BsReten_Odometer_Element
        MemAbstractMdl_Get_BsReten_Personalization_Element
        MemAbstractMdl_Get_BsReten_Power_Element
        MemAbstractMdl_Get_BsReten_RealTimeClock_Element
        MemAbstractMdl_Get_BsReten_Tripcomputer_Element
        MemAbstractMdl_Get_BsReten_VisDlt_Element
        MemAbstractMdl_Get_BsReten_Warning_Element
        MemAbstractMdl_Get_BsRt_CusDlt_Element
        MemAbstractMdl_Get_BsRt_FuelGauge_Element
        MemAbstractMdl_Get_BsRt_Illumination_Element
        MemAbstractMdl_Get_BsRt_Odometer_Element
        MemAbstractMdl_Get_BsRt_OilGauge_Element
        MemAbstractMdl_Get_BsRt_Personalization_Element
        MemAbstractMdl_Get_BsRt_PowerGauge_Element
        MemAbstractMdl_Get_BsRt_RealTimeClock_Element
        MemAbstractMdl_Get_BsRt_SpeedoGauge_Element
        MemAbstractMdl_Get_BsRt_TachoGauge_Element
        MemAbstractMdl_Get_BsRt_TempGauge_Element
        MemAbstractMdl_Get_BsRt_TripComputer_Element
        MemAbstractMdl_Get_BsRt_Warning_Element
        MemAbstractMdl_Get_BsShare_AssemblyManufacturingDate
        MemAbstractMdl_Get_BsShare_AssemblyPlantNumber
        MemAbstractMdl_Get_BsShare_EcuPartNumber_Element
        MemAbstractMdl_Get_BsShare_HWModification
        MemAbstractMdl_Get_BsShare_PCBSerialNumber
        MemAbstractMdl_Get_BsShare_ProductSerialNumber
        MemAbstractMdl_Get_BsShare_SMTManufacturingDate
        MemAbstractMdl_Get_BsShare_SMTPlantNumber
        MemAbstractMdl_Get_BsShare_SwUpdFotaFinPrint_Element
        MemAbstractMdl_Get_BsShare_SwUpdFotaMode_Element
        MemAbstractMdl_Get_BsShare_SwUpdFotaStatus_Element
        MemAbstractMdl_Get_BsShare_SwUpdFotadecrypt_Element
        MemAbstractMdl_Get_BsShare_SwUpdReflash_Element
        MemAbstractMdl_Get_BsShare_VehicleConfig_Element
        MemAbstractMdl_Get_BsShare_VisMeet_EOLEntry_Element
        MemAbstractMdl_Get_BsShare_VisMeet_Element
        MemAbstractMdl_Get_BsShare_VisteonPCBPartNumber
        MemAbstractMdl_Get_BsShare_VisteonPartNumber
        MemAbstractMdl_Get_Default_BsConst_Audio_Element
        MemAbstractMdl_Get_Default_BsConst_BsConst_Illumination_ReservedByte
        MemAbstractMdl_Get_Default_BsConst_BsConst_Illumination_ReservedByte_SafeCopy1
        MemAbstractMdl_Get_Default_BsConst_BsConst_Illumination_ReservedByte_SafeCopy2
        MemAbstractMdl_Get_Default_BsConst_Communication_Element
        MemAbstractMdl_Get_Default_BsConst_Compensation_Line_Shift_b
        MemAbstractMdl_Get_Default_BsConst_Compensation_Line_Shift_b_SafeCopy1
        MemAbstractMdl_Get_Default_BsConst_Compensation_Line_Shift_b_SafeCopy2
        MemAbstractMdl_Get_Default_BsConst_Compensation_Line_Slope_m
        MemAbstractMdl_Get_Default_BsConst_Compensation_Line_Slope_m_SafeCopy1
        MemAbstractMdl_Get_Default_BsConst_Compensation_Line_Slope_m_SafeCopy2
        MemAbstractMdl_Get_Default_BsConst_Derating_Backlight_Disable
        MemAbstractMdl_Get_Default_BsConst_Derating_Backlight_Disable_SafeCopy1
        MemAbstractMdl_Get_Default_BsConst_Derating_Backlight_Disable_SafeCopy2
        MemAbstractMdl_Get_Default_BsConst_Display_Illum_Max_Level
        MemAbstractMdl_Get_Default_BsConst_Display_Illum_Max_Level_SafeCopy1
        MemAbstractMdl_Get_Default_BsConst_Display_Illum_Max_Level_SafeCopy2
        MemAbstractMdl_Get_Default_BsConst_EngOffTimer_Element
        MemAbstractMdl_Get_Default_BsConst_FuelGauge_Element
        MemAbstractMdl_Get_Default_BsConst_Lookup_Curve_HotSpot_Coef_X
        MemAbstractMdl_Get_Default_BsConst_Lookup_Curve_HotSpot_Coef_X_SafeCopy1
        MemAbstractMdl_Get_Default_BsConst_Lookup_Curve_HotSpot_Coef_X_SafeCopy2
        MemAbstractMdl_Get_Default_BsConst_Lookup_Curve_HotSpot_Coef_Y
        MemAbstractMdl_Get_Default_BsConst_Lookup_Curve_HotSpot_Coef_Y_SafeCopy1
        MemAbstractMdl_Get_Default_BsConst_Lookup_Curve_HotSpot_Coef_Y_SafeCopy2
        MemAbstractMdl_Get_Default_BsConst_OilGauge_Element
        MemAbstractMdl_Get_Default_BsConst_PCB_Temperature_Sensor_Conv
        MemAbstractMdl_Get_Default_BsConst_PCB_Temperature_Sensor_Conv_SafeCopy1
        MemAbstractMdl_Get_Default_BsConst_PCB_Temperature_Sensor_Conv_SafeCopy2
        MemAbstractMdl_Get_Default_BsConst_PWM_boost_bypass_duty
        MemAbstractMdl_Get_Default_BsConst_PWM_boost_bypass_duty_SafeCopy1
        MemAbstractMdl_Get_Default_BsConst_PWM_boost_bypass_duty_SafeCopy2
        MemAbstractMdl_Get_Default_BsConst_PowerGauge_Element
        MemAbstractMdl_Get_Default_BsConst_Power_Element
        MemAbstractMdl_Get_Default_BsConst_RealTimeClock_Element
        MemAbstractMdl_Get_Default_BsConst_ServiceReminder_Element
        MemAbstractMdl_Get_Default_BsConst_SpeedoGauge_Element
        MemAbstractMdl_Get_Default_BsConst_TachoGauge_Element
        MemAbstractMdl_Get_Default_BsConst_TempGauge_Element
        MemAbstractMdl_Get_Default_BsConst_Temp_Threshold_Hysteresis_Derating
        MemAbstractMdl_Get_Default_BsConst_Temp_Threshold_Hysteresis_Derating_SafeCopy1
        MemAbstractMdl_Get_Default_BsConst_Temp_Threshold_Hysteresis_Derating_SafeCopy2
        MemAbstractMdl_Get_Default_BsConst_Temperature_Sensor_Conv
        MemAbstractMdl_Get_Default_BsConst_Temperature_Sensor_Conv_SafeCopy1
        MemAbstractMdl_Get_Default_BsConst_Temperature_Sensor_Conv_SafeCopy2
        MemAbstractMdl_Get_Default_BsConst_TripComputer_Element
        MemAbstractMdl_Get_Default_BsConst_Warning_Element
        MemAbstractMdl_Get_Default_BsCys_Certicificate_Element
        MemAbstractMdl_Get_Default_BsDiag_Dtc_Element
        MemAbstractMdl_Get_Default_BsDiag_ErrorRecord_Element
        MemAbstractMdl_Get_Default_BsReten_Audio_Element
        MemAbstractMdl_Get_Default_BsReten_Communication_Element
        MemAbstractMdl_Get_Default_BsReten_Display_Element
        MemAbstractMdl_Get_Default_BsReten_Gauges_Element
        MemAbstractMdl_Get_Default_BsReten_Illumination_Element
        MemAbstractMdl_Get_Default_BsReten_Odometer_Element
        MemAbstractMdl_Get_Default_BsReten_Personalization_Element
        MemAbstractMdl_Get_Default_BsReten_Power_Element
        MemAbstractMdl_Get_Default_BsReten_RealTimeClock_Element
        MemAbstractMdl_Get_Default_BsReten_Tripcomputer_Element
        MemAbstractMdl_Get_Default_BsReten_VisDlt_Element
        MemAbstractMdl_Get_Default_BsReten_Warning_Element
        MemAbstractMdl_Get_Default_BsRt_CusDlt_Element
        MemAbstractMdl_Get_Default_BsRt_FuelGauge_Element
        MemAbstractMdl_Get_Default_BsRt_Illumination_Element
        MemAbstractMdl_Get_Default_BsRt_Odometer_Element
        MemAbstractMdl_Get_Default_BsRt_OilGauge_Element
        MemAbstractMdl_Get_Default_BsRt_Personalization_Element
        MemAbstractMdl_Get_Default_BsRt_PowerGauge_Element
        MemAbstractMdl_Get_Default_BsRt_RealTimeClock_Element
        MemAbstractMdl_Get_Default_BsRt_SpeedoGauge_Element
        MemAbstractMdl_Get_Default_BsRt_TachoGauge_Element
        MemAbstractMdl_Get_Default_BsRt_TempGauge_Element
        MemAbstractMdl_Get_Default_BsRt_TripComputer_Element
        MemAbstractMdl_Get_Default_BsRt_Warning_Element
        MemAbstractMdl_Get_Default_BsShare_AssemblyManufacturingDate
        MemAbstractMdl_Get_Default_BsShare_AssemblyPlantNumber
        MemAbstractMdl_Get_Default_BsShare_EcuPartNumber_Element
        MemAbstractMdl_Get_Default_BsShare_HWModification
        MemAbstractMdl_Get_Default_BsShare_PCBSerialNumber
        MemAbstractMdl_Get_Default_BsShare_ProductSerialNumber
        MemAbstractMdl_Get_Default_BsShare_SMTManufacturingDate
        MemAbstractMdl_Get_Default_BsShare_SMTPlantNumber
        MemAbstractMdl_Get_Default_BsShare_SwUpdFotaFinPrint_Element
        MemAbstractMdl_Get_Default_BsShare_SwUpdFotaMode_Element
        MemAbstractMdl_Get_Default_BsShare_SwUpdFotaStatus_Element
        MemAbstractMdl_Get_Default_BsShare_SwUpdFotadecrypt_Element
        MemAbstractMdl_Get_Default_BsShare_SwUpdReflash_Element
        MemAbstractMdl_Get_Default_BsShare_VehicleConfig_Element
        MemAbstractMdl_Get_Default_BsShare_VisMeet_EOLEntry_Element
        MemAbstractMdl_Get_Default_BsShare_VisMeet_Element
        MemAbstractMdl_Get_Default_BsShare_VisteonPCBPartNumber
        MemAbstractMdl_Get_Default_BsShare_VisteonPartNumber
        MemAbstractMdl_Get_Default_RefCys_Certicificate1_Element
        MemAbstractMdl_Get_Default_RefCys_Certicificate_Element
        MemAbstractMdl_Get_RefCys_Certicificate1_Element
        MemAbstractMdl_Get_RefCys_Certicificate_Element
        MemAbstractMdl_NvmWriteStatus
        MemAbstractMdl_Set_BsConst_Audio_Element
        MemAbstractMdl_Set_BsConst_BsConst_Illumination_ReservedByte
        MemAbstractMdl_Set_BsConst_BsConst_Illumination_ReservedByte_SafeCopy1
        MemAbstractMdl_Set_BsConst_BsConst_Illumination_ReservedByte_SafeCopy2
        MemAbstractMdl_Set_BsConst_Communication_Element
        MemAbstractMdl_Set_BsConst_Compensation_Line_Shift_b
        MemAbstractMdl_Set_BsConst_Compensation_Line_Shift_b_SafeCopy1
        MemAbstractMdl_Set_BsConst_Compensation_Line_Shift_b_SafeCopy2
        MemAbstractMdl_Set_BsConst_Compensation_Line_Slope_m
        MemAbstractMdl_Set_BsConst_Compensation_Line_Slope_m_SafeCopy1
        MemAbstractMdl_Set_BsConst_Compensation_Line_Slope_m_SafeCopy2
        MemAbstractMdl_Set_BsConst_Derating_Backlight_Disable
        MemAbstractMdl_Set_BsConst_Derating_Backlight_Disable_SafeCopy1
        MemAbstractMdl_Set_BsConst_Derating_Backlight_Disable_SafeCopy2
        MemAbstractMdl_Set_BsConst_Display_Illum_Max_Level
        MemAbstractMdl_Set_BsConst_Display_Illum_Max_Level_SafeCopy1
        MemAbstractMdl_Set_BsConst_Display_Illum_Max_Level_SafeCopy2
        MemAbstractMdl_Set_BsConst_EngOffTimer_Element
        MemAbstractMdl_Set_BsConst_FuelGauge_Element
        MemAbstractMdl_Set_BsConst_Lookup_Curve_HotSpot_Coef_X
        MemAbstractMdl_Set_BsConst_Lookup_Curve_HotSpot_Coef_X_SafeCopy1
        MemAbstractMdl_Set_BsConst_Lookup_Curve_HotSpot_Coef_X_SafeCopy2
        MemAbstractMdl_Set_BsConst_Lookup_Curve_HotSpot_Coef_Y
        MemAbstractMdl_Set_BsConst_Lookup_Curve_HotSpot_Coef_Y_SafeCopy1
        MemAbstractMdl_Set_BsConst_Lookup_Curve_HotSpot_Coef_Y_SafeCopy2
        MemAbstractMdl_Set_BsConst_OilGauge_Element
        MemAbstractMdl_Set_BsConst_PCB_Temperature_Sensor_Conv
        MemAbstractMdl_Set_BsConst_PCB_Temperature_Sensor_Conv_SafeCopy1
        MemAbstractMdl_Set_BsConst_PCB_Temperature_Sensor_Conv_SafeCopy2
        MemAbstractMdl_Set_BsConst_PWM_boost_bypass_duty
        MemAbstractMdl_Set_BsConst_PWM_boost_bypass_duty_SafeCopy1
        MemAbstractMdl_Set_BsConst_PWM_boost_bypass_duty_SafeCopy2
        MemAbstractMdl_Set_BsConst_PowerGauge_Element
        MemAbstractMdl_Set_BsConst_Power_Element
        MemAbstractMdl_Set_BsConst_RealTimeClock_Element
        MemAbstractMdl_Set_BsConst_ServiceReminder_Element
        MemAbstractMdl_Set_BsConst_SpeedoGauge_Element
        MemAbstractMdl_Set_BsConst_TachoGauge_Element
        MemAbstractMdl_Set_BsConst_TempGauge_Element
        MemAbstractMdl_Set_BsConst_Temp_Threshold_Hysteresis_Derating
        MemAbstractMdl_Set_BsConst_Temp_Threshold_Hysteresis_Derating_SafeCopy1
        MemAbstractMdl_Set_BsConst_Temp_Threshold_Hysteresis_Derating_SafeCopy2
        MemAbstractMdl_Set_BsConst_Temperature_Sensor_Conv
        MemAbstractMdl_Set_BsConst_Temperature_Sensor_Conv_SafeCopy1
        MemAbstractMdl_Set_BsConst_Temperature_Sensor_Conv_SafeCopy2
        MemAbstractMdl_Set_BsConst_TripComputer_Element
        MemAbstractMdl_Set_BsConst_Warning_Element
        MemAbstractMdl_Set_BsCys_Certicificate_Element
        MemAbstractMdl_Set_BsDiag_Dtc_Element
        MemAbstractMdl_Set_BsDiag_ErrorRecord_Element
        MemAbstractMdl_Set_BsReten_Audio_Element
        MemAbstractMdl_Set_BsReten_Communication_Element
        MemAbstractMdl_Set_BsReten_Display_Element
        MemAbstractMdl_Set_BsReten_Gauges_Element
        MemAbstractMdl_Set_BsReten_Illumination_Element
        MemAbstractMdl_Set_BsReten_Odometer_Element
        MemAbstractMdl_Set_BsReten_Personalization_Element
        MemAbstractMdl_Set_BsReten_Power_Element
        MemAbstractMdl_Set_BsReten_RealTimeClock_Element
        MemAbstractMdl_Set_BsReten_Tripcomputer_Element
        MemAbstractMdl_Set_BsReten_VisDlt_Element
        MemAbstractMdl_Set_BsReten_Warning_Element
        MemAbstractMdl_Set_BsRt_CusDlt_Element
        MemAbstractMdl_Set_BsRt_FuelGauge_Element
        MemAbstractMdl_Set_BsRt_Illumination_Element
        MemAbstractMdl_Set_BsRt_Odometer_Element
        MemAbstractMdl_Set_BsRt_OilGauge_Element
        MemAbstractMdl_Set_BsRt_Personalization_Element
        MemAbstractMdl_Set_BsRt_PowerGauge_Element
        MemAbstractMdl_Set_BsRt_RealTimeClock_Element
        MemAbstractMdl_Set_BsRt_SpeedoGauge_Element
        MemAbstractMdl_Set_BsRt_TachoGauge_Element
        MemAbstractMdl_Set_BsRt_TempGauge_Element
        MemAbstractMdl_Set_BsRt_TripComputer_Element
        MemAbstractMdl_Set_BsRt_Warning_Element
        MemAbstractMdl_Set_BsShare_AssemblyManufacturingDate
        MemAbstractMdl_Set_BsShare_AssemblyPlantNumber
        MemAbstractMdl_Set_BsShare_EcuPartNumber_Element
        MemAbstractMdl_Set_BsShare_HWModification
        MemAbstractMdl_Set_BsShare_PCBSerialNumber
        MemAbstractMdl_Set_BsShare_ProductSerialNumber
        MemAbstractMdl_Set_BsShare_SMTManufacturingDate
        MemAbstractMdl_Set_BsShare_SMTPlantNumber
        MemAbstractMdl_Set_BsShare_SwUpdFotaFinPrint_Element
        MemAbstractMdl_Set_BsShare_SwUpdFotaMode_Element
        MemAbstractMdl_Set_BsShare_SwUpdFotaStatus_Element
        MemAbstractMdl_Set_BsShare_SwUpdFotadecrypt_Element
        MemAbstractMdl_Set_BsShare_SwUpdReflash_Element
        MemAbstractMdl_Set_BsShare_VehicleConfig_Element
        MemAbstractMdl_Set_BsShare_VisMeet_EOLEntry_Element
        MemAbstractMdl_Set_BsShare_VisMeet_Element
        MemAbstractMdl_Set_BsShare_VisteonPCBPartNumber
        MemAbstractMdl_Set_BsShare_VisteonPartNumber
        MemAbstractMdl_Set_RefCys_Certicificate1_Element
        MemAbstractMdl_Set_RefCys_Certicificate_Element
  95 x constant specification:
    MemAbstractMdlJobStatus_BsConst_Audio_ElementValue0: value-spec=MemAbstractMdlJobStatus_BsConst_Audio_ElementValue0:0
    MemAbstractMdlJobStatus_BsConst_BsConst_Illumination_ReservedByteValue0: value-spec=MemAbstractMdlJobStatus_BsConst_BsConst_Illumination_ReservedByteValue0:0
    MemAbstractMdlJobStatus_BsConst_BsConst_Illumination_ReservedByte_SafeCopy1Value0: value-spec=MemAbstractMdlJobStatus_BsConst_BsConst_Illumination_ReservedByte_SafeCopy1Value0:0
    MemAbstractMdlJobStatus_BsConst_BsConst_Illumination_ReservedByte_SafeCopy2Value0: value-spec=MemAbstractMdlJobStatus_BsConst_BsConst_Illumination_ReservedByte_SafeCopy2Value0:0
    MemAbstractMdlJobStatus_BsConst_Communication_ElementValue0: value-spec=MemAbstractMdlJobStatus_BsConst_Communication_ElementValue0:0
    MemAbstractMdlJobStatus_BsConst_Compensation_Line_Shift_bValue0: value-spec=MemAbstractMdlJobStatus_BsConst_Compensation_Line_Shift_bValue0:0
    MemAbstractMdlJobStatus_BsConst_Compensation_Line_Shift_b_SafeCopy1Value0: value-spec=MemAbstractMdlJobStatus_BsConst_Compensation_Line_Shift_b_SafeCopy1Value0:0
    MemAbstractMdlJobStatus_BsConst_Compensation_Line_Shift_b_SafeCopy2Value0: value-spec=MemAbstractMdlJobStatus_BsConst_Compensation_Line_Shift_b_SafeCopy2Value0:0
    MemAbstractMdlJobStatus_BsConst_Compensation_Line_Slope_mValue0: value-spec=MemAbstractMdlJobStatus_BsConst_Compensation_Line_Slope_mValue0:0
    MemAbstractMdlJobStatus_BsConst_Compensation_Line_Slope_m_SafeCopy1Value0: value-spec=MemAbstractMdlJobStatus_BsConst_Compensation_Line_Slope_m_SafeCopy1Value0:0
    MemAbstractMdlJobStatus_BsConst_Compensation_Line_Slope_m_SafeCopy2Value0: value-spec=MemAbstractMdlJobStatus_BsConst_Compensation_Line_Slope_m_SafeCopy2Value0:0
    MemAbstractMdlJobStatus_BsConst_Derating_Backlight_DisableValue0: value-spec=MemAbstractMdlJobStatus_BsConst_Derating_Backlight_DisableValue0:0
    MemAbstractMdlJobStatus_BsConst_Derating_Backlight_Disable_SafeCopy1Value0: value-spec=MemAbstractMdlJobStatus_BsConst_Derating_Backlight_Disable_SafeCopy1Value0:0
    MemAbstractMdlJobStatus_BsConst_Derating_Backlight_Disable_SafeCopy2Value0: value-spec=MemAbstractMdlJobStatus_BsConst_Derating_Backlight_Disable_SafeCopy2Value0:0
    MemAbstractMdlJobStatus_BsConst_Display_Illum_Max_LevelValue0: value-spec=MemAbstractMdlJobStatus_BsConst_Display_Illum_Max_LevelValue0:0
    MemAbstractMdlJobStatus_BsConst_Display_Illum_Max_Level_SafeCopy1Value0: value-spec=MemAbstractMdlJobStatus_BsConst_Display_Illum_Max_Level_SafeCopy1Value0:0
    MemAbstractMdlJobStatus_BsConst_Display_Illum_Max_Level_SafeCopy2Value0: value-spec=MemAbstractMdlJobStatus_BsConst_Display_Illum_Max_Level_SafeCopy2Value0:0
    MemAbstractMdlJobStatus_BsConst_EngOffTimer_ElementValue0: value-spec=MemAbstractMdlJobStatus_BsConst_EngOffTimer_ElementValue0:0
    MemAbstractMdlJobStatus_BsConst_FuelGauge_ElementValue0: value-spec=MemAbstractMdlJobStatus_BsConst_FuelGauge_ElementValue0:0
    MemAbstractMdlJobStatus_BsConst_Lookup_Curve_HotSpot_Coef_XValue0: value-spec=MemAbstractMdlJobStatus_BsConst_Lookup_Curve_HotSpot_Coef_XValue0:0
    MemAbstractMdlJobStatus_BsConst_Lookup_Curve_HotSpot_Coef_X_SafeCopy1Value0: value-spec=MemAbstractMdlJobStatus_BsConst_Lookup_Curve_HotSpot_Coef_X_SafeCopy1Value0:0
    MemAbstractMdlJobStatus_BsConst_Lookup_Curve_HotSpot_Coef_X_SafeCopy2Value0: value-spec=MemAbstractMdlJobStatus_BsConst_Lookup_Curve_HotSpot_Coef_X_SafeCopy2Value0:0
    MemAbstractMdlJobStatus_BsConst_Lookup_Curve_HotSpot_Coef_YValue0: value-spec=MemAbstractMdlJobStatus_BsConst_Lookup_Curve_HotSpot_Coef_YValue0:0
    MemAbstractMdlJobStatus_BsConst_Lookup_Curve_HotSpot_Coef_Y_SafeCopy1Value0: value-spec=MemAbstractMdlJobStatus_BsConst_Lookup_Curve_HotSpot_Coef_Y_SafeCopy1Value0:0
    MemAbstractMdlJobStatus_BsConst_Lookup_Curve_HotSpot_Coef_Y_SafeCopy2Value0: value-spec=MemAbstractMdlJobStatus_BsConst_Lookup_Curve_HotSpot_Coef_Y_SafeCopy2Value0:0
    MemAbstractMdlJobStatus_BsConst_OilGauge_ElementValue0: value-spec=MemAbstractMdlJobStatus_BsConst_OilGauge_ElementValue0:0
    MemAbstractMdlJobStatus_BsConst_PCB_Temperature_Sensor_ConvValue0: value-spec=MemAbstractMdlJobStatus_BsConst_PCB_Temperature_Sensor_ConvValue0:0
    MemAbstractMdlJobStatus_BsConst_PCB_Temperature_Sensor_Conv_SafeCopy1Value0: value-spec=MemAbstractMdlJobStatus_BsConst_PCB_Temperature_Sensor_Conv_SafeCopy1Value0:0
    MemAbstractMdlJobStatus_BsConst_PCB_Temperature_Sensor_Conv_SafeCopy2Value0: value-spec=MemAbstractMdlJobStatus_BsConst_PCB_Temperature_Sensor_Conv_SafeCopy2Value0:0
    MemAbstractMdlJobStatus_BsConst_PWM_boost_bypass_dutyValue0: value-spec=MemAbstractMdlJobStatus_BsConst_PWM_boost_bypass_dutyValue0:0
    MemAbstractMdlJobStatus_BsConst_PWM_boost_bypass_duty_SafeCopy1Value0: value-spec=MemAbstractMdlJobStatus_BsConst_PWM_boost_bypass_duty_SafeCopy1Value0:0
    MemAbstractMdlJobStatus_BsConst_PWM_boost_bypass_duty_SafeCopy2Value0: value-spec=MemAbstractMdlJobStatus_BsConst_PWM_boost_bypass_duty_SafeCopy2Value0:0
    MemAbstractMdlJobStatus_BsConst_PowerGauge_ElementValue0: value-spec=MemAbstractMdlJobStatus_BsConst_PowerGauge_ElementValue0:0
    MemAbstractMdlJobStatus_BsConst_Power_ElementValue0: value-spec=MemAbstractMdlJobStatus_BsConst_Power_ElementValue0:0
    MemAbstractMdlJobStatus_BsConst_RealTimeClock_ElementValue0: value-spec=MemAbstractMdlJobStatus_BsConst_RealTimeClock_ElementValue0:0
    MemAbstractMdlJobStatus_BsConst_ServiceReminder_ElementValue0: value-spec=MemAbstractMdlJobStatus_BsConst_ServiceReminder_ElementValue0:0
    MemAbstractMdlJobStatus_BsConst_SpeedoGauge_ElementValue0: value-spec=MemAbstractMdlJobStatus_BsConst_SpeedoGauge_ElementValue0:0
    MemAbstractMdlJobStatus_BsConst_TachoGauge_ElementValue0: value-spec=MemAbstractMdlJobStatus_BsConst_TachoGauge_ElementValue0:0
    MemAbstractMdlJobStatus_BsConst_TempGauge_ElementValue0: value-spec=MemAbstractMdlJobStatus_BsConst_TempGauge_ElementValue0:0
    MemAbstractMdlJobStatus_BsConst_Temp_Threshold_Hysteresis_DeratingValue0: value-spec=MemAbstractMdlJobStatus_BsConst_Temp_Threshold_Hysteresis_DeratingValue0:0
    MemAbstractMdlJobStatus_BsConst_Temp_Threshold_Hysteresis_Derating_SafeCopy1Value0: value-spec=MemAbstractMdlJobStatus_BsConst_Temp_Threshold_Hysteresis_Derating_SafeCopy1Value0:0
    MemAbstractMdlJobStatus_BsConst_Temp_Threshold_Hysteresis_Derating_SafeCopy2Value0: value-spec=MemAbstractMdlJobStatus_BsConst_Temp_Threshold_Hysteresis_Derating_SafeCopy2Value0:0
    MemAbstractMdlJobStatus_BsConst_Temperature_Sensor_ConvValue0: value-spec=MemAbstractMdlJobStatus_BsConst_Temperature_Sensor_ConvValue0:0
    MemAbstractMdlJobStatus_BsConst_Temperature_Sensor_Conv_SafeCopy1Value0: value-spec=MemAbstractMdlJobStatus_BsConst_Temperature_Sensor_Conv_SafeCopy1Value0:0
    MemAbstractMdlJobStatus_BsConst_Temperature_Sensor_Conv_SafeCopy2Value0: value-spec=MemAbstractMdlJobStatus_BsConst_Temperature_Sensor_Conv_SafeCopy2Value0:0
    MemAbstractMdlJobStatus_BsConst_TripComputer_ElementValue0: value-spec=MemAbstractMdlJobStatus_BsConst_TripComputer_ElementValue0:0
    MemAbstractMdlJobStatus_BsConst_Warning_ElementValue0: value-spec=MemAbstractMdlJobStatus_BsConst_Warning_ElementValue0:0
    MemAbstractMdlJobStatus_BsCys_Certicificate_ElementValue0: value-spec=MemAbstractMdlJobStatus_BsCys_Certicificate_ElementValue0:0
    MemAbstractMdlJobStatus_BsDiag_Dtc_ElementValue0: value-spec=MemAbstractMdlJobStatus_BsDiag_Dtc_ElementValue0:0
    MemAbstractMdlJobStatus_BsDiag_ErrorRecord_ElementValue0: value-spec=MemAbstractMdlJobStatus_BsDiag_ErrorRecord_ElementValue0:0
    MemAbstractMdlJobStatus_BsReten_Audio_ElementValue0: value-spec=MemAbstractMdlJobStatus_BsReten_Audio_ElementValue0:0
    MemAbstractMdlJobStatus_BsReten_Communication_ElementValue0: value-spec=MemAbstractMdlJobStatus_BsReten_Communication_ElementValue0:0
    MemAbstractMdlJobStatus_BsReten_Display_ElementValue0: value-spec=MemAbstractMdlJobStatus_BsReten_Display_ElementValue0:0
    MemAbstractMdlJobStatus_BsReten_Gauges_ElementValue0: value-spec=MemAbstractMdlJobStatus_BsReten_Gauges_ElementValue0:0
    MemAbstractMdlJobStatus_BsReten_Illumination_ElementValue0: value-spec=MemAbstractMdlJobStatus_BsReten_Illumination_ElementValue0:0
    MemAbstractMdlJobStatus_BsReten_Odometer_ElementValue0: value-spec=MemAbstractMdlJobStatus_BsReten_Odometer_ElementValue0:0
    MemAbstractMdlJobStatus_BsReten_Personalization_ElementValue0: value-spec=MemAbstractMdlJobStatus_BsReten_Personalization_ElementValue0:0
    MemAbstractMdlJobStatus_BsReten_Power_ElementValue0: value-spec=MemAbstractMdlJobStatus_BsReten_Power_ElementValue0:0
    MemAbstractMdlJobStatus_BsReten_RealTimeClock_ElementValue0: value-spec=MemAbstractMdlJobStatus_BsReten_RealTimeClock_ElementValue0:0
    MemAbstractMdlJobStatus_BsReten_Tripcomputer_ElementValue0: value-spec=MemAbstractMdlJobStatus_BsReten_Tripcomputer_ElementValue0:0
    MemAbstractMdlJobStatus_BsReten_VisDlt_ElementValue0: value-spec=MemAbstractMdlJobStatus_BsReten_VisDlt_ElementValue0:0
    MemAbstractMdlJobStatus_BsReten_Warning_ElementValue0: value-spec=MemAbstractMdlJobStatus_BsReten_Warning_ElementValue0:0
    MemAbstractMdlJobStatus_BsRt_CusDlt_ElementValue0: value-spec=MemAbstractMdlJobStatus_BsRt_CusDlt_ElementValue0:0
    MemAbstractMdlJobStatus_BsRt_FuelGauge_ElementValue0: value-spec=MemAbstractMdlJobStatus_BsRt_FuelGauge_ElementValue0:0
    MemAbstractMdlJobStatus_BsRt_Illumination_ElementValue0: value-spec=MemAbstractMdlJobStatus_BsRt_Illumination_ElementValue0:0
    MemAbstractMdlJobStatus_BsRt_Odometer_ElementValue0: value-spec=MemAbstractMdlJobStatus_BsRt_Odometer_ElementValue0:0
    MemAbstractMdlJobStatus_BsRt_OilGauge_ElementValue0: value-spec=MemAbstractMdlJobStatus_BsRt_OilGauge_ElementValue0:0
    MemAbstractMdlJobStatus_BsRt_Personalization_ElementValue0: value-spec=MemAbstractMdlJobStatus_BsRt_Personalization_ElementValue0:0
    MemAbstractMdlJobStatus_BsRt_PowerGauge_ElementValue0: value-spec=MemAbstractMdlJobStatus_BsRt_PowerGauge_ElementValue0:0
    MemAbstractMdlJobStatus_BsRt_RealTimeClock_ElementValue0: value-spec=MemAbstractMdlJobStatus_BsRt_RealTimeClock_ElementValue0:0
    MemAbstractMdlJobStatus_BsRt_SpeedoGauge_ElementValue0: value-spec=MemAbstractMdlJobStatus_BsRt_SpeedoGauge_ElementValue0:0
    MemAbstractMdlJobStatus_BsRt_TachoGauge_ElementValue0: value-spec=MemAbstractMdlJobStatus_BsRt_TachoGauge_ElementValue0:0
    MemAbstractMdlJobStatus_BsRt_TempGauge_ElementValue0: value-spec=MemAbstractMdlJobStatus_BsRt_TempGauge_ElementValue0:0
    MemAbstractMdlJobStatus_BsRt_TripComputer_ElementValue0: value-spec=MemAbstractMdlJobStatus_BsRt_TripComputer_ElementValue0:0
    MemAbstractMdlJobStatus_BsRt_Warning_ElementValue0: value-spec=MemAbstractMdlJobStatus_BsRt_Warning_ElementValue0:0
    MemAbstractMdlJobStatus_BsShare_AssemblyManufacturingDateValue0: value-spec=MemAbstractMdlJobStatus_BsShare_AssemblyManufacturingDateValue0:0
    MemAbstractMdlJobStatus_BsShare_AssemblyPlantNumberValue0: value-spec=MemAbstractMdlJobStatus_BsShare_AssemblyPlantNumberValue0:0
    MemAbstractMdlJobStatus_BsShare_EcuPartNumber_ElementValue0: value-spec=MemAbstractMdlJobStatus_BsShare_EcuPartNumber_ElementValue0:0
    MemAbstractMdlJobStatus_BsShare_HWModificationValue0: value-spec=MemAbstractMdlJobStatus_BsShare_HWModificationValue0:0
    MemAbstractMdlJobStatus_BsShare_PCBSerialNumberValue0: value-spec=MemAbstractMdlJobStatus_BsShare_PCBSerialNumberValue0:0
    MemAbstractMdlJobStatus_BsShare_ProductSerialNumberValue0: value-spec=MemAbstractMdlJobStatus_BsShare_ProductSerialNumberValue0:0
    MemAbstractMdlJobStatus_BsShare_SMTManufacturingDateValue0: value-spec=MemAbstractMdlJobStatus_BsShare_SMTManufacturingDateValue0:0
    MemAbstractMdlJobStatus_BsShare_SMTPlantNumberValue0: value-spec=MemAbstractMdlJobStatus_BsShare_SMTPlantNumberValue0:0
    MemAbstractMdlJobStatus_BsShare_SwUpdFotaFinPrint_ElementValue0: value-spec=MemAbstractMdlJobStatus_BsShare_SwUpdFotaFinPrint_ElementValue0:0
    MemAbstractMdlJobStatus_BsShare_SwUpdFotaMode_ElementValue0: value-spec=MemAbstractMdlJobStatus_BsShare_SwUpdFotaMode_ElementValue0:0
    MemAbstractMdlJobStatus_BsShare_SwUpdFotaStatus_ElementValue0: value-spec=MemAbstractMdlJobStatus_BsShare_SwUpdFotaStatus_ElementValue0:0
    MemAbstractMdlJobStatus_BsShare_SwUpdFotadecrypt_ElementValue0: value-spec=MemAbstractMdlJobStatus_BsShare_SwUpdFotadecrypt_ElementValue0:0
    MemAbstractMdlJobStatus_BsShare_SwUpdReflash_ElementValue0: value-spec=MemAbstractMdlJobStatus_BsShare_SwUpdReflash_ElementValue0:0
    MemAbstractMdlJobStatus_BsShare_VehicleConfig_ElementValue0: value-spec=MemAbstractMdlJobStatus_BsShare_VehicleConfig_ElementValue0:0
    MemAbstractMdlJobStatus_BsShare_VisMeet_EOLEntry_ElementValue0: value-spec=MemAbstractMdlJobStatus_BsShare_VisMeet_EOLEntry_ElementValue0:0
    MemAbstractMdlJobStatus_BsShare_VisMeet_ElementValue0: value-spec=MemAbstractMdlJobStatus_BsShare_VisMeet_ElementValue0:0
    MemAbstractMdlJobStatus_BsShare_VisteonPCBPartNumberValue0: value-spec=MemAbstractMdlJobStatus_BsShare_VisteonPCBPartNumberValue0:0
    MemAbstractMdlJobStatus_BsShare_VisteonPartNumberValue0: value-spec=MemAbstractMdlJobStatus_BsShare_VisteonPartNumberValue0:0
    MemAbstractMdlJobStatus_RefCys_Certicificate1_ElementValue0: value-spec=MemAbstractMdlJobStatus_RefCys_Certicificate1_ElementValue0:0
    MemAbstractMdlJobStatus_RefCys_Certicificate_ElementValue0: value-spec=MemAbstractMdlJobStatus_RefCys_Certicificate_ElementValue0:0
  swc implementation IMPL_MemAbstractMdl: programming-language=C, behavior=IB_MemAbstractMdl
    code-descriptors:
      code CodeDescriptor
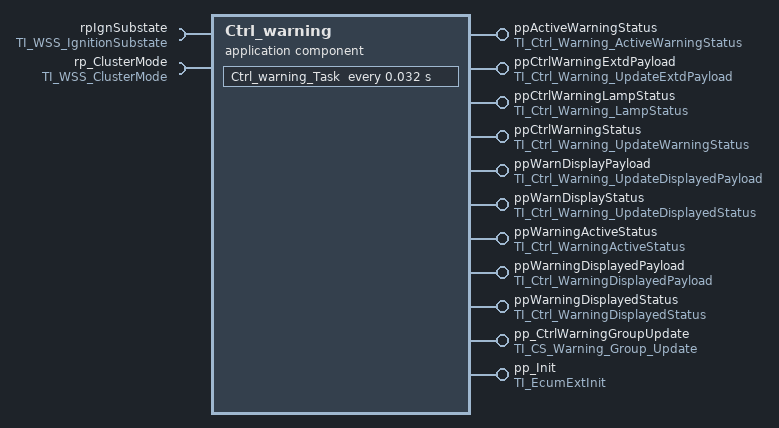
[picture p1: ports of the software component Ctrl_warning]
  application sw component type Ctrl_warning
    11 x provide port:
      ppActiveWarningStatus: server-com-spec{operation=GetActiveWarningStatus, queue-length=1}, provided-interface=TI_Ctrl_Warning_ActiveWarningStatus
      ppCtrlWarningExtdPayload: server-com-spec{operation=UpdateExtdPayload, queue-length=1}, provided-interface=TI_Ctrl_Warning_UpdateExtdPayload
      ppCtrlWarningLampStatus: provided-interface=TI_Ctrl_Warning_LampStatus
        provided-com-specs:
          operation=Get_Red_MasterLamp_Status, queue-length=1
          operation=Get_Yellow_MasterLamp_Status, queue-length=1
      ppCtrlWarningStatus: server-com-spec{operation=UpdateWarningStatus, queue-length=1}, provided-interface=TI_Ctrl_Warning_UpdateWarningStatus
      ppWarnDisplayPayload: server-com-spec{operation=SetWarningDisplayedPayload, queue-length=1}, provided-interface=TI_Ctrl_Warning_UpdateDisplayedPayload
      ppWarnDisplayStatus: server-com-spec{operation=SetWarningDisplayedStatus, queue-length=1}, provided-interface=TI_Ctrl_Warning_UpdateDisplayedStatus
      ppWarningActiveStatus: server-com-spec{operation=GetWarningActiveStatus, queue-length=1}, provided-interface=TI_Ctrl_WarningActiveStatus
      ppWarningDisplayedPayload: server-com-spec{operation=GetWarningDisplayedPayload, queue-length=1}, provided-interface=TI_Ctrl_WarningDisplayedPayload
      ppWarningDisplayedStatus: server-com-spec{operation=GetWarningDisplayedStatus, queue-length=1}, provided-interface=TI_Ctrl_WarningDisplayedStatus
      pp_CtrlWarningGroupUpdate: server-com-spec{operation=Warning_Group_update, queue-length=1}, provided-interface=TI_CS_Warning_Group_Update
      pp_Init: server-com-spec{operation=TI_EcumExtInit/Init, queue-length=1}, provided-interface=TI_EcumExtInit
    require port rpIgnSubstate: nonqueued-receiver-com-spec{data-element=IgnitionSubstate, init-value=constant-reference=Ctrl_warningIgnitionSubstateValue0}, required-interface=TI_WSS_IgnitionSubstate
    require port rp_ClusterMode: nonqueued-receiver-com-spec{data-element=WSSCurrentClusterMode, init-value=constant-reference=Ctrl_warningWSSCurrentClusterModeValue0}, required-interface=TI_WSS_ClusterMode
    behavior IB_Ctrl_warning
      9 x operation invoked event:
        OIE_ppActiveWarningStatus_Ctrl_warning_GetActiveWarningStatusTrigByGetActiveWarningStatus: start-on-event=Ctrl_warning_GetActiveWarningStatus, operation=ppActiveWarningStatus.GetActiveWarningStatus
        OIE_ppWarningActiveStatus_Ctrl_warning_GetWarningActiveStatusTrigByGetWarningActiveStatus: start-on-event=Ctrl_warning_GetWarningActiveStatus, operation=ppWarningActiveStatus.GetWarningActiveStatus
        OIE_ppWarningDisplayedPayload_Ctrl_warning_GetWarningDisplayedPayloadTrigByGetWarningDisplayedPayload: start-on-event=Ctrl_warning_GetWarningDisplayedPayload, operation=ppWarningDisplayedPayload.GetWarningDisplayedPayload
        OIE_ppWarningDisplayedStatus_Ctrl_warning_GetWarningDisplayedStatusTrigByGetWarningDisplayedStatus: start-on-event=Ctrl_warning_GetWarningDisplayedStatus, operation=ppWarningDisplayedStatus.GetWarningDisplayedStatus
        OIE_ppCtrlWarningLampStatus_Ctrl_warning_Get_Red_MasterLamp_StatusTrigByGet_Red_MasterLamp_Status: start-on-event=Ctrl_warning_Get_Red_MasterLamp_Status, operation=ppCtrlWarningLampStatus.Get_Red_MasterLamp_Status
        OIE_ppCtrlWarningLampStatus_Ctrl_warning_Get_Yellow_MasterLamp_StatusTrigByGet_Yellow_MasterLamp_Status: start-on-event=Ctrl_warning_Get_Yellow_MasterLamp_Status, operation=ppCtrlWarningLampStatus.Get_Yellow_MasterLamp_Status
        OIE_pp_Init_Ctrl_warning_InitTrigByInit: start-on-event=Ctrl_warning_Init, operation=pp_Init.Init
        OIE_ppWarnDisplayPayload_Ctrl_warning_SetWarningDisplayedPayloadTrigBySetWarningDisplayedPayload: start-on-event=Ctrl_warning_SetWarningDisplayedPayload, operation=ppWarnDisplayPayload.SetWarningDisplayedPayload
        OIE_ppWarnDisplayStatus_Ctrl_warning_SetWarningDisplayedStatusTrigBySetWarningDisplayedStatus: start-on-event=Ctrl_warning_SetWarningDisplayedStatus, operation=ppWarnDisplayStatus.SetWarningDisplayedStatus
      timing event TECtrl_warning_Task: start-on-event=Ctrl_warning_Task, period=0.032
      operation invoked event OIE_ppCtrlWarningExtdPayload_Ctrl_warning_UpdateExtdPayloadTrigByUpdateExtdPayload: start-on-event=Ctrl_warning_UpdateExtdPayload, operation=ppCtrlWarningExtdPayload.UpdateExtdPayload
      operation invoked event OIE_ppCtrlWarningStatus_Ctrl_warning_UpdateWarningStatusTrigByUpdateWarningStatus: start-on-event=Ctrl_warning_UpdateWarningStatus, operation=ppCtrlWarningStatus.UpdateWarningStatus
      operation invoked event OIE_pp_CtrlWarningGroupUpdate_Ctrl_warning_Warning_Group_updateTrigByWarning_Group_update: start-on-event=Ctrl_warning_Warning_Group_update, operation=pp_CtrlWarningGroupUpdate.Warning_Group_update
      port-api-options:
        enable-take-address=false, indirect-api=false, port=ppActiveWarningStatus
        enable-take-address=false, indirect-api=false, port=ppCtrlWarningExtdPayload
        enable-take-address=false, indirect-api=false, port=ppCtrlWarningLampStatus
        enable-take-address=false, indirect-api=false, port=ppCtrlWarningStatus
        enable-take-address=false, indirect-api=false, port=ppWarnDisplayPayload
        enable-take-address=false, indirect-api=false, port=ppWarnDisplayStatus
        enable-take-address=false, indirect-api=false, port=ppWarningActiveStatus
        enable-take-address=false, indirect-api=false, port=ppWarningDisplayedPayload
        enable-take-address=false, indirect-api=false, port=ppWarningDisplayedStatus
        enable-take-address=false, indirect-api=false, port=pp_CtrlWarningGroupUpdate
        enable-take-address=false, indirect-api=false, port=Ctrl_warning/pp_Init
        enable-take-address=false, indirect-api=false, port=Ctrl_warning/rpIgnSubstate
        enable-take-address=false, indirect-api=false, port=Ctrl_warning/rp_ClusterMode
      13 x runnable, all with can-be-invoked-concurrently=true:
        Ctrl_warning_GetActiveWarningStatus
        Ctrl_warning_GetWarningActiveStatus
        Ctrl_warning_GetWarningDisplayedPayload
        Ctrl_warning_GetWarningDisplayedStatus
        Ctrl_warning_Get_Red_MasterLamp_Status
        Ctrl_warning_Get_Yellow_MasterLamp_Status
        Ctrl_warning_Init
        Ctrl_warning_SetWarningDisplayedPayload
        Ctrl_warning_SetWarningDisplayedStatus
        Ctrl_warning_Task
          data-receive-point-by-arguments:
            access DRA_rpIgnSubstate_IgnitionSubstate: accessed-variable=rpIgnSubstate.IgnitionSubstate
            access DRA_rp_ClusterMode_WSSCurrentClusterMode: accessed-variable=rp_ClusterMode.WSSCurrentClusterMode
        Ctrl_warning_UpdateExtdPayload
        Ctrl_warning_UpdateWarningStatus
        Ctrl_warning_Warning_Group_update
  constant specification Ctrl_warningIgnitionSubstateValue0: value-spec=Ctrl_warningIgnitionSubstateValue0:0
  constant specification Ctrl_warningWSSCurrentClusterModeValue0: value-spec=Ctrl_warningWSSCurrentClusterModeValue0:0
  swc implementation IMPL_Ctrl_warning: programming-language=C, behavior=IB_Ctrl_warning
    code-descriptors:
      code CodeDescriptor
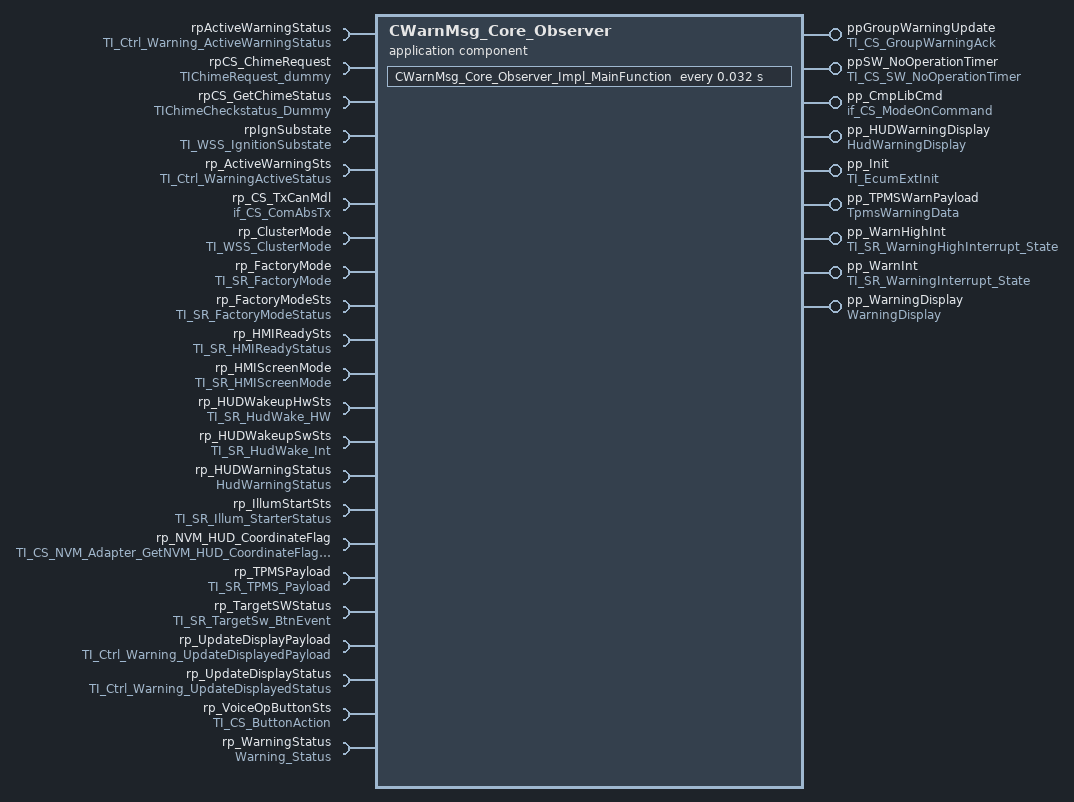
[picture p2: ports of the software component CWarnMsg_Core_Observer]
  application sw component type CWarnMsg_Core_Observer
    9 x provide port:
      ppGroupWarningUpdate: server-com-spec{operation=GroupWrnAck, queue-length=1}, provided-interface=TI_CS_GroupWarningAck
      ppSW_NoOperationTimer: server-com-spec{operation=SW_NoOperationTimer, queue-length=1}, provided-interface=TI_CS_SW_NoOperationTimer
      pp_CmpLibCmd: server-com-spec{operation=Impl_OnCommand, queue-length=1}, provided-interface=if_CS_ModeOnCommand
      pp_HUDWarningDisplay: nonqueued-sender-com-spec{data-element=HudWarningDisplayData, init-value=constant-reference=CWarnMsg_Core_ObserverHudWarningDisplayDataValue0}, provided-interface=HudWarningDisplay
      pp_Init: server-com-spec{operation=TI_EcumExtInit/Init, queue-length=1}, provided-interface=TI_EcumExtInit
      pp_TPMSWarnPayload: nonqueued-sender-com-spec{data-element=TpmsWarningDataData, init-value=constant-reference=CWarnMsg_Core_ObserverTpmsWarningDataDataValue0}, provided-interface=TpmsWarningData
      pp_WarnHighInt: nonqueued-sender-com-spec{data-element=WarningHighInterrupt_State, init-value=constant-reference=CWarnMsg_Core_ObserverWarningHighInterrupt_StateValue0}, provided-interface=TI_SR_WarningHighInterrupt_State
      pp_WarnInt: nonqueued-sender-com-spec{data-element=WarningInterrupt_State, init-value=constant-reference=CWarnMsg_Core_ObserverWarningInterrupt_StateValue0}, provided-interface=TI_SR_WarningInterrupt_State
      pp_WarningDisplay: nonqueued-sender-com-spec{data-element=WarningDisplayData, init-value=constant-reference=CWarnMsg_Core_ObserverWarningDisplayDataValue0}, provided-interface=WarningDisplay
    22 x require port:
      rpActiveWarningStatus: required-interface=TI_Ctrl_Warning_ActiveWarningStatus
      rpCS_ChimeRequest: nonqueued-receiver-com-spec{data-element=Chime_Request, init-value=constant-reference=CWarnMsg_Core_ObserverChime_RequestValue0}, required-interface=TIChimeRequest_dummy
      rpCS_GetChimeStatus: nonqueued-receiver-com-spec{data-element=Chime_Status, init-value=constant-reference=CWarnMsg_Core_ObserverChime_StatusValue0}, required-interface=TIChimeCheckstatus_Dummy
      rpIgnSubstate: nonqueued-receiver-com-spec{data-element=IgnitionSubstate, init-value=constant-reference=CWarnMsg_Core_ObserverIgnitionSubstateValue0}, required-interface=TI_WSS_IgnitionSubstate
      rp_ActiveWarningSts: required-interface=TI_Ctrl_WarningActiveStatus
      rp_CS_TxCanMdl: required-interface=if_CS_ComAbsTx
      rp_ClusterMode: nonqueued-receiver-com-spec{data-element=WSSCurrentClusterMode, init-value=constant-reference=CWarnMsg_Core_ObserverWSSCurrentClusterModeValue0}, required-interface=TI_WSS_ClusterMode
      rp_FactoryMode: nonqueued-receiver-com-spec{data-element=FactoryMode, init-value=constant-reference=CWarnMsg_Core_ObserverFactoryModeValue0}, required-interface=TI_SR_FactoryMode
      rp_FactoryModeSts: nonqueued-receiver-com-spec{data-element=FactoryModeStatus, init-value=constant-reference=CWarnMsg_Core_ObserverFactoryModeStatusValue0}, required-interface=TI_SR_FactoryModeStatus
      rp_HMIReadySts: nonqueued-receiver-com-spec{data-element=HMI_ReadyStatus, init-value=constant-reference=CWarnMsg_Core_ObserverHMI_ReadyStatusValue0}, required-interface=TI_SR_HMIReadyStatus
      rp_HMIScreenMode: nonqueued-receiver-com-spec{data-element=HMIScreenMode_Status, init-value=constant-reference=CWarnMsg_Core_ObserverHMIScreenMode_StatusValue0}, required-interface=TI_SR_HMIScreenMode
      rp_HUDWakeupHwSts: nonqueued-receiver-com-spec{data-element=WakeType_Hw, init-value=constant-reference=CWarnMsg_Core_ObserverWakeType_HwValue0}, required-interface=TI_SR_HudWake_HW
      rp_HUDWakeupSwSts: nonqueued-receiver-com-spec{data-element=WakeType_Int, init-value=constant-reference=CWarnMsg_Core_ObserverWakeType_IntValue0}, required-interface=TI_SR_HudWake_Int
      rp_HUDWarningStatus: nonqueued-receiver-com-spec{data-element=HudWarningStatusData, init-value=constant-reference=CWarnMsg_Core_ObserverHudWarningStatusDataValue0}, required-interface=HudWarningStatus
      rp_IllumStartSts: nonqueued-receiver-com-spec{data-element=StarterStatus_Out, init-value=constant-reference=CWarnMsg_Core_ObserverStarterStatus_OutValue0}, required-interface=TI_SR_Illum_StarterStatus
      rp_NVM_HUD_CoordinateFlag: nonqueued-receiver-com-spec{data-element=NvmData, init-value=constant-reference=CWarnMsg_Core_ObserverNvmDataValue0}, required-interface=TI_CS_NVM_Adapter_GetNVM_HUD_CoordinateFlag_Dummy
      rp_TPMSPayload: nonqueued-receiver-com-spec{data-element=Tpms_Payload, init-value=constant-reference=CWarnMsg_Core_ObserverTpms_PayloadValue0}, required-interface=TI_SR_TPMS_Payload
      rp_TargetSWStatus: nonqueued-receiver-com-spec{data-element=TargetSw, init-value=constant-reference=CWarnMsg_Core_ObserverTargetSwValue0}, required-interface=TI_SR_TargetSw_BtnEvent
      rp_UpdateDisplayPayload: required-interface=TI_Ctrl_Warning_UpdateDisplayedPayload
      rp_UpdateDisplayStatus: required-interface=TI_Ctrl_Warning_UpdateDisplayedStatus
      rp_VoiceOpButtonSts: required-interface=TI_CS_ButtonAction
      rp_WarningStatus: nonqueued-receiver-com-spec{data-element=WarningStatusData, init-value=constant-reference=CWarnMsg_Core_ObserverWarningStatusDataValue0}, required-interface=Warning_Status
    behavior IB_CWarnMsg_Core_Observer
      operation invoked event OIE_ppGroupWarningUpdate_CWarnMsg_Core_Observer_GroupWrnAckTrigByGroupWrnAck: start-on-event=CWarnMsg_Core_Observer_GroupWrnAck, operation=ppGroupWarningUpdate.GroupWrnAck
      timing event TECWarnMsg_Core_Observer_Impl_MainFunction: start-on-event=CWarnMsg_Core_Observer_Impl_MainFunction, period=0.032
      operation invoked event OIE_pp_CmpLibCmd_CWarnMsg_Core_Observer_Impl_OnCommandTrigByImpl_OnCommand: start-on-event=CWarnMsg_Core_Observer_Impl_OnCommand, operation=pp_CmpLibCmd.Impl_OnCommand
      operation invoked event OIE_pp_Init_CWarnMsg_Core_Observer_InitTrigByInit: start-on-event=CWarnMsg_Core_Observer_Init, operation=pp_Init.Init
      data received event DREOnDre_UCL_HudWarnStatusTrigByHudWarningStatusData: start-on-event=OnDre_UCL_HudWarnStatus, data=rp_HUDWarningStatus.HudWarningStatusData
      data received event DREOnDre_UCL_WarnStatusTrigByWarningStatusData: start-on-event=OnDre_UCL_WarnStatus, data=rp_WarningStatus.WarningStatusData
      operation invoked event OIE_ppSW_NoOperationTimer_CWarnMsg_Core_Observer_SW_NoOperationTimerTrigBySW_NoOperationTimer: start-on-event=CWarnMsg_Core_Observer_SW_NoOperationTimer, operation=ppSW_NoOperationTimer.SW_NoOperationTimer
      port-api-options:
        enable-take-address=false, indirect-api=false, port=ppGroupWarningUpdate
        enable-take-address=false, indirect-api=false, port=ppSW_NoOperationTimer
        enable-take-address=false, indirect-api=false, port=CWarnMsg_Core_Observer/pp_CmpLibCmd
        enable-take-address=false, indirect-api=false, port=pp_HUDWarningDisplay
        enable-take-address=false, indirect-api=false, port=CWarnMsg_Core_Observer/pp_Init
        enable-take-address=false, indirect-api=false, port=pp_TPMSWarnPayload
        enable-take-address=false, indirect-api=false, port=pp_WarnHighInt
        enable-take-address=false, indirect-api=false, port=pp_WarnInt
        enable-take-address=false, indirect-api=false, port=pp_WarningDisplay
        enable-take-address=false, indirect-api=false, port=rpActiveWarningStatus
        enable-take-address=false, indirect-api=false, port=CWarnMsg_Core_Observer/rpCS_ChimeRequest
        enable-take-address=false, indirect-api=false, port=rpCS_GetChimeStatus
        enable-take-address=false, indirect-api=false, port=CWarnMsg_Core_Observer/rpIgnSubstate
        enable-take-address=false, indirect-api=false, port=rp_ActiveWarningSts
        enable-take-address=false, indirect-api=false, port=CWarnMsg_Core_Observer/rp_CS_TxCanMdl
        enable-take-address=false, indirect-api=false, port=CWarnMsg_Core_Observer/rp_ClusterMode
        enable-take-address=false, indirect-api=false, port=rp_FactoryMode
        enable-take-address=false, indirect-api=false, port=rp_FactoryModeSts
        enable-take-address=false, indirect-api=false, port=rp_HMIReadySts
        enable-take-address=false, indirect-api=false, port=CWarnMsg_Core_Observer/rp_HMIScreenMode
        enable-take-address=false, indirect-api=false, port=rp_HUDWakeupHwSts
        enable-take-address=false, indirect-api=false, port=rp_HUDWakeupSwSts
        enable-take-address=false, indirect-api=false, port=rp_HUDWarningStatus
        enable-take-address=false, indirect-api=false, port=rp_IllumStartSts
        enable-take-address=false, indirect-api=false, port=rp_NVM_HUD_CoordinateFlag
        enable-take-address=false, indirect-api=false, port=rp_TPMSPayload
        enable-take-address=false, indirect-api=false, port=rp_TargetSWStatus
        enable-take-address=false, indirect-api=false, port=rp_UpdateDisplayPayload
        enable-take-address=false, indirect-api=false, port=rp_UpdateDisplayStatus
        enable-take-address=false, indirect-api=false, port=rp_VoiceOpButtonSts
        enable-take-address=false, indirect-api=false, port=rp_WarningStatus
      7 x runnable, all with can-be-invoked-concurrently=true:
        CWarnMsg_Core_Observer_GroupWrnAck
        CWarnMsg_Core_Observer_Impl_MainFunction
          data-receive-point-by-arguments:
            16 x access:
              DRA_rpCS_ChimeRequest_Chime_Request: accessed-variable=rpCS_ChimeRequest.Chime_Request
              DRA_rpCS_GetChimeStatus_Chime_Status: accessed-variable=rpCS_GetChimeStatus.Chime_Status
              DRA_rpIgnSubstate_IgnitionSubstate: accessed-variable=rpIgnSubstate.IgnitionSubstate
              DRA_rp_ClusterMode_WSSCurrentClusterMode: accessed-variable=rp_ClusterMode.WSSCurrentClusterMode
              DRA_rp_FactoryMode_FactoryMode: accessed-variable=rp_FactoryMode.FactoryMode
              DRA_rp_FactoryModeSts_FactoryModeStatus: accessed-variable=rp_FactoryModeSts.FactoryModeStatus
              DRA_rp_HMIReadySts_HMI_ReadyStatus: accessed-variable=rp_HMIReadySts.HMI_ReadyStatus
              DRA_rp_HMIScreenMode_HMIScreenMode_Status: accessed-variable=rp_HMIScreenMode.HMIScreenMode_Status
              DRA_rp_HUDWakeupHwSts_WakeType_Hw: accessed-variable=rp_HUDWakeupHwSts.WakeType_Hw
              DRA_rp_HUDWakeupSwSts_WakeType_Int: accessed-variable=rp_HUDWakeupSwSts.WakeType_Int
              DRA_rp_HUDWarningStatus_HudWarningStatusData: accessed-variable=rp_HUDWarningStatus.HudWarningStatusData
              DRA_rp_IllumStartSts_StarterStatus_Out: accessed-variable=rp_IllumStartSts.StarterStatus_Out
              DRA_rp_NVM_HUD_CoordinateFlag_NvmData: accessed-variable=rp_NVM_HUD_CoordinateFlag.NvmData
              DRA_rp_TPMSPayload_Tpms_Payload: accessed-variable=rp_TPMSPayload.Tpms_Payload
              DRA_rp_TargetSWStatus_TargetSw: accessed-variable=rp_TargetSWStatus.TargetSw
              DRA_rp_WarningStatus_WarningStatusData: accessed-variable=rp_WarningStatus.WarningStatusData
          data-send-points:
            5 x access:
              DWA_pp_HUDWarningDisplay_HudWarningDisplayData: accessed-variable=pp_HUDWarningDisplay.HudWarningDisplayData
              DWA_pp_TPMSWarnPayload_TpmsWarningDataData: accessed-variable=pp_TPMSWarnPayload.TpmsWarningDataData
              DWA_pp_WarnHighInt_WarningHighInterrupt_State: accessed-variable=pp_WarnHighInt.WarningHighInterrupt_State
              DWA_pp_WarnInt_WarningInterrupt_State: accessed-variable=pp_WarnInt.WarningInterrupt_State
              DWA_pp_WarningDisplay_WarningDisplayData: accessed-variable=pp_WarningDisplay.WarningDisplayData
          10 x sync call, all with timeout=0.0:
            OA_rpActiveWarningStatus_GetActiveWarningStatus: operation=rpActiveWarningStatus.GetActiveWarningStatus
            OA_rp_ActiveWarningSts_GetWarningActiveStatus: operation=rp_ActiveWarningSts.GetWarningActiveStatus
            OA_rp_CS_TxCanMdl_TxCan_ClearCanSignalTxConfirmation: operation=rp_CS_TxCanMdl.TxCan_ClearCanSignalTxConfirmation
            OA_rp_CS_TxCanMdl_TxCan_GetCanSignalTxConfirmation: operation=rp_CS_TxCanMdl.TxCan_GetCanSignalTxConfirmation
            OA_rp_CS_TxCanMdl_TxCan_SetSignalFromRetentionBuffer: operation=rp_CS_TxCanMdl.TxCan_SetSignalFromRetentionBuffer
            OA_rp_CS_TxCanMdl_TxCan_SetSignalValue: operation=rp_CS_TxCanMdl.TxCan_SetSignalValue
            OA_rp_CS_TxCanMdl_TxCan_SetSignalValueU8Arr: operation=rp_CS_TxCanMdl.TxCan_SetSignalValueU8Arr
            OA_rp_UpdateDisplayPayload_SetWarningDisplayedPayload: operation=rp_UpdateDisplayPayload.SetWarningDisplayedPayload
            OA_rp_UpdateDisplayStatus_SetWarningDisplayedStatus: operation=rp_UpdateDisplayStatus.SetWarningDisplayedStatus
            OA_rp_VoiceOpButtonSts_GetButtonStatus: operation=rp_VoiceOpButtonSts.GetButtonStatus
        CWarnMsg_Core_Observer_Impl_OnCommand
        CWarnMsg_Core_Observer_Init
        OnDre_UCL_HudWarnStatus
          data-receive-point-by-arguments:
            16 x access:
              DRA_rpCS_ChimeRequest_Chime_Request: accessed-variable=rpCS_ChimeRequest.Chime_Request
              DRA_rpCS_GetChimeStatus_Chime_Status: accessed-variable=rpCS_GetChimeStatus.Chime_Status
              DRA_rpIgnSubstate_IgnitionSubstate: accessed-variable=rpIgnSubstate.IgnitionSubstate
              DRA_rp_ClusterMode_WSSCurrentClusterMode: accessed-variable=rp_ClusterMode.WSSCurrentClusterMode
              DRA_rp_FactoryMode_FactoryMode: accessed-variable=rp_FactoryMode.FactoryMode
              DRA_rp_FactoryModeSts_FactoryModeStatus: accessed-variable=rp_FactoryModeSts.FactoryModeStatus
              DRA_rp_HMIReadySts_HMI_ReadyStatus: accessed-variable=rp_HMIReadySts.HMI_ReadyStatus
              DRA_rp_HMIScreenMode_HMIScreenMode_Status: accessed-variable=rp_HMIScreenMode.HMIScreenMode_Status
              DRA_rp_HUDWakeupHwSts_WakeType_Hw: accessed-variable=rp_HUDWakeupHwSts.WakeType_Hw
              DRA_rp_HUDWakeupSwSts_WakeType_Int: accessed-variable=rp_HUDWakeupSwSts.WakeType_Int
              DRA_rp_HUDWarningStatus_HudWarningStatusData: accessed-variable=rp_HUDWarningStatus.HudWarningStatusData
              DRA_rp_IllumStartSts_StarterStatus_Out: accessed-variable=rp_IllumStartSts.StarterStatus_Out
              DRA_rp_NVM_HUD_CoordinateFlag_NvmData: accessed-variable=rp_NVM_HUD_CoordinateFlag.NvmData
              DRA_rp_TPMSPayload_Tpms_Payload: accessed-variable=rp_TPMSPayload.Tpms_Payload
              DRA_rp_TargetSWStatus_TargetSw: accessed-variable=rp_TargetSWStatus.TargetSw
              DRA_rp_WarningStatus_WarningStatusData: accessed-variable=rp_WarningStatus.WarningStatusData
          data-send-points:
            5 x access:
              DWA_pp_HUDWarningDisplay_HudWarningDisplayData: accessed-variable=pp_HUDWarningDisplay.HudWarningDisplayData
              DWA_pp_TPMSWarnPayload_TpmsWarningDataData: accessed-variable=pp_TPMSWarnPayload.TpmsWarningDataData
              DWA_pp_WarnHighInt_WarningHighInterrupt_State: accessed-variable=pp_WarnHighInt.WarningHighInterrupt_State
              DWA_pp_WarnInt_WarningInterrupt_State: accessed-variable=pp_WarnInt.WarningInterrupt_State
              DWA_pp_WarningDisplay_WarningDisplayData: accessed-variable=pp_WarningDisplay.WarningDisplayData
          10 x sync call, all with timeout=0.0:
            OA_rpActiveWarningStatus_GetActiveWarningStatus: operation=rpActiveWarningStatus.GetActiveWarningStatus
            OA_rp_ActiveWarningSts_GetWarningActiveStatus: operation=rp_ActiveWarningSts.GetWarningActiveStatus
            OA_rp_CS_TxCanMdl_TxCan_ClearCanSignalTxConfirmation: operation=rp_CS_TxCanMdl.TxCan_ClearCanSignalTxConfirmation
            OA_rp_CS_TxCanMdl_TxCan_GetCanSignalTxConfirmation: operation=rp_CS_TxCanMdl.TxCan_GetCanSignalTxConfirmation
            OA_rp_CS_TxCanMdl_TxCan_SetSignalFromRetentionBuffer: operation=rp_CS_TxCanMdl.TxCan_SetSignalFromRetentionBuffer
            OA_rp_CS_TxCanMdl_TxCan_SetSignalValue: operation=rp_CS_TxCanMdl.TxCan_SetSignalValue
            OA_rp_CS_TxCanMdl_TxCan_SetSignalValueU8Arr: operation=rp_CS_TxCanMdl.TxCan_SetSignalValueU8Arr
            OA_rp_UpdateDisplayPayload_SetWarningDisplayedPayload: operation=rp_UpdateDisplayPayload.SetWarningDisplayedPayload
            OA_rp_UpdateDisplayStatus_SetWarningDisplayedStatus: operation=rp_UpdateDisplayStatus.SetWarningDisplayedStatus
            OA_rp_VoiceOpButtonSts_GetButtonStatus: operation=rp_VoiceOpButtonSts.GetButtonStatus
        OnDre_UCL_WarnStatus
          data-receive-point-by-arguments:
            16 x access:
              DRA_rpCS_ChimeRequest_Chime_Request: accessed-variable=rpCS_ChimeRequest.Chime_Request
              DRA_rpCS_GetChimeStatus_Chime_Status: accessed-variable=rpCS_GetChimeStatus.Chime_Status
              DRA_rpIgnSubstate_IgnitionSubstate: accessed-variable=rpIgnSubstate.IgnitionSubstate
              DRA_rp_ClusterMode_WSSCurrentClusterMode: accessed-variable=rp_ClusterMode.WSSCurrentClusterMode
              DRA_rp_FactoryMode_FactoryMode: accessed-variable=rp_FactoryMode.FactoryMode
              DRA_rp_FactoryModeSts_FactoryModeStatus: accessed-variable=rp_FactoryModeSts.FactoryModeStatus
              DRA_rp_HMIReadySts_HMI_ReadyStatus: accessed-variable=rp_HMIReadySts.HMI_ReadyStatus
              DRA_rp_HMIScreenMode_HMIScreenMode_Status: accessed-variable=rp_HMIScreenMode.HMIScreenMode_Status
              DRA_rp_HUDWakeupHwSts_WakeType_Hw: accessed-variable=rp_HUDWakeupHwSts.WakeType_Hw
              DRA_rp_HUDWakeupSwSts_WakeType_Int: accessed-variable=rp_HUDWakeupSwSts.WakeType_Int
              DRA_rp_HUDWarningStatus_HudWarningStatusData: accessed-variable=rp_HUDWarningStatus.HudWarningStatusData
              DRA_rp_IllumStartSts_StarterStatus_Out: accessed-variable=rp_IllumStartSts.StarterStatus_Out
              DRA_rp_NVM_HUD_CoordinateFlag_NvmData: accessed-variable=rp_NVM_HUD_CoordinateFlag.NvmData
              DRA_rp_TPMSPayload_Tpms_Payload: accessed-variable=rp_TPMSPayload.Tpms_Payload
              DRA_rp_TargetSWStatus_TargetSw: accessed-variable=rp_TargetSWStatus.TargetSw
              DRA_rp_WarningStatus_WarningStatusData: accessed-variable=rp_WarningStatus.WarningStatusData
          data-send-points:
            5 x access:
              DWA_pp_HUDWarningDisplay_HudWarningDisplayData: accessed-variable=pp_HUDWarningDisplay.HudWarningDisplayData
              DWA_pp_TPMSWarnPayload_TpmsWarningDataData: accessed-variable=pp_TPMSWarnPayload.TpmsWarningDataData
              DWA_pp_WarnHighInt_WarningHighInterrupt_State: accessed-variable=pp_WarnHighInt.WarningHighInterrupt_State
              DWA_pp_WarnInt_WarningInterrupt_State: accessed-variable=pp_WarnInt.WarningInterrupt_State
              DWA_pp_WarningDisplay_WarningDisplayData: accessed-variable=pp_WarningDisplay.WarningDisplayData
          10 x sync call, all with timeout=0.0:
            OA_rpActiveWarningStatus_GetActiveWarningStatus: operation=rpActiveWarningStatus.GetActiveWarningStatus
            OA_rp_ActiveWarningSts_GetWarningActiveStatus: operation=rp_ActiveWarningSts.GetWarningActiveStatus
            OA_rp_CS_TxCanMdl_TxCan_ClearCanSignalTxConfirmation: operation=rp_CS_TxCanMdl.TxCan_ClearCanSignalTxConfirmation
            OA_rp_CS_TxCanMdl_TxCan_GetCanSignalTxConfirmation: operation=rp_CS_TxCanMdl.TxCan_GetCanSignalTxConfirmation
            OA_rp_CS_TxCanMdl_TxCan_SetSignalFromRetentionBuffer: operation=rp_CS_TxCanMdl.TxCan_SetSignalFromRetentionBuffer
            OA_rp_CS_TxCanMdl_TxCan_SetSignalValue: operation=rp_CS_TxCanMdl.TxCan_SetSignalValue
            OA_rp_CS_TxCanMdl_TxCan_SetSignalValueU8Arr: operation=rp_CS_TxCanMdl.TxCan_SetSignalValueU8Arr
            OA_rp_UpdateDisplayPayload_SetWarningDisplayedPayload: operation=rp_UpdateDisplayPayload.SetWarningDisplayedPayload
            OA_rp_UpdateDisplayStatus_SetWarningDisplayedStatus: operation=rp_UpdateDisplayStatus.SetWarningDisplayedStatus
            OA_rp_VoiceOpButtonSts_GetButtonStatus: operation=rp_VoiceOpButtonSts.GetButtonStatus
        CWarnMsg_Core_Observer_SW_NoOperationTimer
          data-receive-point-by-arguments:
            16 x access:
              DRA_rpCS_ChimeRequest_Chime_Request: accessed-variable=rpCS_ChimeRequest.Chime_Request
              DRA_rpCS_GetChimeStatus_Chime_Status: accessed-variable=rpCS_GetChimeStatus.Chime_Status
              DRA_rpIgnSubstate_IgnitionSubstate: accessed-variable=rpIgnSubstate.IgnitionSubstate
              DRA_rp_ClusterMode_WSSCurrentClusterMode: accessed-variable=rp_ClusterMode.WSSCurrentClusterMode
              DRA_rp_FactoryMode_FactoryMode: accessed-variable=rp_FactoryMode.FactoryMode
              DRA_rp_FactoryModeSts_FactoryModeStatus: accessed-variable=rp_FactoryModeSts.FactoryModeStatus
              DRA_rp_HMIReadySts_HMI_ReadyStatus: accessed-variable=rp_HMIReadySts.HMI_ReadyStatus
              DRA_rp_HMIScreenMode_HMIScreenMode_Status: accessed-variable=rp_HMIScreenMode.HMIScreenMode_Status
              DRA_rp_HUDWakeupHwSts_WakeType_Hw: accessed-variable=rp_HUDWakeupHwSts.WakeType_Hw
              DRA_rp_HUDWakeupSwSts_WakeType_Int: accessed-variable=rp_HUDWakeupSwSts.WakeType_Int
              DRA_rp_HUDWarningStatus_HudWarningStatusData: accessed-variable=rp_HUDWarningStatus.HudWarningStatusData
              DRA_rp_IllumStartSts_StarterStatus_Out: accessed-variable=rp_IllumStartSts.StarterStatus_Out
              DRA_rp_NVM_HUD_CoordinateFlag_NvmData: accessed-variable=rp_NVM_HUD_CoordinateFlag.NvmData
              DRA_rp_TPMSPayload_Tpms_Payload: accessed-variable=rp_TPMSPayload.Tpms_Payload
              DRA_rp_TargetSWStatus_TargetSw: accessed-variable=rp_TargetSWStatus.TargetSw
              DRA_rp_WarningStatus_WarningStatusData: accessed-variable=rp_WarningStatus.WarningStatusData
          data-send-points:
            5 x access:
              DWA_pp_HUDWarningDisplay_HudWarningDisplayData: accessed-variable=pp_HUDWarningDisplay.HudWarningDisplayData
              DWA_pp_TPMSWarnPayload_TpmsWarningDataData: accessed-variable=pp_TPMSWarnPayload.TpmsWarningDataData
              DWA_pp_WarnHighInt_WarningHighInterrupt_State: accessed-variable=pp_WarnHighInt.WarningHighInterrupt_State
              DWA_pp_WarnInt_WarningInterrupt_State: accessed-variable=pp_WarnInt.WarningInterrupt_State
              DWA_pp_WarningDisplay_WarningDisplayData: accessed-variable=pp_WarningDisplay.WarningDisplayData
          10 x sync call, all with timeout=0.0:
            OA_rpActiveWarningStatus_GetActiveWarningStatus: operation=rpActiveWarningStatus.GetActiveWarningStatus
            OA_rp_ActiveWarningSts_GetWarningActiveStatus: operation=rp_ActiveWarningSts.GetWarningActiveStatus
            OA_rp_CS_TxCanMdl_TxCan_ClearCanSignalTxConfirmation: operation=rp_CS_TxCanMdl.TxCan_ClearCanSignalTxConfirmation
            OA_rp_CS_TxCanMdl_TxCan_GetCanSignalTxConfirmation: operation=rp_CS_TxCanMdl.TxCan_GetCanSignalTxConfirmation
            OA_rp_CS_TxCanMdl_TxCan_SetSignalFromRetentionBuffer: operation=rp_CS_TxCanMdl.TxCan_SetSignalFromRetentionBuffer
            OA_rp_CS_TxCanMdl_TxCan_SetSignalValue: operation=rp_CS_TxCanMdl.TxCan_SetSignalValue
            OA_rp_CS_TxCanMdl_TxCan_SetSignalValueU8Arr: operation=rp_CS_TxCanMdl.TxCan_SetSignalValueU8Arr
            OA_rp_UpdateDisplayPayload_SetWarningDisplayedPayload: operation=rp_UpdateDisplayPayload.SetWarningDisplayedPayload
            OA_rp_UpdateDisplayStatus_SetWarningDisplayedStatus: operation=rp_UpdateDisplayStatus.SetWarningDisplayedStatus
            OA_rp_VoiceOpButtonSts_GetButtonStatus: operation=rp_VoiceOpButtonSts.GetButtonStatus
